[part 8 of 12: package /E40_Platform_System_SystemPackage/Components]
AUTOSAR XML (schema 4-2-1)
package /E40_Platform_System_SystemPackage/Components  (continued)
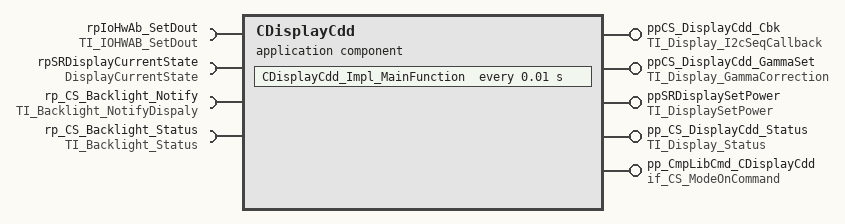
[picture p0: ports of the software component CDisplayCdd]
  application sw component type CDisplayCdd
    5 x provide port:
      ppCS_DisplayCdd_Cbk: server-com-spec{operation=I2cSeqEndCallback, queue-length=1}, provided-interface=TI_Display_I2cSeqCallback
      ppCS_DisplayCdd_GammaSet: provided-com-specs=[{operation=GetGammaCorrectionStatus, queue-length=1}, {operation=SetGammaCorrection, queue-length=1}], provided-interface=TI_Display_GammaCorrection
      ppSRDisplaySetPower: nonqueued-sender-com-spec{data-element=TI_DisplaySetPower/DisplaySetPowerData, init-value=constant-reference=CDisplayCddDisplaySetPowerDataValue0}, provided-interface=TI_DisplaySetPower
      pp_CS_DisplayCdd_Status: provided-com-specs=[{operation=TI_Display_Status/GetStatus, queue-length=1}, {operation=SetState, queue-length=1}], provided-interface=TI_Display_Status
      pp_CmpLibCmd_CDisplayCdd: server-com-spec{operation=Impl_OnCommand, queue-length=1}, provided-interface=if_CS_ModeOnCommand
    4 x require port:
      rpIoHwAb_SetDout: required-interface=TI_IOHWAB_SetDout
      rpSRDisplayCurrentState: nonqueued-receiver-com-spec{data-element=DisplayCurrentStateData, init-value=constant-reference=CDisplayCddDisplayCurrentStateDataValue0}, required-interface=DisplayCurrentState
      rp_CS_Backlight_Notify: required-interface=TI_Backlight_NotifyDispaly
      rp_CS_Backlight_Status: required-interface=TI_Backlight_Status
    behavior IB_CDisplayCdd
      operation invoked event OIE_ppCS_DisplayCdd_GammaSet_CDisplayCdd_GetGammaCorrectionStatusTrigByGetGammaCorrectionStatus: start-on-event=CDisplayCdd_GetGammaCorrectionStatus, operation=ppCS_DisplayCdd_GammaSet.GetGammaCorrectionStatus
      operation invoked event OIE_pp_CS_DisplayCdd_Status_CDisplayCdd_GetStatusTrigByGetStatus: start-on-event=CDisplayCdd_GetStatus, operation=pp_CS_DisplayCdd_Status.GetStatus
      operation invoked event OIE_ppCS_DisplayCdd_Cbk_CDisplayCdd_I2cSeqEndCallbackTrigByI2cSeqEndCallback: start-on-event=CDisplayCdd_I2cSeqEndCallback, operation=ppCS_DisplayCdd_Cbk.I2cSeqEndCallback
      timing event TECDisplayCdd_Impl_MainFunction: start-on-event=CDisplayCdd_Impl_MainFunction, period=0.01
      operation invoked event OIE_pp_CmpLibCmd_CDisplayCdd_CDisplayCdd_Impl_OnCommandTrigByImpl_OnCommand: start-on-event=CDisplayCdd_Impl_OnCommand, operation=pp_CmpLibCmd_CDisplayCdd.Impl_OnCommand
      operation invoked event OIE_ppCS_DisplayCdd_GammaSet_CDisplayCdd_SetGammaCorrectionTrigBySetGammaCorrection: start-on-event=CDisplayCdd_SetGammaCorrection, operation=ppCS_DisplayCdd_GammaSet.SetGammaCorrection
      operation invoked event OIE_pp_CS_DisplayCdd_Status_CDisplayCdd_SetStateTrigBySetState: start-on-event=CDisplayCdd_SetState, operation=pp_CS_DisplayCdd_Status.SetState
      port-api-options:
        enable-take-address=false, indirect-api=false, port=ppCS_DisplayCdd_Cbk
        enable-take-address=false, indirect-api=false, port=ppCS_DisplayCdd_GammaSet
        enable-take-address=false, indirect-api=false, port=ppSRDisplaySetPower
        enable-take-address=false, indirect-api=false, port=pp_CS_DisplayCdd_Status
        enable-take-address=false, indirect-api=false, port=pp_CmpLibCmd_CDisplayCdd
        enable-take-address=false, indirect-api=false, port=rpIoHwAb_SetDout
        enable-take-address=false, indirect-api=false, port=rpSRDisplayCurrentState
        enable-take-address=false, indirect-api=false, port=rp_CS_Backlight_Notify
        enable-take-address=false, indirect-api=false, port=rp_CS_Backlight_Status
      7 x runnable, all with can-be-invoked-concurrently=true:
        CDisplayCdd_GetGammaCorrectionStatus
        CDisplayCdd_GetStatus
          data-receive-point-by-arguments:
            access DRA_rpSRDisplayCurrentState_DisplayCurrentStateData: accessed-variable=rpSRDisplayCurrentState.DisplayCurrentStateData
          data-send-points:
            access DWA_ppSRDisplaySetPower_DisplaySetPowerData: accessed-variable=ppSRDisplaySetPower.DisplaySetPowerData
          4 x sync call, all with timeout=0.0:
            OA_rpIoHwAb_SetDout_SetOutputGroup: operation=rpIoHwAb_SetDout.SetOutputGroup
            OA_rpIoHwAb_SetDout_SetOutputPin: operation=rpIoHwAb_SetDout.SetOutputPin
            OA_rp_CS_Backlight_Notify_NotifyDisplayPowerState: operation=rp_CS_Backlight_Notify.NotifyDisplayPowerState
            OA_rp_CS_Backlight_Status_GetStatus: operation=rp_CS_Backlight_Status.GetStatus
        CDisplayCdd_I2cSeqEndCallback
        CDisplayCdd_Impl_MainFunction
          data-receive-point-by-arguments:
            access DRA_rpSRDisplayCurrentState_DisplayCurrentStateData: accessed-variable=rpSRDisplayCurrentState.DisplayCurrentStateData
          data-send-points:
            access DWA_ppSRDisplaySetPower_DisplaySetPowerData: accessed-variable=ppSRDisplaySetPower.DisplaySetPowerData
          4 x sync call, all with timeout=0.0:
            OA_rpIoHwAb_SetDout_SetOutputGroup: operation=rpIoHwAb_SetDout.SetOutputGroup
            OA_rpIoHwAb_SetDout_SetOutputPin: operation=rpIoHwAb_SetDout.SetOutputPin
            OA_rp_CS_Backlight_Notify_NotifyDisplayPowerState: operation=rp_CS_Backlight_Notify.NotifyDisplayPowerState
            OA_rp_CS_Backlight_Status_GetStatus: operation=rp_CS_Backlight_Status.GetStatus
        CDisplayCdd_Impl_OnCommand
          data-receive-point-by-arguments:
            access DRA_rpSRDisplayCurrentState_DisplayCurrentStateData: accessed-variable=rpSRDisplayCurrentState.DisplayCurrentStateData
          data-send-points:
            access DWA_ppSRDisplaySetPower_DisplaySetPowerData: accessed-variable=ppSRDisplaySetPower.DisplaySetPowerData
          4 x sync call, all with timeout=0.0:
            OA_rpIoHwAb_SetDout_SetOutputGroup: operation=rpIoHwAb_SetDout.SetOutputGroup
            OA_rpIoHwAb_SetDout_SetOutputPin: operation=rpIoHwAb_SetDout.SetOutputPin
            OA_rp_CS_Backlight_Notify_NotifyDisplayPowerState: operation=rp_CS_Backlight_Notify.NotifyDisplayPowerState
            OA_rp_CS_Backlight_Status_GetStatus: operation=rp_CS_Backlight_Status.GetStatus
        CDisplayCdd_SetGammaCorrection
        CDisplayCdd_SetState
          data-receive-point-by-arguments:
            access DRA_rpSRDisplayCurrentState_DisplayCurrentStateData: accessed-variable=rpSRDisplayCurrentState.DisplayCurrentStateData
          data-send-points:
            access DWA_ppSRDisplaySetPower_DisplaySetPowerData: accessed-variable=ppSRDisplaySetPower.DisplaySetPowerData
          4 x sync call, all with timeout=0.0:
            OA_rpIoHwAb_SetDout_SetOutputGroup: operation=rpIoHwAb_SetDout.SetOutputGroup
            OA_rpIoHwAb_SetDout_SetOutputPin: operation=rpIoHwAb_SetDout.SetOutputPin
            OA_rp_CS_Backlight_Notify_NotifyDisplayPowerState: operation=rp_CS_Backlight_Notify.NotifyDisplayPowerState
            OA_rp_CS_Backlight_Status_GetStatus: operation=rp_CS_Backlight_Status.GetStatus
  constant specification CDisplayCddDisplaySetPowerDataValue0: value-spec={short-label=CDisplayCddDisplaySetPowerDataValue0, fields=[CDisplayCddDisplaySetPowerDataValue_0:0, CDisplayCddDisplaySetPowerDataValue_1:0]}
  constant specification CDisplayCddDisplayCurrentStateDataValue0: value-spec={short-label=CDisplayCddDisplayCurrentStateDataValue0, fields=[CDisplayCddDisplayCurrentStateDataValue_0:0, CDisplayCddDisplayCurrentStateDataValue_1:0]}
  swc implementation IMPL_CDisplayCdd: programming-language=C, behavior=IB_CDisplayCdd
    code-descriptors:
      code CodeDescriptor
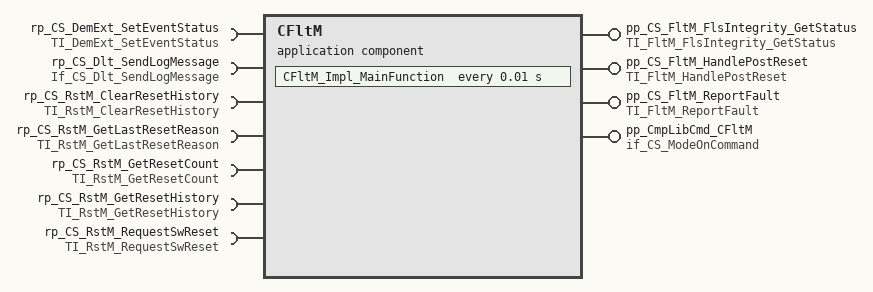
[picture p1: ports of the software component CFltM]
  application sw component type CFltM
    4 x provide port:
      pp_CS_FltM_FlsIntegrity_GetStatus: server-com-spec{operation=FltM_FlsIntegrity_GetStatus, queue-length=1}, provided-interface=TI_FltM_FlsIntegrity_GetStatus
      pp_CS_FltM_HandlePostReset: server-com-spec{operation=FltM_HandlePostReset, queue-length=1}, provided-interface=TI_FltM_HandlePostReset
      pp_CS_FltM_ReportFault: server-com-spec{operation=FltM_ReportFault, queue-length=1}, provided-interface=TI_FltM_ReportFault
      pp_CmpLibCmd_CFltM: server-com-spec{operation=Impl_OnCommand, queue-length=1}, provided-interface=if_CS_ModeOnCommand
    7 x require port:
      rp_CS_DemExt_SetEventStatus: required-interface=TI_DemExt_SetEventStatus
      rp_CS_Dlt_SendLogMessage: required-interface=If_CS_Dlt_SendLogMessage
      rp_CS_RstM_ClearResetHistory: required-interface=TI_RstM_ClearResetHistory
      rp_CS_RstM_GetLastResetReason: required-interface=TI_RstM_GetLastResetReason
      rp_CS_RstM_GetResetCount: required-interface=TI_RstM_GetResetCount
      rp_CS_RstM_GetResetHistory: required-interface=TI_RstM_GetResetHistory
      rp_CS_RstM_RequestSwReset: required-interface=TI_RstM_RequestSwReset
    behavior IB_CFltM
      operation invoked event OIE_pp_CS_FltM_FlsIntegrity_GetStatus_FltM_FlsIntegrity_GetStatusTrigByFltM_FlsIntegrity_GetStatus: start-on-event=FltM_FlsIntegrity_GetStatus, operation=pp_CS_FltM_FlsIntegrity_GetStatus.FltM_FlsIntegrity_GetStatus
      operation invoked event OIE_pp_CS_FltM_HandlePostReset_FltM_HandlePostResetTrigByFltM_HandlePostReset: start-on-event=FltM_HandlePostReset, operation=pp_CS_FltM_HandlePostReset.FltM_HandlePostReset
      operation invoked event OIE_pp_CS_FltM_ReportFault_FltM_ReportFaultTrigByFltM_ReportFault: start-on-event=FltM_ReportFault, operation=pp_CS_FltM_ReportFault.FltM_ReportFault
      timing event TECFltM_Impl_MainFunction: start-on-event=CFltM_Impl_MainFunction, period=0.01
      operation invoked event OIE_pp_CmpLibCmd_CFltM_CFltM_Impl_OnCommandTrigByImpl_OnCommand: start-on-event=CFltM_Impl_OnCommand, operation=pp_CmpLibCmd_CFltM.Impl_OnCommand
      port-api-options:
        enable-take-address=false, indirect-api=false, port=pp_CS_FltM_FlsIntegrity_GetStatus
        enable-take-address=false, indirect-api=false, port=pp_CS_FltM_HandlePostReset
        enable-take-address=false, indirect-api=false, port=pp_CS_FltM_ReportFault
        enable-take-address=false, indirect-api=false, port=pp_CmpLibCmd_CFltM
        enable-take-address=false, indirect-api=false, port=CFltM/rp_CS_DemExt_SetEventStatus
        enable-take-address=false, indirect-api=false, port=CFltM/rp_CS_Dlt_SendLogMessage
        enable-take-address=false, indirect-api=false, port=rp_CS_RstM_ClearResetHistory
        enable-take-address=false, indirect-api=false, port=rp_CS_RstM_GetLastResetReason
        enable-take-address=false, indirect-api=false, port=rp_CS_RstM_GetResetCount
        enable-take-address=false, indirect-api=false, port=rp_CS_RstM_GetResetHistory
        enable-take-address=false, indirect-api=false, port=rp_CS_RstM_RequestSwReset
      5 x runnable, all with can-be-invoked-concurrently=true:
        FltM_FlsIntegrity_GetStatus
          6 x sync call, all with timeout=0.0:
            OA_rp_CS_DemExt_SetEventStatus_DemExt_SetEventStatus: operation=rp_CS_DemExt_SetEventStatus.DemExt_SetEventStatus
            OA_rp_CS_RstM_ClearResetHistory_RstM_ClearResetHistory: operation=rp_CS_RstM_ClearResetHistory.RstM_ClearResetHistory
            OA_rp_CS_RstM_GetLastResetReason_RstM_GetLastResetReason: operation=rp_CS_RstM_GetLastResetReason.RstM_GetLastResetReason
            OA_rp_CS_RstM_GetResetCount_RstM_GetResetCount: operation=rp_CS_RstM_GetResetCount.RstM_GetResetCount
            OA_rp_CS_RstM_GetResetHistory_RstM_GetResetHistory: operation=rp_CS_RstM_GetResetHistory.RstM_GetResetHistory
            OA_rp_CS_RstM_RequestSwReset_RstM_RequestSwReset: operation=rp_CS_RstM_RequestSwReset.RstM_RequestSwReset
        FltM_HandlePostReset
          6 x sync call, all with timeout=0.0:
            OA_rp_CS_DemExt_SetEventStatus_DemExt_SetEventStatus: operation=rp_CS_DemExt_SetEventStatus.DemExt_SetEventStatus
            OA_rp_CS_RstM_ClearResetHistory_RstM_ClearResetHistory: operation=rp_CS_RstM_ClearResetHistory.RstM_ClearResetHistory
            OA_rp_CS_RstM_GetLastResetReason_RstM_GetLastResetReason: operation=rp_CS_RstM_GetLastResetReason.RstM_GetLastResetReason
            OA_rp_CS_RstM_GetResetCount_RstM_GetResetCount: operation=rp_CS_RstM_GetResetCount.RstM_GetResetCount
            OA_rp_CS_RstM_GetResetHistory_RstM_GetResetHistory: operation=rp_CS_RstM_GetResetHistory.RstM_GetResetHistory
            OA_rp_CS_RstM_RequestSwReset_RstM_RequestSwReset: operation=rp_CS_RstM_RequestSwReset.RstM_RequestSwReset
        FltM_ReportFault
          6 x sync call, all with timeout=0.0:
            OA_rp_CS_DemExt_SetEventStatus_DemExt_SetEventStatus: operation=rp_CS_DemExt_SetEventStatus.DemExt_SetEventStatus
            OA_rp_CS_RstM_ClearResetHistory_RstM_ClearResetHistory: operation=rp_CS_RstM_ClearResetHistory.RstM_ClearResetHistory
            OA_rp_CS_RstM_GetLastResetReason_RstM_GetLastResetReason: operation=rp_CS_RstM_GetLastResetReason.RstM_GetLastResetReason
            OA_rp_CS_RstM_GetResetCount_RstM_GetResetCount: operation=rp_CS_RstM_GetResetCount.RstM_GetResetCount
            OA_rp_CS_RstM_GetResetHistory_RstM_GetResetHistory: operation=rp_CS_RstM_GetResetHistory.RstM_GetResetHistory
            OA_rp_CS_RstM_RequestSwReset_RstM_RequestSwReset: operation=rp_CS_RstM_RequestSwReset.RstM_RequestSwReset
        CFltM_Impl_MainFunction
          6 x sync call, all with timeout=0.0:
            OA_rp_CS_DemExt_SetEventStatus_DemExt_SetEventStatus: operation=rp_CS_DemExt_SetEventStatus.DemExt_SetEventStatus
            OA_rp_CS_RstM_ClearResetHistory_RstM_ClearResetHistory: operation=rp_CS_RstM_ClearResetHistory.RstM_ClearResetHistory
            OA_rp_CS_RstM_GetLastResetReason_RstM_GetLastResetReason: operation=rp_CS_RstM_GetLastResetReason.RstM_GetLastResetReason
            OA_rp_CS_RstM_GetResetCount_RstM_GetResetCount: operation=rp_CS_RstM_GetResetCount.RstM_GetResetCount
            OA_rp_CS_RstM_GetResetHistory_RstM_GetResetHistory: operation=rp_CS_RstM_GetResetHistory.RstM_GetResetHistory
            OA_rp_CS_RstM_RequestSwReset_RstM_RequestSwReset: operation=rp_CS_RstM_RequestSwReset.RstM_RequestSwReset
        CFltM_Impl_OnCommand
          6 x sync call, all with timeout=0.0:
            OA_rp_CS_DemExt_SetEventStatus_DemExt_SetEventStatus: operation=rp_CS_DemExt_SetEventStatus.DemExt_SetEventStatus
            OA_rp_CS_RstM_ClearResetHistory_RstM_ClearResetHistory: operation=rp_CS_RstM_ClearResetHistory.RstM_ClearResetHistory
            OA_rp_CS_RstM_GetLastResetReason_RstM_GetLastResetReason: operation=rp_CS_RstM_GetLastResetReason.RstM_GetLastResetReason
            OA_rp_CS_RstM_GetResetCount_RstM_GetResetCount: operation=rp_CS_RstM_GetResetCount.RstM_GetResetCount
            OA_rp_CS_RstM_GetResetHistory_RstM_GetResetHistory: operation=rp_CS_RstM_GetResetHistory.RstM_GetResetHistory
            OA_rp_CS_RstM_RequestSwReset_RstM_RequestSwReset: operation=rp_CS_RstM_RequestSwReset.RstM_RequestSwReset
  swc implementation IMPL_CFltM: programming-language=C, behavior=IB_CFltM
    code-descriptors:
      code CodeDescriptor
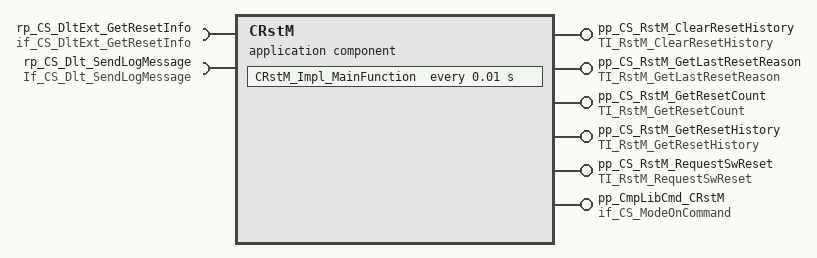
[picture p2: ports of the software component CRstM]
  application sw component type CRstM
    6 x provide port:
      pp_CS_RstM_ClearResetHistory: server-com-spec{operation=RstM_ClearResetHistory, queue-length=1}, provided-interface=TI_RstM_ClearResetHistory
      pp_CS_RstM_GetLastResetReason: server-com-spec{operation=RstM_GetLastResetReason, queue-length=1}, provided-interface=TI_RstM_GetLastResetReason
      pp_CS_RstM_GetResetCount: server-com-spec{operation=RstM_GetResetCount, queue-length=1}, provided-interface=TI_RstM_GetResetCount
      pp_CS_RstM_GetResetHistory: server-com-spec{operation=RstM_GetResetHistory, queue-length=1}, provided-interface=TI_RstM_GetResetHistory
      pp_CS_RstM_RequestSwReset: server-com-spec{operation=RstM_RequestSwReset, queue-length=1}, provided-interface=TI_RstM_RequestSwReset
      pp_CmpLibCmd_CRstM: server-com-spec{operation=Impl_OnCommand, queue-length=1}, provided-interface=if_CS_ModeOnCommand
    require port rp_CS_DltExt_GetResetInfo: required-interface=if_CS_DltExt_GetResetInfo
    require port rp_CS_Dlt_SendLogMessage: required-interface=If_CS_Dlt_SendLogMessage
    behavior IB_CRstM
      timing event TECRstM_Impl_MainFunction: start-on-event=CRstM_Impl_MainFunction, period=0.01
      6 x operation invoked event:
        OIE_pp_CmpLibCmd_CRstM_CRstM_Impl_OnCommandTrigByImpl_OnCommand: start-on-event=CRstM_Impl_OnCommand, operation=pp_CmpLibCmd_CRstM.Impl_OnCommand
        OIE_pp_CS_RstM_ClearResetHistory_RstM_ClearResetHistoryTrigByRstM_ClearResetHistory: start-on-event=RstM_ClearResetHistory, operation=pp_CS_RstM_ClearResetHistory.RstM_ClearResetHistory
        OIE_pp_CS_RstM_GetLastResetReason_RstM_GetLastResetReasonTrigByRstM_GetLastResetReason: start-on-event=RstM_GetLastResetReason, operation=pp_CS_RstM_GetLastResetReason.RstM_GetLastResetReason
        OIE_pp_CS_RstM_GetResetCount_RstM_GetResetCountTrigByRstM_GetResetCount: start-on-event=RstM_GetResetCount, operation=pp_CS_RstM_GetResetCount.RstM_GetResetCount
        OIE_pp_CS_RstM_GetResetHistory_RstM_GetResetHistoryTrigByRstM_GetResetHistory: start-on-event=RstM_GetResetHistory, operation=pp_CS_RstM_GetResetHistory.RstM_GetResetHistory
        OIE_pp_CS_RstM_RequestSwReset_RstM_RequestSwResetTrigByRstM_RequestSwReset: start-on-event=RstM_RequestSwReset, operation=pp_CS_RstM_RequestSwReset.RstM_RequestSwReset
      port-api-options:
        enable-take-address=false, indirect-api=false, port=pp_CS_RstM_ClearResetHistory
        enable-take-address=false, indirect-api=false, port=pp_CS_RstM_GetLastResetReason
        enable-take-address=false, indirect-api=false, port=pp_CS_RstM_GetResetCount
        enable-take-address=false, indirect-api=false, port=pp_CS_RstM_GetResetHistory
        enable-take-address=false, indirect-api=false, port=pp_CS_RstM_RequestSwReset
        enable-take-address=false, indirect-api=false, port=pp_CmpLibCmd_CRstM
        enable-take-address=false, indirect-api=false, port=rp_CS_DltExt_GetResetInfo
        enable-take-address=false, indirect-api=false, port=CRstM/rp_CS_Dlt_SendLogMessage
      7 x runnable, all with can-be-invoked-concurrently=true:
        CRstM_Impl_MainFunction
        CRstM_Impl_OnCommand
        RstM_ClearResetHistory
        RstM_GetLastResetReason
        RstM_GetResetCount
        RstM_GetResetHistory
        RstM_RequestSwReset
  swc implementation IMPL_CRstM: programming-language=C, behavior=IB_CRstM
    code-descriptors:
      code CodeDescriptor
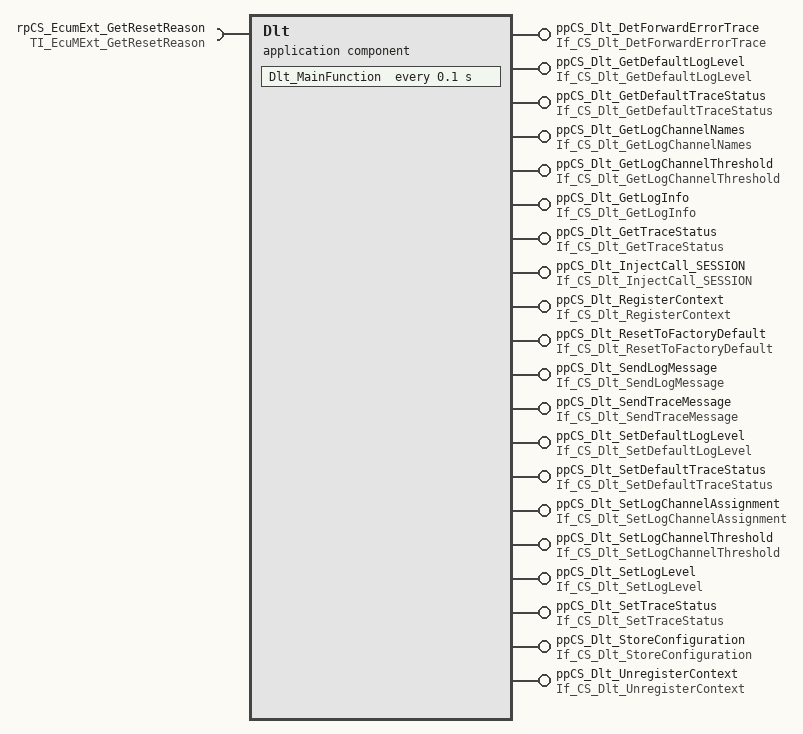
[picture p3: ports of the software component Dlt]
  application sw component type Dlt
    20 x provide port:
      ppCS_Dlt_DetForwardErrorTrace: server-com-spec{operation=DetForwardErrorTrace, queue-length=1}, provided-interface=If_CS_Dlt_DetForwardErrorTrace
      ppCS_Dlt_GetDefaultLogLevel: server-com-spec{operation=GetDefaultLogLevel, queue-length=1}, provided-interface=If_CS_Dlt_GetDefaultLogLevel
      ppCS_Dlt_GetDefaultTraceStatus: server-com-spec{operation=GetDefaultTraceStatus, queue-length=1}, provided-interface=If_CS_Dlt_GetDefaultTraceStatus
      ppCS_Dlt_GetLogChannelNames: server-com-spec{operation=GetLogChannelNames, queue-length=1}, provided-interface=If_CS_Dlt_GetLogChannelNames
      ppCS_Dlt_GetLogChannelThreshold: server-com-spec{operation=GetLogChannelThreshold, queue-length=1}, provided-interface=If_CS_Dlt_GetLogChannelThreshold
      ppCS_Dlt_GetLogInfo: server-com-spec{operation=GetLogInfo, queue-length=1}, provided-interface=If_CS_Dlt_GetLogInfo
      ppCS_Dlt_GetTraceStatus: server-com-spec{operation=GetTraceStatus, queue-length=1}, provided-interface=If_CS_Dlt_GetTraceStatus
      ppCS_Dlt_InjectCall_SESSION: server-com-spec{operation=InjectCall_SESSION, queue-length=1}, provided-interface=If_CS_Dlt_InjectCall_SESSION
      ppCS_Dlt_RegisterContext: server-com-spec{operation=RegisterContext, queue-length=1}, provided-interface=If_CS_Dlt_RegisterContext
      ppCS_Dlt_ResetToFactoryDefault: server-com-spec{operation=ResetToFactoryDefault, queue-length=1}, provided-interface=If_CS_Dlt_ResetToFactoryDefault
      ppCS_Dlt_SendLogMessage: server-com-spec{operation=If_CS_Dlt_SendLogMessage/SendLogMessage, queue-length=1}, provided-interface=If_CS_Dlt_SendLogMessage
      ppCS_Dlt_SendTraceMessage: server-com-spec{operation=SendTraceMessage, queue-length=1}, provided-interface=If_CS_Dlt_SendTraceMessage
      ppCS_Dlt_SetDefaultLogLevel: server-com-spec{operation=SetDefaultLogLevel, queue-length=1}, provided-interface=If_CS_Dlt_SetDefaultLogLevel
      ppCS_Dlt_SetDefaultTraceStatus: server-com-spec{operation=SetDefaultTraceStatus, queue-length=1}, provided-interface=If_CS_Dlt_SetDefaultTraceStatus
      ppCS_Dlt_SetLogChannelAssignment: server-com-spec{operation=SetLogChannelAssignment, queue-length=1}, provided-interface=If_CS_Dlt_SetLogChannelAssignment
      ppCS_Dlt_SetLogChannelThreshold: server-com-spec{operation=SetLogChannelThreshold, queue-length=1}, provided-interface=If_CS_Dlt_SetLogChannelThreshold
      ppCS_Dlt_SetLogLevel: server-com-spec{operation=SetLogLevel, queue-length=1}, provided-interface=If_CS_Dlt_SetLogLevel
      ppCS_Dlt_SetTraceStatus: server-com-spec{operation=SetTraceStatus, queue-length=1}, provided-interface=If_CS_Dlt_SetTraceStatus
      ppCS_Dlt_StoreConfiguration: server-com-spec{operation=StoreConfiguration, queue-length=1}, provided-interface=If_CS_Dlt_StoreConfiguration
      ppCS_Dlt_UnregisterContext: server-com-spec{operation=UnregisterContext, queue-length=1}, provided-interface=If_CS_Dlt_UnregisterContext
    require port rpCS_EcumExt_GetResetReason: required-interface=TI_EcuMExt_GetResetReason
    behavior IB_Dlt
      8 x operation invoked event:
        OIE_ppCS_Dlt_DetForwardErrorTrace_Dlt_DetForwardErrorTraceTrigByDetForwardErrorTrace: start-on-event=Dlt_DetForwardErrorTrace, operation=ppCS_Dlt_DetForwardErrorTrace.DetForwardErrorTrace
        OIE_ppCS_Dlt_GetDefaultLogLevel_Dlt_GetDefaultLogLevelTrigByGetDefaultLogLevel: start-on-event=Dlt_GetDefaultLogLevel, operation=ppCS_Dlt_GetDefaultLogLevel.GetDefaultLogLevel
        OIE_ppCS_Dlt_GetDefaultTraceStatus_Dlt_GetDefaultTraceStatusTrigByGetDefaultTraceStatus: start-on-event=Dlt_GetDefaultTraceStatus, operation=ppCS_Dlt_GetDefaultTraceStatus.GetDefaultTraceStatus
        OIE_ppCS_Dlt_GetLogChannelNames_Dlt_GetLogChannelNamesTrigByGetLogChannelNames: start-on-event=Dlt_GetLogChannelNames, operation=ppCS_Dlt_GetLogChannelNames.GetLogChannelNames
        OIE_ppCS_Dlt_GetLogChannelThreshold_Dlt_GetLogChannelThresholdTrigByGetLogChannelThreshold: start-on-event=Dlt_GetLogChannelThreshold, operation=ppCS_Dlt_GetLogChannelThreshold.GetLogChannelThreshold
        OIE_ppCS_Dlt_GetLogInfo_Dlt_GetLogInfoTrigByGetLogInfo: start-on-event=Dlt_GetLogInfo, operation=ppCS_Dlt_GetLogInfo.GetLogInfo
        OIE_ppCS_Dlt_GetTraceStatus_Dlt_GetTraceStatusTrigByGetTraceStatus: start-on-event=Dlt_GetTraceStatus, operation=ppCS_Dlt_GetTraceStatus.GetTraceStatus
        OIE_ppCS_Dlt_InjectCall_SESSION_Dlt_InjectCall_SESSIONTrigByInjectCall_SESSION: start-on-event=Dlt_InjectCall_SESSION, operation=ppCS_Dlt_InjectCall_SESSION.InjectCall_SESSION
      timing event TEDlt_MainFunction: start-on-event=Dlt_MainFunction, period=0.1
      12 x operation invoked event:
        OIE_ppCS_Dlt_RegisterContext_Dlt_RegisterContextTrigByRegisterContext: start-on-event=Dlt_RegisterContext, operation=ppCS_Dlt_RegisterContext.RegisterContext
        OIE_ppCS_Dlt_ResetToFactoryDefault_Dlt_ResetToFactoryDefaultTrigByResetToFactoryDefault: start-on-event=Dlt_ResetToFactoryDefault, operation=ppCS_Dlt_ResetToFactoryDefault.ResetToFactoryDefault
        OIE_ppCS_Dlt_SendLogMessage_Dlt_SendLogMessageTrigBySendLogMessage: start-on-event=Dlt_SendLogMessage, operation=ppCS_Dlt_SendLogMessage.SendLogMessage
        OIE_ppCS_Dlt_SendTraceMessage_Dlt_SendTraceMessageTrigBySendTraceMessage: start-on-event=Dlt_SendTraceMessage, operation=ppCS_Dlt_SendTraceMessage.SendTraceMessage
        OIE_ppCS_Dlt_SetDefaultLogLevel_Dlt_SetDefaultLogLevelTrigBySetDefaultLogLevel: start-on-event=Dlt_SetDefaultLogLevel, operation=ppCS_Dlt_SetDefaultLogLevel.SetDefaultLogLevel
        OIE_ppCS_Dlt_SetDefaultTraceStatus_Dlt_SetDefaultTraceStatusTrigBySetDefaultTraceStatus: start-on-event=Dlt_SetDefaultTraceStatus, operation=ppCS_Dlt_SetDefaultTraceStatus.SetDefaultTraceStatus
        OIE_ppCS_Dlt_SetLogChannelAssignment_Dlt_SetLogChannelAssignmentTrigBySetLogChannelAssignment: start-on-event=Dlt_SetLogChannelAssignment, operation=ppCS_Dlt_SetLogChannelAssignment.SetLogChannelAssignment
        OIE_ppCS_Dlt_SetLogChannelThreshold_Dlt_SetLogChannelThresholdTrigBySetLogChannelThreshold: start-on-event=Dlt_SetLogChannelThreshold, operation=ppCS_Dlt_SetLogChannelThreshold.SetLogChannelThreshold
        OIE_ppCS_Dlt_SetLogLevel_Dlt_SetLogLevelTrigBySetLogLevel: start-on-event=Dlt_SetLogLevel, operation=ppCS_Dlt_SetLogLevel.SetLogLevel
        OIE_ppCS_Dlt_SetTraceStatus_Dlt_SetTraceStatusTrigBySetTraceStatus: start-on-event=Dlt_SetTraceStatus, operation=ppCS_Dlt_SetTraceStatus.SetTraceStatus
        OIE_ppCS_Dlt_StoreConfiguration_Dlt_StoreConfigurationTrigByStoreConfiguration: start-on-event=Dlt_StoreConfiguration, operation=ppCS_Dlt_StoreConfiguration.StoreConfiguration
        OIE_ppCS_Dlt_UnregisterContext_Dlt_UnregisterContextTrigByUnregisterContext: start-on-event=Dlt_UnregisterContext, operation=ppCS_Dlt_UnregisterContext.UnregisterContext
      port-api-options:
        enable-take-address=false, indirect-api=false, port=ppCS_Dlt_DetForwardErrorTrace
        enable-take-address=false, indirect-api=false, port=ppCS_Dlt_GetDefaultLogLevel
        enable-take-address=false, indirect-api=false, port=ppCS_Dlt_GetDefaultTraceStatus
        enable-take-address=false, indirect-api=false, port=ppCS_Dlt_GetLogChannelNames
        enable-take-address=false, indirect-api=false, port=ppCS_Dlt_GetLogChannelThreshold
        enable-take-address=false, indirect-api=false, port=ppCS_Dlt_GetLogInfo
        enable-take-address=false, indirect-api=false, port=ppCS_Dlt_GetTraceStatus
        enable-take-address=false, indirect-api=false, port=ppCS_Dlt_InjectCall_SESSION
        enable-take-address=false, indirect-api=false, port=ppCS_Dlt_RegisterContext
        enable-take-address=false, indirect-api=false, port=ppCS_Dlt_ResetToFactoryDefault
        enable-take-address=false, indirect-api=false, port=ppCS_Dlt_SendLogMessage
        enable-take-address=false, indirect-api=false, port=ppCS_Dlt_SendTraceMessage
        enable-take-address=false, indirect-api=false, port=ppCS_Dlt_SetDefaultLogLevel
        enable-take-address=false, indirect-api=false, port=ppCS_Dlt_SetDefaultTraceStatus
        enable-take-address=false, indirect-api=false, port=ppCS_Dlt_SetLogChannelAssignment
        enable-take-address=false, indirect-api=false, port=ppCS_Dlt_SetLogChannelThreshold
        enable-take-address=false, indirect-api=false, port=ppCS_Dlt_SetLogLevel
        enable-take-address=false, indirect-api=false, port=ppCS_Dlt_SetTraceStatus
        enable-take-address=false, indirect-api=false, port=ppCS_Dlt_StoreConfiguration
        enable-take-address=false, indirect-api=false, port=ppCS_Dlt_UnregisterContext
        enable-take-address=false, indirect-api=false, port=rpCS_EcumExt_GetResetReason
      21 x runnable, all with can-be-invoked-concurrently=true:
        Dlt_DetForwardErrorTrace
        Dlt_GetDefaultLogLevel
        Dlt_GetDefaultTraceStatus
        Dlt_GetLogChannelNames
        Dlt_GetLogChannelThreshold
        Dlt_GetLogInfo
        Dlt_GetTraceStatus
        Dlt_InjectCall_SESSION
        Dlt_MainFunction
          sync call OA_rpCS_EcumExt_GetResetReason_GetResetReason: operation=rpCS_EcumExt_GetResetReason.GetResetReason, timeout=0.0
        Dlt_RegisterContext
        Dlt_ResetToFactoryDefault
        Dlt_SendLogMessage
        Dlt_SendTraceMessage
        Dlt_SetDefaultLogLevel
        Dlt_SetDefaultTraceStatus
        Dlt_SetLogChannelAssignment
        Dlt_SetLogChannelThreshold
        Dlt_SetLogLevel
        Dlt_SetTraceStatus
        Dlt_StoreConfiguration
        Dlt_UnregisterContext
  swc implementation IMPL_Dlt: programming-language=C, behavior=IB_Dlt
    code-descriptors:
      code CodeDescriptor
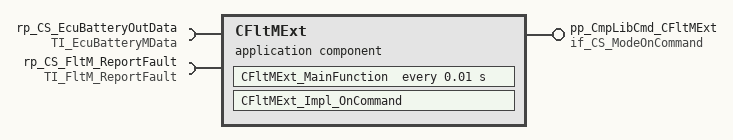
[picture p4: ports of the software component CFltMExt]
  application sw component type CFltMExt
    provide port pp_CmpLibCmd_CFltMExt: server-com-spec{operation=Impl_OnCommand, queue-length=1}, provided-interface=if_CS_ModeOnCommand
    require port rp_CS_EcuBatteryOutData: required-interface=TI_EcuBatteryMData
    require port rp_CS_FltM_ReportFault: required-interface=TI_FltM_ReportFault
    behavior IB_CFltMExt
      operation invoked event OIE_pp_CmpLibCmd_CFltMExt_CFltMExt_Impl_OnCommandTrigByImpl_OnCommand: start-on-event=CFltMExt_Impl_OnCommand, operation=pp_CmpLibCmd_CFltMExt.Impl_OnCommand
      timing event TECFltMExt_MainFunction: start-on-event=CFltMExt_MainFunction, period=0.01
      port-api-options:
        enable-take-address=false, indirect-api=false, port=pp_CmpLibCmd_CFltMExt
        enable-take-address=false, indirect-api=false, port=CFltMExt/rp_CS_EcuBatteryOutData
        enable-take-address=false, indirect-api=false, port=rp_CS_FltM_ReportFault
      runnable CFltMExt_Impl_OnCommand: can-be-invoked-concurrently=true
        sync call OA_rp_CS_EcuBatteryOutData_EcuBatteryM_GetChannelStatus: operation=rp_CS_EcuBatteryOutData.EcuBatteryM_GetChannelStatus, timeout=0.0
        sync call OA_rp_CS_EcuBatteryOutData_EcuBatteryM_GetDIOStatus: operation=rp_CS_EcuBatteryOutData.EcuBatteryM_GetDIOStatus, timeout=0.0
        sync call OA_rp_CS_FltM_ReportFault_FltM_ReportFault: operation=rp_CS_FltM_ReportFault.FltM_ReportFault, timeout=0.0
      runnable CFltMExt_MainFunction: can-be-invoked-concurrently=true
        sync call OA_rp_CS_EcuBatteryOutData_EcuBatteryM_GetChannelStatus: operation=rp_CS_EcuBatteryOutData.EcuBatteryM_GetChannelStatus, timeout=0.0
        sync call OA_rp_CS_EcuBatteryOutData_EcuBatteryM_GetDIOStatus: operation=rp_CS_EcuBatteryOutData.EcuBatteryM_GetDIOStatus, timeout=0.0
        sync call OA_rp_CS_FltM_ReportFault_FltM_ReportFault: operation=rp_CS_FltM_ReportFault.FltM_ReportFault, timeout=0.0
  swc implementation IMPL_CFltMExt: programming-language=C, behavior=IB_CFltMExt
    code-descriptors:
      code CodeDescriptor
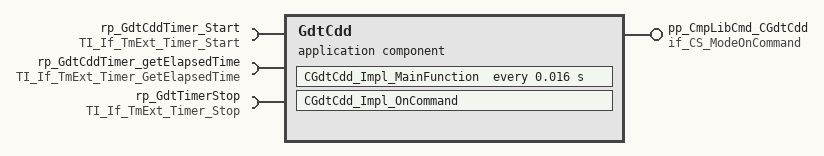
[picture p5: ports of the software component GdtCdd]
  application sw component type GdtCdd
    provide port pp_CmpLibCmd_CGdtCdd: server-com-spec{operation=Impl_OnCommand, queue-length=1}, provided-interface=if_CS_ModeOnCommand
    require port rp_GdtCddTimer_Start: required-interface=TI_If_TmExt_Timer_Start
    require port rp_GdtCddTimer_getElapsedTime: required-interface=TI_If_TmExt_Timer_GetElapsedTime
    require port rp_GdtTimerStop: required-interface=TI_If_TmExt_Timer_Stop
    behavior IB_GdtCdd
      timing event TECGdtCdd_Impl_MainFunction: start-on-event=CGdtCdd_Impl_MainFunction, period=0.016
      operation invoked event OIE_pp_CmpLibCmd_CGdtCdd_CGdtCdd_Impl_OnCommandTrigByImpl_OnCommand: start-on-event=CGdtCdd_Impl_OnCommand, operation=pp_CmpLibCmd_CGdtCdd.Impl_OnCommand
      port-api-options:
        enable-take-address=false, indirect-api=false, port=pp_CmpLibCmd_CGdtCdd
        enable-take-address=false, indirect-api=false, port=rp_GdtCddTimer_Start
        enable-take-address=false, indirect-api=false, port=rp_GdtCddTimer_getElapsedTime
        enable-take-address=false, indirect-api=false, port=rp_GdtTimerStop
      runnable CGdtCdd_Impl_MainFunction: can-be-invoked-concurrently=true
        sync call OA_rp_GdtCddTimer_Start_Timer_Start: operation=rp_GdtCddTimer_Start.Timer_Start, timeout=0.0
        sync call OA_rp_GdtCddTimer_getElapsedTime_Timer_GetElapsedTime: operation=rp_GdtCddTimer_getElapsedTime.Timer_GetElapsedTime, timeout=0.0
        sync call OA_rp_GdtTimerStop_Timer_Stop: operation=rp_GdtTimerStop.Timer_Stop, timeout=0.0
      runnable CGdtCdd_Impl_OnCommand: can-be-invoked-concurrently=true
  swc implementation IMPL_GdtCdd: programming-language=C, behavior=IB_GdtCdd
    code-descriptors:
      code CodeDescriptor
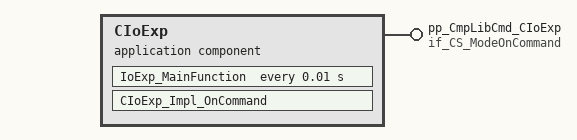
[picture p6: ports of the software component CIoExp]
  application sw component type CIoExp
    provide port pp_CmpLibCmd_CIoExp: server-com-spec{operation=Impl_OnCommand, queue-length=1}, provided-interface=if_CS_ModeOnCommand
    behavior IB_CIoExp: port-api-option{enable-take-address=false, indirect-api=false, port=pp_CmpLibCmd_CIoExp}
      operation invoked event OIE_pp_CmpLibCmd_CIoExp_CIoExp_Impl_OnCommandTrigByImpl_OnCommand: start-on-event=CIoExp_Impl_OnCommand, operation=pp_CmpLibCmd_CIoExp.Impl_OnCommand
      timing event TEIoExp_MainFunction: start-on-event=IoExp_MainFunction, period=0.01
      runnable CIoExp_Impl_OnCommand: can-be-invoked-concurrently=true
      runnable IoExp_MainFunction: can-be-invoked-concurrently=true
  swc implementation IMPL_CIoExp: programming-language=C, behavior=IB_CIoExp
    code-descriptors:
      code CodeDescriptor
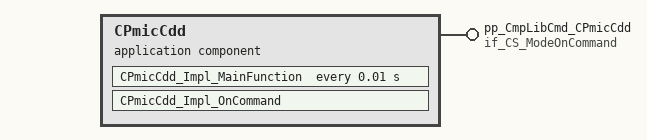
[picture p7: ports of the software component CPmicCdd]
  application sw component type CPmicCdd
    provide port pp_CmpLibCmd_CPmicCdd: server-com-spec{operation=Impl_OnCommand, queue-length=1}, provided-interface=if_CS_ModeOnCommand
    behavior IB_CPmicCdd: port-api-option{enable-take-address=false, indirect-api=false, port=pp_CmpLibCmd_CPmicCdd}
      timing event TECPmicCdd_Impl_MainFunction: start-on-event=CPmicCdd_Impl_MainFunction, period=0.01
      operation invoked event OIE_pp_CmpLibCmd_CPmicCdd_CPmicCdd_Impl_OnCommandTrigByImpl_OnCommand: start-on-event=CPmicCdd_Impl_OnCommand, operation=pp_CmpLibCmd_CPmicCdd.Impl_OnCommand
      runnable CPmicCdd_Impl_MainFunction: can-be-invoked-concurrently=true
      runnable CPmicCdd_Impl_OnCommand: can-be-invoked-concurrently=true
  swc implementation IMPL_CPmicCdd: programming-language=C, behavior=IB_CPmicCdd
    code-descriptors:
      code CodeDescriptor
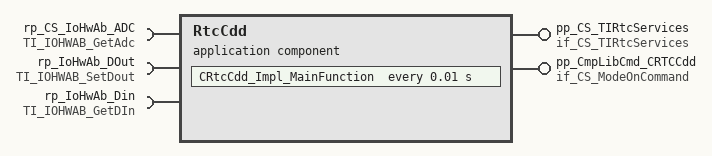
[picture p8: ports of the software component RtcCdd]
  application sw component type RtcCdd
    provide port pp_CS_TIRtcServices: provided-interface=if_CS_TIRtcServices
      provided-com-specs:
        operation=RtcCdd_ClearAlarm, queue-length=1
        operation=RtcCdd_GetTime, queue-length=1
        operation=RtcCdd_SetAlarm, queue-length=1
        operation=RtcCdd_SetTime, queue-length=1
    provide port pp_CmpLibCmd_CRTCCdd: server-com-spec{operation=Impl_OnCommand, queue-length=1}, provided-interface=if_CS_ModeOnCommand
    require port rp_CS_IoHwAb_ADC: required-interface=TI_IOHWAB_GetAdc
    require port rp_IoHwAb_DOut: required-interface=TI_IOHWAB_SetDout
    require port rp_IoHwAb_Din: required-interface=TI_IOHWAB_GetDIn
    behavior IB_RtcCdd
      timing event TECRtcCdd_Impl_MainFunction: start-on-event=CRtcCdd_Impl_MainFunction, period=0.01
      5 x operation invoked event:
        OIE_pp_CmpLibCmd_CRTCCdd_CRtcCdd_Impl_OnCommandTrigByImpl_OnCommand: start-on-event=CRtcCdd_Impl_OnCommand, operation=pp_CmpLibCmd_CRTCCdd.Impl_OnCommand
        OIE_pp_CS_TIRtcServices_RtcCdd_ClearAlarmTrigByRtcCdd_ClearAlarm: start-on-event=RtcCdd_ClearAlarm, operation=pp_CS_TIRtcServices.RtcCdd_ClearAlarm
        OIE_pp_CS_TIRtcServices_RtcCdd_GetTimeTrigByRtcCdd_GetTime: start-on-event=RtcCdd_GetTime, operation=pp_CS_TIRtcServices.RtcCdd_GetTime
        OIE_pp_CS_TIRtcServices_RtcCdd_SetAlarmTrigByRtcCdd_SetAlarm: start-on-event=RtcCdd_SetAlarm, operation=pp_CS_TIRtcServices.RtcCdd_SetAlarm
        OIE_pp_CS_TIRtcServices_RtcCdd_SetTimeTrigByRtcCdd_SetTime: start-on-event=RtcCdd_SetTime, operation=pp_CS_TIRtcServices.RtcCdd_SetTime
      port-api-options:
        enable-take-address=false, indirect-api=false, port=pp_CS_TIRtcServices
        enable-take-address=false, indirect-api=false, port=pp_CmpLibCmd_CRTCCdd
        enable-take-address=false, indirect-api=false, port=rp_CS_IoHwAb_ADC
        enable-take-address=false, indirect-api=false, port=rp_IoHwAb_DOut
        enable-take-address=false, indirect-api=false, port=rp_IoHwAb_Din
      6 x runnable, all with can-be-invoked-concurrently=true:
        CRtcCdd_Impl_MainFunction
          9 x sync call, all with timeout=0.0:
            OA_rp_CS_IoHwAb_ADC_GetAsyncRawAdc: operation=rp_CS_IoHwAb_ADC.GetAsyncRawAdc
            OA_rp_CS_IoHwAb_ADC_GetSyncRawAdc: operation=rp_CS_IoHwAb_ADC.GetSyncRawAdc
            OA_rp_CS_IoHwAb_ADC_GetProcessedAdc: operation=rp_CS_IoHwAb_ADC.GetProcessedAdc
            OA_rp_IoHwAb_DOut_SetOutputGroup: operation=rp_IoHwAb_DOut.SetOutputGroup
            OA_rp_IoHwAb_DOut_SetOutputPin: operation=rp_IoHwAb_DOut.SetOutputPin
            OA_rp_IoHwAb_Din_GetAsyncRawInput: operation=rp_IoHwAb_Din.GetAsyncRawInput
            OA_rp_IoHwAb_Din_GetProcessedInput: operation=rp_IoHwAb_Din.GetProcessedInput
            OA_rp_IoHwAb_Din_GetSyncRawInput: operation=rp_IoHwAb_Din.GetSyncRawInput
            OA_rp_IoHwAb_Din_GetInputGroup: operation=rp_IoHwAb_Din.GetInputGroup
        CRtcCdd_Impl_OnCommand
        RtcCdd_ClearAlarm
        RtcCdd_GetTime
        RtcCdd_SetAlarm
        RtcCdd_SetTime
  swc implementation IMPL_RtcCdd: programming-language=C, behavior=IB_RtcCdd
    code-descriptors:
      code CodeDescriptor
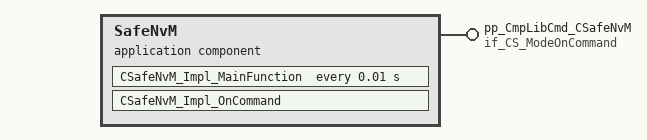
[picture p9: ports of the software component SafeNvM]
  application sw component type SafeNvM
    provide port pp_CmpLibCmd_CSafeNvM: server-com-spec{operation=Impl_OnCommand, queue-length=1}, provided-interface=if_CS_ModeOnCommand
    behavior IB_SafeNvM: port-api-option{enable-take-address=false, indirect-api=false, port=pp_CmpLibCmd_CSafeNvM}
      timing event TECSafeNvM_Impl_MainFunction: start-on-event=CSafeNvM_Impl_MainFunction, period=0.01
      operation invoked event OIE_pp_CmpLibCmd_CSafeNvM_CSafeNvM_Impl_OnCommandTrigByImpl_OnCommand: start-on-event=CSafeNvM_Impl_OnCommand, operation=pp_CmpLibCmd_CSafeNvM.Impl_OnCommand
      runnable CSafeNvM_Impl_MainFunction: can-be-invoked-concurrently=true
      runnable CSafeNvM_Impl_OnCommand: can-be-invoked-concurrently=true
  swc implementation IMPL_SafeNvM: programming-language=C, behavior=IB_SafeNvM
    code-descriptors:
      code CodeDescriptor
  application sw component type CSigCdd
    provide port pp_CmpLibCmd_CSigCdd: server-com-spec{operation=Impl_OnCommand, queue-length=1}, provided-interface=if_CS_ModeOnCommand
    provide port pp_SigCddCrc: server-com-spec{operation=Impl_sig_get_win_crc_data, queue-length=1}, provided-interface=TI_SigCddCrc
    provide port pp_SigCddSts: nonqueued-sender-com-spec{data-element=win_violation_output, init-value=constant-reference=CSigCddwin_violation_outputValue0}, provided-interface=TI_SigCddSts
    require port rp_SigData: nonqueued-receiver-com-spec{data-element=sig0_port, init-value=constant-reference=CSigCddsig0_portValue0}, required-interface=TI_SigData
    behavior IB_CSigCdd
      timing event TECSigCdd_Impl_MainFunction: start-on-event=CSigCdd_Impl_MainFunction, period=0.016
      operation invoked event OIE_pp_CmpLibCmd_CSigCdd_CSigCdd_Impl_OnCommandTrigByImpl_OnCommand: start-on-event=CSigCdd_Impl_OnCommand, operation=pp_CmpLibCmd_CSigCdd.Impl_OnCommand
      operation invoked event OIE_pp_SigCddCrc_CSigCdd_Impl_sig_get_win_crc_dataTrigByImpl_sig_get_win_crc_data: start-on-event=CSigCdd_Impl_sig_get_win_crc_data, operation=pp_SigCddCrc.Impl_sig_get_win_crc_data
      port-api-options:
        enable-take-address=false, indirect-api=false, port=pp_CmpLibCmd_CSigCdd
        enable-take-address=false, indirect-api=false, port=pp_SigCddCrc
        enable-take-address=false, indirect-api=false, port=pp_SigCddSts
        enable-take-address=false, indirect-api=false, port=rp_SigData
      runnable CSigCdd_Impl_MainFunction: can-be-invoked-concurrently=true
        data-receive-point-by-arguments:
          access DRA_rp_SigData_sig0_port: accessed-variable=rp_SigData.sig0_port
        data-send-points:
          access DWA_pp_SigCddSts_win_violation_output: accessed-variable=pp_SigCddSts.win_violation_output
      runnable CSigCdd_Impl_OnCommand: can-be-invoked-concurrently=true
      runnable CSigCdd_Impl_sig_get_win_crc_data: can-be-invoked-concurrently=true
  constant specification CSigCddwin_violation_outputValue0: value-spec=CSigCddwin_violation_outputValue0:0
  constant specification CSigCddsig0_portValue0: value-spec={short-label=CSigCddsig0_portValue0, fields=[CSigCddsig0_portValue_0:0, CSigCddsig0_portValue_1:0, CSigCddsig0_portValue_2:0, CSigCddsig0_portValue_3:0, CSigCddsig0_portValue_4:0, CSigCddsig0_portValue_5:0]}
  swc implementation IMPL_CSigCdd: programming-language=C, behavior=IB_CSigCdd
    code-descriptors:
      code CodeDescriptor
  application sw component type CSwcDispMonSf
    provide port pp_CmpLibCmd_CSwcDispMonSf: server-com-spec{operation=Impl_OnCommand, queue-length=1}, provided-interface=if_CS_ModeOnCommand
    provide port pp_SigData: nonqueued-sender-com-spec{data-element=sig0_port, init-value=constant-reference=CSwcDispMonSfsig0_portValue0}, provided-interface=TI_SigData
    require port rp_SigCddCrc: required-interface=TI_SigCddCrc
    require port rp_SigCddSts: nonqueued-receiver-com-spec{data-element=win_violation_output, init-value=constant-reference=CSwcDispMonSfwin_violation_outputValue0}, required-interface=TI_SigCddSts
    behavior IB_CSwcDispMonSf
      timing event TECSwcDispMonSf_Impl_MainFunction: start-on-event=CSwcDispMonSf_Impl_MainFunction, period=0.01
      operation invoked event OIE_pp_CmpLibCmd_CSwcDispMonSf_CSwcDispMonSf_Impl_OnCommandTrigByImpl_OnCommand: start-on-event=CSwcDispMonSf_Impl_OnCommand, operation=pp_CmpLibCmd_CSwcDispMonSf.Impl_OnCommand
      port-api-options:
        enable-take-address=false, indirect-api=false, port=pp_CmpLibCmd_CSwcDispMonSf
        enable-take-address=false, indirect-api=false, port=pp_SigData
        enable-take-address=false, indirect-api=false, port=rp_SigCddCrc
        enable-take-address=false, indirect-api=false, port=rp_SigCddSts
      runnable CSwcDispMonSf_Impl_MainFunction: can-be-invoked-concurrently=true
        data-receive-point-by-arguments:
          access DRA_rp_SigCddSts_win_violation_output: accessed-variable=rp_SigCddSts.win_violation_output
        data-send-points:
          access DWA_pp_SigData_sig0_port: accessed-variable=pp_SigData.sig0_port
        sync call OA_rp_SigCddCrc_Impl_sig_get_win_crc_data: operation=rp_SigCddCrc.Impl_sig_get_win_crc_data, timeout=0.0
      runnable CSwcDispMonSf_Impl_OnCommand: can-be-invoked-concurrently=true
  constant specification CSwcDispMonSfsig0_portValue0: value-spec={short-label=CSwcDispMonSfsig0_portValue0, fields=[CSwcDispMonSfsig0_portValue_0:0, CSwcDispMonSfsig0_portValue_1:0, CSwcDispMonSfsig0_portValue_2:0, CSwcDispMonSfsig0_portValue_3:0, CSwcDispMonSfsig0_portValue_4:0, CSwcDispMonSfsig0_portValue_5:0]}
  constant specification CSwcDispMonSfwin_violation_outputValue0: value-spec=CSwcDispMonSfwin_violation_outputValue0:0
  swc implementation IMPL_CSwcDispMonSf: programming-language=C, behavior=IB_CSwcDispMonSf
    code-descriptors:
      code CodeDescriptor
  application sw component type CSndCdd
    provide port pp_CS_SndCdd_AmpDiag: provided-com-specs=[{operation=GetSpeaker_status, queue-length=1}, {operation=SpkrAmp_Recovery, queue-length=1}], provided-interface=if_CS_SndCdd_AmpDiag
    provide port pp_CS_SndCdd_Services: provided-interface=if_CS_Sndcdd_Services
      provided-com-specs:
        operation=CheckChimeStatus, queue-length=1
        operation=CheckLastToneStatus, queue-length=1
        operation=ClearChimeResumeInfoBuffer, queue-length=1
        operation=GetChimeResumeInfoBuffer, queue-length=1
        operation=RequestCustomChime, queue-length=1
        operation=RequestToClear_SafetyChimeErrorStatus, queue-length=1
        operation=RequestToStart, queue-length=1
        operation=RequestToStop, queue-length=1
        operation=SetChimeResumeInfoBuffer, queue-length=1
        operation=SetDynamicDeadTime, queue-length=1
        operation=SetUserPersonalizationVolume, queue-length=1
        operation=StopCustomChime, queue-length=1
        operation=UpdateChannelVolume, queue-length=1
        operation=UpdateChimeInfoBuffer, queue-length=1
        operation=UpdateChimeVolume, queue-length=1
        operation=ischannelavailable, queue-length=1
    provide port pp_CmpLibCmd_CSndCdd: server-com-spec{operation=Impl_OnCommand, queue-length=1}, provided-interface=if_CS_ModeOnCommand
    behavior IB_CSndCdd
      5 x operation invoked event:
        OIE_pp_CS_SndCdd_Services_CSndCdd_CheckChimeStatusTrigByCheckChimeStatus: start-on-event=CSndCdd_CheckChimeStatus, operation=pp_CS_SndCdd_Services.CheckChimeStatus
        OIE_pp_CS_SndCdd_Services_CSndCdd_CheckLastToneStatusTrigByCheckLastToneStatus: start-on-event=CSndCdd_CheckLastToneStatus, operation=pp_CS_SndCdd_Services.CheckLastToneStatus
        OIE_pp_CS_SndCdd_Services_CSndCdd_ClearChimeResumeInfoBufferTrigByClearChimeResumeInfoBuffer: start-on-event=CSndCdd_ClearChimeResumeInfoBuffer, operation=pp_CS_SndCdd_Services.ClearChimeResumeInfoBuffer
        OIE_pp_CS_SndCdd_Services_CSndCdd_GetChimeResumeInfoBufferTrigByGetChimeResumeInfoBuffer: start-on-event=CSndCdd_GetChimeResumeInfoBuffer, operation=pp_CS_SndCdd_Services.GetChimeResumeInfoBuffer
        OIE_pp_CS_SndCdd_AmpDiag_CSndCdd_GetSpeaker_statusTrigByGetSpeaker_status: start-on-event=CSndCdd_GetSpeaker_status, operation=pp_CS_SndCdd_AmpDiag.GetSpeaker_status
      timing event TECSndCdd_Impl_MainFunction: start-on-event=CSndCdd_Impl_MainFunction, period=0.02
      9 x operation invoked event:
        OIE_pp_CmpLibCmd_CSndCdd_CSndCdd_Impl_OnCommandTrigByImpl_OnCommand: start-on-event=CSndCdd_Impl_OnCommand, operation=pp_CmpLibCmd_CSndCdd.Impl_OnCommand
        OIE_pp_CS_SndCdd_Services_CSndCdd_RequestCustomChimeTrigByRequestCustomChime: start-on-event=CSndCdd_RequestCustomChime, operation=pp_CS_SndCdd_Services.RequestCustomChime
        OIE_pp_CS_SndCdd_Services_CSndCdd_RequestToClear_SafetyChimeErrorStatusTrigByRequestToClear_SafetyChimeErrorStatus: start-on-event=CSndCdd_RequestToClear_SafetyChimeErrorStatus, operation=pp_CS_SndCdd_Services.RequestToClear_SafetyChimeErrorStatus
        OIE_pp_CS_SndCdd_Services_CSndCdd_RequestToStartTrigByRequestToStart: start-on-event=CSndCdd_RequestToStart, operation=pp_CS_SndCdd_Services.RequestToStart
        OIE_pp_CS_SndCdd_Services_CSndCdd_RequestToStopTrigByRequestToStop: start-on-event=CSndCdd_RequestToStop, operation=pp_CS_SndCdd_Services.RequestToStop
        OIE_pp_CS_SndCdd_Services_CSndCdd_SetChimeResumeInfoBufferTrigBySetChimeResumeInfoBuffer: start-on-event=CSndCdd_SetChimeResumeInfoBuffer, operation=pp_CS_SndCdd_Services.SetChimeResumeInfoBuffer
        OIE_pp_CS_SndCdd_Services_CSndCdd_SetDynamicDeadTimeTrigBySetDynamicDeadTime: start-on-event=CSndCdd_SetDynamicDeadTime, operation=pp_CS_SndCdd_Services.SetDynamicDeadTime
        OIE_pp_CS_SndCdd_Services_CSndCdd_SetUserPersonalizationVolumeTrigBySetUserPersonalizationVolume: start-on-event=CSndCdd_SetUserPersonalizationVolume, operation=pp_CS_SndCdd_Services.SetUserPersonalizationVolume
        OIE_pp_CS_SndCdd_AmpDiag_CSndCdd_SpkrAmp_RecoveryTrigBySpkrAmp_Recovery: start-on-event=CSndCdd_SpkrAmp_Recovery, operation=pp_CS_SndCdd_AmpDiag.SpkrAmp_Recovery
      timing event TECSndCdd_SpkrDiag_MainFunction: start-on-event=CSndCdd_SpkrDiag_MainFunction, period=0.1
      operation invoked event OIE_pp_CS_SndCdd_Services_CSndCdd_StopCustomChimeTrigByStopCustomChime: start-on-event=CSndCdd_StopCustomChime, operation=pp_CS_SndCdd_Services.StopCustomChime
      timing event TECSndCdd_ToneProcess: start-on-event=CSndCdd_ToneProcess, period=0.002
      4 x operation invoked event:
        OIE_pp_CS_SndCdd_Services_CSndCdd_UpdateChannelVolumeTrigByUpdateChannelVolume: start-on-event=CSndCdd_UpdateChannelVolume, operation=pp_CS_SndCdd_Services.UpdateChannelVolume
        OIE_pp_CS_SndCdd_Services_CSndCdd_UpdateChimeInfoBufferTrigByUpdateChimeInfoBuffer: start-on-event=CSndCdd_UpdateChimeInfoBuffer, operation=pp_CS_SndCdd_Services.UpdateChimeInfoBuffer
        OIE_pp_CS_SndCdd_Services_CSndCdd_UpdateChimeVolumeTrigByUpdateChimeVolume: start-on-event=CSndCdd_UpdateChimeVolume, operation=pp_CS_SndCdd_Services.UpdateChimeVolume
        OIE_pp_CS_SndCdd_Services_CSndCdd_ischannelavailableTrigByischannelavailable: start-on-event=CSndCdd_ischannelavailable, operation=pp_CS_SndCdd_Services.ischannelavailable
      port-api-options:
        enable-take-address=false, indirect-api=false, port=pp_CS_SndCdd_AmpDiag
        enable-take-address=false, indirect-api=false, port=pp_CS_SndCdd_Services
        enable-take-address=false, indirect-api=false, port=pp_CmpLibCmd_CSndCdd
      22 x runnable, all with can-be-invoked-concurrently=true:
        CSndCdd_CheckChimeStatus
        CSndCdd_CheckLastToneStatus
        CSndCdd_ClearChimeResumeInfoBuffer
        CSndCdd_GetChimeResumeInfoBuffer
        CSndCdd_GetSpeaker_status
        CSndCdd_Impl_MainFunction
        CSndCdd_Impl_OnCommand
        CSndCdd_RequestCustomChime
        CSndCdd_RequestToClear_SafetyChimeErrorStatus
        CSndCdd_RequestToStart
        CSndCdd_RequestToStop
        CSndCdd_SetChimeResumeInfoBuffer
        CSndCdd_SetDynamicDeadTime
        CSndCdd_SetUserPersonalizationVolume
        CSndCdd_SpkrAmp_Recovery
        CSndCdd_SpkrDiag_MainFunction
        CSndCdd_StopCustomChime
        CSndCdd_ToneProcess
        CSndCdd_UpdateChannelVolume
        CSndCdd_UpdateChimeInfoBuffer
        CSndCdd_UpdateChimeVolume
        CSndCdd_ischannelavailable
  swc implementation IMPL_CSndCdd: programming-language=C, behavior=IB_CSndCdd
    code-descriptors:
      code CodeDescriptor
  application sw component type CorTst
    provide port pp_CmpLibCmd_CorTst: server-com-spec{operation=Impl_OnCommand, queue-length=1}, provided-interface=if_CS_ModeOnCommand
    behavior IB_CorTst: port-api-option{enable-take-address=false, indirect-api=false, port=pp_CmpLibCmd_CorTst}
      operation invoked event OIE_pp_CmpLibCmd_CorTst_CorTst_Impl_OnCommandTrigByImpl_OnCommand: start-on-event=CorTst_Impl_OnCommand, operation=pp_CmpLibCmd_CorTst.Impl_OnCommand
      timing event TECorTst_MainFunction: start-on-event=CorTst_MainFunction, period=0.01
      runnable CorTst_Impl_OnCommand: can-be-invoked-concurrently=true
      runnable CorTst_MainFunction: can-be-invoked-concurrently=true
  swc implementation IMPL_CorTst: programming-language=C, behavior=IB_CorTst
    code-descriptors:
      code CodeDescriptor
  application sw component type FlsTst
    provide port pp_CmpLibCmd_FlsTst: server-com-spec{operation=Impl_OnCommand, queue-length=1}, provided-interface=if_CS_ModeOnCommand
    behavior IB_FlsTst: port-api-option{enable-take-address=false, indirect-api=false, port=pp_CmpLibCmd_FlsTst}
      operation invoked event OIE_pp_CmpLibCmd_FlsTst_FlsTst_Impl_OnCommandTrigByImpl_OnCommand: start-on-event=FlsTst_Impl_OnCommand, operation=pp_CmpLibCmd_FlsTst.Impl_OnCommand
      timing event TEFlsTst_MainFunction: start-on-event=FlsTst_MainFunction, period=0.01
      runnable FlsTst_Impl_OnCommand: can-be-invoked-concurrently=true
      runnable FlsTst_MainFunction: can-be-invoked-concurrently=true
  swc implementation IMPL_FlsTst: programming-language=C, behavior=IB_FlsTst
    code-descriptors:
      code CodeDescriptor
  application sw component type RamTst
    provide port pp_CmpLibCmd_RamTst: server-com-spec{operation=Impl_OnCommand, queue-length=1}, provided-interface=if_CS_ModeOnCommand
    behavior IB_RamTst: port-api-option{enable-take-address=false, indirect-api=false, port=pp_CmpLibCmd_RamTst}
      operation invoked event OIE_pp_CmpLibCmd_RamTst_RamTst_Impl_OnCommandTrigByImpl_OnCommand: start-on-event=RamTst_Impl_OnCommand, operation=pp_CmpLibCmd_RamTst.Impl_OnCommand
      timing event TERamTst_MainFunction: start-on-event=RamTst_MainFunction, period=0.01
      runnable RamTst_Impl_OnCommand: can-be-invoked-concurrently=true
      runnable RamTst_MainFunction: can-be-invoked-concurrently=true
  swc implementation IMPL_RamTst: programming-language=C, behavior=IB_RamTst
    code-descriptors:
      code CodeDescriptor
  application sw component type SysTst
    provide port pp_CmpLibCmd_SysTst: server-com-spec{operation=Impl_OnCommand, queue-length=1}, provided-interface=if_CS_ModeOnCommand
    behavior IB_SysTst: port-api-option{enable-take-address=false, indirect-api=false, port=pp_CmpLibCmd_SysTst}
      operation invoked event OIE_pp_CmpLibCmd_SysTst_SysTst_Impl_OnCommandTrigByImpl_OnCommand: start-on-event=SysTst_Impl_OnCommand, operation=pp_CmpLibCmd_SysTst.Impl_OnCommand
      timing event TESysTst_MainFunction: start-on-event=SysTst_MainFunction, period=0.01
      runnable SysTst_Impl_OnCommand: can-be-invoked-concurrently=true
      runnable SysTst_MainFunction: can-be-invoked-concurrently=true
  swc implementation IMPL_SysTst: programming-language=C, behavior=IB_SysTst
    code-descriptors:
      code CodeDescriptor
  application sw component type CCDD_FitManager
    provide port ppCS_FitDidInfo: server-com-spec{operation=CDD_FitManager_RouteFITDID, queue-length=1}, provided-interface=TI_FITDID
    require port rpCS_FitHandler_rpCS_FitHandler_CCDD_BswFit: required-interface=TI_FaultInjectionHandler
    require port rpCS_FitHandler_rpCS_FitHandler_CCDD_McuFit: required-interface=TI_FaultInjectionHandler
    behavior IB_CCDD_FitManager
      operation invoked event OIE_ppCS_FitDidInfo_CDD_FitManager_RouteFITDIDTrigByCDD_FitManager_RouteFITDID: start-on-event=CDD_FitManager_RouteFITDID, operation=ppCS_FitDidInfo.CDD_FitManager_RouteFITDID
      timing event TECCDD_FitManager_Impl_MainFunction: start-on-event=CCDD_FitManager_Impl_MainFunction, period=0.02
      port-api-options:
        enable-take-address=false, indirect-api=false, port=ppCS_FitDidInfo
        enable-take-address=false, indirect-api=false, port=rpCS_FitHandler_rpCS_FitHandler_CCDD_BswFit
        enable-take-address=false, indirect-api=false, port=rpCS_FitHandler_rpCS_FitHandler_CCDD_McuFit
      runnable CDD_FitManager_RouteFITDID: can-be-invoked-concurrently=true
      runnable CCDD_FitManager_Impl_MainFunction: can-be-invoked-concurrently=true
        sync call OA_rpCS_FitHandler_rpCS_FitHandler_CCDD_BswFit_FaultInjectionHandler: operation=rpCS_FitHandler_rpCS_FitHandler_CCDD_BswFit.FaultInjectionHandler, timeout=0.0
        sync call OA_rpCS_FitHandler_rpCS_FitHandler_CCDD_McuFit_FaultInjectionHandler: operation=rpCS_FitHandler_rpCS_FitHandler_CCDD_McuFit.FaultInjectionHandler, timeout=0.0
  swc implementation IMPL_CCDD_FitManager: programming-language=C, behavior=IB_CCDD_FitManager
    code-descriptors:
      code CodeDescriptor
  application sw component type CCDD_McuFit
    provide port ppCS_FitHandler: server-com-spec{operation=FaultInjectionHandler, queue-length=1}, provided-interface=TI_FaultInjectionHandler
    require port rpCS_EcumExt_RequestRUN: required-interface=TI_EcuMExt_RequestRUN
    behavior IB_CCDD_McuFit
      operation invoked event OIE_ppCS_FitHandler_CDD_McuFit_FaultInjectionHandlerTrigByFaultInjectionHandler: start-on-event=CDD_McuFit_FaultInjectionHandler, operation=ppCS_FitHandler.FaultInjectionHandler
      timing event TECCDD_McuFit_Impl_MainFunction: start-on-event=CCDD_McuFit_Impl_MainFunction, period=0.02
      port-api-options:
        enable-take-address=false, indirect-api=false, port=CCDD_McuFit/ppCS_FitHandler
        enable-take-address=false, indirect-api=false, port=CCDD_McuFit/rpCS_EcumExt_RequestRUN
      runnable CDD_McuFit_FaultInjectionHandler: can-be-invoked-concurrently=true
      runnable CCDD_McuFit_Impl_MainFunction: can-be-invoked-concurrently=true
        sync call OA_rpCS_EcumExt_RequestRUN_RequestRUN: operation=rpCS_EcumExt_RequestRUN.RequestRUN, timeout=0.0
  swc implementation IMPL_CCDD_McuFit: programming-language=C, behavior=IB_CCDD_McuFit
    code-descriptors:
      code CodeDescriptor
  application sw component type ComCallout
    provide port ppSR_E2EStatus: nonqueued-sender-com-spec{data-element=ABS0x102_Status, uses-end-to-end-protection=0, init-value=constant-reference=ComCalloutABS0x102_StatusValue0}, provided-interface=TI_ppSR_ComCallout
    behavior IB_ComCallout: port-api-option{enable-take-address=false, indirect-api=false, port=ppSR_E2EStatus}
      timing event TEComCallout_Impl_MainFunction: start-on-event=ComCallout_Impl_MainFunction, period=0.01
      runnable ComCallout_Impl_MainFunction: can-be-invoked-concurrently=true
        data-send-points:
          access DWA_ppSR_E2EStatus_ABS0x102_Status: accessed-variable=ppSR_E2EStatus.ABS0x102_Status
  constant specification ComCalloutABS0x102_StatusValue0: value-spec=ComCalloutABS0x102_StatusValue0:false
  swc implementation IMPL_ComCallout: programming-language=C, behavior=IB_ComCallout
    code-descriptors:
      code CodeDescriptor
  application sw component type DcmExt
    9 x provide port:
      pp_CS_DcmExt_Confirmation: server-com-spec{operation=DcmExt_Confirmation, queue-length=1}, provided-interface=TI_DcmExt_Confirmation
      pp_CS_DcmExt_Service_Iocontrol: server-com-spec{operation=DcmExt_Service_Iocontrol, queue-length=1}, provided-interface=TI_DcmExt_Service_Iocontrol
      pp_CS_DcmExt_Services_CndChk: server-com-spec{operation=DcmExt_Services_CndChk, queue-length=1}, provided-interface=TI_DcmExt_Services_CndChk
      pp_CS_DcmExt_Services_DataRead: server-com-spec{operation=DcmExt_Services_DataRead, queue-length=1}, provided-interface=TI_DcmExt_Services_DataRead
      pp_CS_DcmExt_Services_DataWrite: server-com-spec{operation=DcmExt_Services_DataWrite, queue-length=1}, provided-interface=TI_DcmExt_Services_DataWrite
      pp_CS_DcmExt_Services_LenChk: server-com-spec{operation=DcmExt_Services_LenChk, queue-length=1}, provided-interface=TI_DcmExt_Services_LenChk
      pp_CS_DcmExt_Services_RoutineResults: server-com-spec{operation=DcmExt_Services_RoutineResults, queue-length=1}, provided-interface=TI_DcmExt_Services_RoutineResults
      pp_CS_DcmExt_Services_RoutineStart: server-com-spec{operation=DcmExt_Services_RoutineStart, queue-length=1}, provided-interface=TI_DcmExt_Services_RoutineStart
      pp_CS_DcmExt_Services_RoutineStop: server-com-spec{operation=DcmExt_Services_RoutineStop, queue-length=1}, provided-interface=TI_DcmExt_Services_RoutineStop
    14 x require port:
      rp_CS_DID_App_DiagAction: required-interface=TI_DID_App_Diag_Action
      rp_CS_DID_DiagAction: required-interface=TI_DID_DiagAction
      rp_CS_DiagEntryStatus: required-interface=TI_DiagEntrySts
      rp_CS_MemAbsGet: required-interface=if_CS_MemAbsGet
      rp_CS_MemAbsSet: required-interface=if_CS_MemAbsSet
      rp_CS_RID_App_DiagAction: required-interface=TI_RID_App_Diag_Action
      rp_CS_RID_DiagAction: required-interface=TI_RID_DiagAction
      rp_CS_UpdateCdd_DID_DiagAction: required-interface=TI_UpdateCdd_GenericDIDRequestHandler
      rp_CS_UpdateCdd_RID_DiagAction: required-interface=TI_UpdateCdd_GenericRIDRequestHandler
      rp_CS_UpdateCdd_Service_0x10_Handler: required-interface=TI_UpdateCdd_GenericProgSessionRequest
      rp_CS_UpdateCdd_Service_0x34_Handler: required-interface=TI_UpdateCdd_GenericRequestDownloadHandler
      rp_CS_UpdateCdd_Service_0x36_Handler: required-interface=TI_UpdateCdd_GenericTransferDataHandler
      rp_CS_UpdateCdd_Service_0x37_Handler: required-interface=TI_UpdateCdd_GenericTransferExitHandler
      rp_SR_JobStatus: required-interface=if_SR_JobStatus
        required-com-specs:
          data-element=JobStatus_BsConst_Audio_Element, init-value=constant-reference=DcmExtJobStatus_BsConst_Audio_ElementValue0
          data-element=JobStatus_BsConst_BsConst_Illumination_ReservedByte, init-value=constant-reference=DcmExtJobStatus_BsConst_BsConst_Illumination_ReservedByteValue0
          data-element=JobStatus_BsConst_BsConst_Illumination_ReservedByte_SafeCopy1, init-value=constant-reference=DcmExtJobStatus_BsConst_BsConst_Illumination_ReservedByte_SafeCopy1Value0
          data-element=JobStatus_BsConst_BsConst_Illumination_ReservedByte_SafeCopy2, init-value=constant-reference=DcmExtJobStatus_BsConst_BsConst_Illumination_ReservedByte_SafeCopy2Value0
          data-element=JobStatus_BsConst_Communication_Element, init-value=constant-reference=DcmExtJobStatus_BsConst_Communication_ElementValue0
          data-element=JobStatus_BsConst_Compensation_Line_Shift_b, init-value=constant-reference=DcmExtJobStatus_BsConst_Compensation_Line_Shift_bValue0
          data-element=JobStatus_BsConst_Compensation_Line_Shift_b_SafeCopy1, init-value=constant-reference=DcmExtJobStatus_BsConst_Compensation_Line_Shift_b_SafeCopy1Value0
          data-element=JobStatus_BsConst_Compensation_Line_Shift_b_SafeCopy2, init-value=constant-reference=DcmExtJobStatus_BsConst_Compensation_Line_Shift_b_SafeCopy2Value0
          data-element=JobStatus_BsConst_Compensation_Line_Slope_m, init-value=constant-reference=DcmExtJobStatus_BsConst_Compensation_Line_Slope_mValue0
          data-element=JobStatus_BsConst_Compensation_Line_Slope_m_SafeCopy1, init-value=constant-reference=DcmExtJobStatus_BsConst_Compensation_Line_Slope_m_SafeCopy1Value0
          data-element=JobStatus_BsConst_Compensation_Line_Slope_m_SafeCopy2, init-value=constant-reference=DcmExtJobStatus_BsConst_Compensation_Line_Slope_m_SafeCopy2Value0
          data-element=JobStatus_BsConst_Derating_Backlight_Disable, init-value=constant-reference=DcmExtJobStatus_BsConst_Derating_Backlight_DisableValue0
          data-element=JobStatus_BsConst_Derating_Backlight_Disable_SafeCopy1, init-value=constant-reference=DcmExtJobStatus_BsConst_Derating_Backlight_Disable_SafeCopy1Value0
          data-element=JobStatus_BsConst_Derating_Backlight_Disable_SafeCopy2, init-value=constant-reference=DcmExtJobStatus_BsConst_Derating_Backlight_Disable_SafeCopy2Value0
          data-element=JobStatus_BsConst_Display_Illum_Max_Level, init-value=constant-reference=DcmExtJobStatus_BsConst_Display_Illum_Max_LevelValue0
          data-element=JobStatus_BsConst_Display_Illum_Max_Level_SafeCopy1, init-value=constant-reference=DcmExtJobStatus_BsConst_Display_Illum_Max_Level_SafeCopy1Value0
          data-element=JobStatus_BsConst_Display_Illum_Max_Level_SafeCopy2, init-value=constant-reference=DcmExtJobStatus_BsConst_Display_Illum_Max_Level_SafeCopy2Value0
          data-element=JobStatus_BsConst_EngOffTimer_Element, init-value=constant-reference=DcmExtJobStatus_BsConst_EngOffTimer_ElementValue0
          data-element=JobStatus_BsConst_FuelGauge_Element, init-value=constant-reference=DcmExtJobStatus_BsConst_FuelGauge_ElementValue0
          data-element=JobStatus_BsConst_Lookup_Curve_HotSpot_Coef_X, init-value=constant-reference=DcmExtJobStatus_BsConst_Lookup_Curve_HotSpot_Coef_XValue0
          data-element=JobStatus_BsConst_Lookup_Curve_HotSpot_Coef_X_SafeCopy1, init-value=constant-reference=DcmExtJobStatus_BsConst_Lookup_Curve_HotSpot_Coef_X_SafeCopy1Value0
          data-element=JobStatus_BsConst_Lookup_Curve_HotSpot_Coef_X_SafeCopy2, init-value=constant-reference=DcmExtJobStatus_BsConst_Lookup_Curve_HotSpot_Coef_X_SafeCopy2Value0
          data-element=JobStatus_BsConst_Lookup_Curve_HotSpot_Coef_Y, init-value=constant-reference=DcmExtJobStatus_BsConst_Lookup_Curve_HotSpot_Coef_YValue0
          data-element=JobStatus_BsConst_Lookup_Curve_HotSpot_Coef_Y_SafeCopy1, init-value=constant-reference=DcmExtJobStatus_BsConst_Lookup_Curve_HotSpot_Coef_Y_SafeCopy1Value0
          data-element=JobStatus_BsConst_Lookup_Curve_HotSpot_Coef_Y_SafeCopy2, init-value=constant-reference=DcmExtJobStatus_BsConst_Lookup_Curve_HotSpot_Coef_Y_SafeCopy2Value0
          data-element=JobStatus_BsConst_OilGauge_Element, init-value=constant-reference=DcmExtJobStatus_BsConst_OilGauge_ElementValue0
          data-element=JobStatus_BsConst_PCB_Temperature_Sensor_Conv, init-value=constant-reference=DcmExtJobStatus_BsConst_PCB_Temperature_Sensor_ConvValue0
          data-element=JobStatus_BsConst_PCB_Temperature_Sensor_Conv_SafeCopy1, init-value=constant-reference=DcmExtJobStatus_BsConst_PCB_Temperature_Sensor_Conv_SafeCopy1Value0
          data-element=JobStatus_BsConst_PCB_Temperature_Sensor_Conv_SafeCopy2, init-value=constant-reference=DcmExtJobStatus_BsConst_PCB_Temperature_Sensor_Conv_SafeCopy2Value0
          data-element=JobStatus_BsConst_PWM_boost_bypass_duty, init-value=constant-reference=DcmExtJobStatus_BsConst_PWM_boost_bypass_dutyValue0
          data-element=JobStatus_BsConst_PWM_boost_bypass_duty_SafeCopy1, init-value=constant-reference=DcmExtJobStatus_BsConst_PWM_boost_bypass_duty_SafeCopy1Value0
          data-element=JobStatus_BsConst_PWM_boost_bypass_duty_SafeCopy2, init-value=constant-reference=DcmExtJobStatus_BsConst_PWM_boost_bypass_duty_SafeCopy2Value0
          data-element=JobStatus_BsConst_PowerGauge_Element, init-value=constant-reference=DcmExtJobStatus_BsConst_PowerGauge_ElementValue0
          data-element=JobStatus_BsConst_Power_Element, init-value=constant-reference=DcmExtJobStatus_BsConst_Power_ElementValue0
          data-element=JobStatus_BsConst_RealTimeClock_Element, init-value=constant-reference=DcmExtJobStatus_BsConst_RealTimeClock_ElementValue0
          data-element=JobStatus_BsConst_ServiceReminder_Element, init-value=constant-reference=DcmExtJobStatus_BsConst_ServiceReminder_ElementValue0
          data-element=JobStatus_BsConst_SpeedoGauge_Element, init-value=constant-reference=DcmExtJobStatus_BsConst_SpeedoGauge_ElementValue0
          data-element=JobStatus_BsConst_TachoGauge_Element, init-value=constant-reference=DcmExtJobStatus_BsConst_TachoGauge_ElementValue0
          data-element=JobStatus_BsConst_TempGauge_Element, init-value=constant-reference=DcmExtJobStatus_BsConst_TempGauge_ElementValue0
          data-element=JobStatus_BsConst_Temp_Threshold_Hysteresis_Derating, init-value=constant-reference=DcmExtJobStatus_BsConst_Temp_Threshold_Hysteresis_DeratingValue0
          data-element=JobStatus_BsConst_Temp_Threshold_Hysteresis_Derating_SafeCopy1, init-value=constant-reference=DcmExtJobStatus_BsConst_Temp_Threshold_Hysteresis_Derating_SafeCopy1Value0
          data-element=JobStatus_BsConst_Temp_Threshold_Hysteresis_Derating_SafeCopy2, init-value=constant-reference=DcmExtJobStatus_BsConst_Temp_Threshold_Hysteresis_Derating_SafeCopy2Value0
          data-element=JobStatus_BsConst_Temperature_Sensor_Conv, init-value=constant-reference=DcmExtJobStatus_BsConst_Temperature_Sensor_ConvValue0
          data-element=JobStatus_BsConst_Temperature_Sensor_Conv_SafeCopy1, init-value=constant-reference=DcmExtJobStatus_BsConst_Temperature_Sensor_Conv_SafeCopy1Value0
          data-element=JobStatus_BsConst_Temperature_Sensor_Conv_SafeCopy2, init-value=constant-reference=DcmExtJobStatus_BsConst_Temperature_Sensor_Conv_SafeCopy2Value0
          data-element=JobStatus_BsConst_TripComputer_Element, init-value=constant-reference=DcmExtJobStatus_BsConst_TripComputer_ElementValue0
          data-element=JobStatus_BsConst_Warning_Element, init-value=constant-reference=DcmExtJobStatus_BsConst_Warning_ElementValue0
          data-element=JobStatus_BsCys_Certicificate_Element, init-value=constant-reference=DcmExtJobStatus_BsCys_Certicificate_ElementValue0
          data-element=JobStatus_BsDiag_Dtc_Element, init-value=constant-reference=DcmExtJobStatus_BsDiag_Dtc_ElementValue0
          data-element=JobStatus_BsDiag_ErrorRecord_Element, init-value=constant-reference=DcmExtJobStatus_BsDiag_ErrorRecord_ElementValue0
          data-element=JobStatus_BsReten_Audio_Element, init-value=constant-reference=DcmExtJobStatus_BsReten_Audio_ElementValue0
          data-element=JobStatus_BsReten_Communication_Element, init-value=constant-reference=DcmExtJobStatus_BsReten_Communication_ElementValue0
          data-element=JobStatus_BsReten_Display_Element, init-value=constant-reference=DcmExtJobStatus_BsReten_Display_ElementValue0
          data-element=JobStatus_BsReten_Gauges_Element, init-value=constant-reference=DcmExtJobStatus_BsReten_Gauges_ElementValue0
          data-element=JobStatus_BsReten_Illumination_Element, init-value=constant-reference=DcmExtJobStatus_BsReten_Illumination_ElementValue0
          data-element=JobStatus_BsReten_Odometer_Element, init-value=constant-reference=DcmExtJobStatus_BsReten_Odometer_ElementValue0
          data-element=JobStatus_BsReten_Personalization_Element, init-value=constant-reference=DcmExtJobStatus_BsReten_Personalization_ElementValue0
          data-element=JobStatus_BsReten_Power_Element, init-value=constant-reference=DcmExtJobStatus_BsReten_Power_ElementValue0
          data-element=JobStatus_BsReten_RealTimeClock_Element, init-value=constant-reference=DcmExtJobStatus_BsReten_RealTimeClock_ElementValue0
          data-element=JobStatus_BsReten_Tripcomputer_Element, init-value=constant-reference=DcmExtJobStatus_BsReten_Tripcomputer_ElementValue0
          data-element=JobStatus_BsReten_Warning_Element, init-value=constant-reference=DcmExtJobStatus_BsReten_Warning_ElementValue0
          data-element=JobStatus_BsRt_CusDlt_Element, init-value=constant-reference=DcmExtJobStatus_BsRt_CusDlt_ElementValue0
          data-element=JobStatus_BsRt_FuelGauge_Element, init-value=constant-reference=DcmExtJobStatus_BsRt_FuelGauge_ElementValue0
          data-element=JobStatus_BsRt_Illumination_Element, init-value=constant-reference=DcmExtJobStatus_BsRt_Illumination_ElementValue0
          data-element=JobStatus_BsRt_Odometer_Element, init-value=constant-reference=DcmExtJobStatus_BsRt_Odometer_ElementValue0
          data-element=JobStatus_BsRt_OilGauge_Element, init-value=constant-reference=DcmExtJobStatus_BsRt_OilGauge_ElementValue0
          data-element=JobStatus_BsRt_Personalization_Element, init-value=constant-reference=DcmExtJobStatus_BsRt_Personalization_ElementValue0
          data-element=JobStatus_BsRt_PowerGauge_Element, init-value=constant-reference=DcmExtJobStatus_BsRt_PowerGauge_ElementValue0
          data-element=JobStatus_BsRt_RealTimeClock_Element, init-value=constant-reference=DcmExtJobStatus_BsRt_RealTimeClock_ElementValue0
          data-element=JobStatus_BsRt_SpeedoGauge_Element, init-value=constant-reference=DcmExtJobStatus_BsRt_SpeedoGauge_ElementValue0
          data-element=JobStatus_BsRt_TachoGauge_Element, init-value=constant-reference=DcmExtJobStatus_BsRt_TachoGauge_ElementValue0
          data-element=JobStatus_BsRt_TempGauge_Element, init-value=constant-reference=DcmExtJobStatus_BsRt_TempGauge_ElementValue0
          data-element=JobStatus_BsRt_TripComputer_Element, init-value=constant-reference=DcmExtJobStatus_BsRt_TripComputer_ElementValue0
          data-element=JobStatus_BsRt_Warning_Element, init-value=constant-reference=DcmExtJobStatus_BsRt_Warning_ElementValue0
          data-element=JobStatus_BsShare_AssemblyManufacturingDate, init-value=constant-reference=DcmExtJobStatus_BsShare_AssemblyManufacturingDateValue0
          data-element=JobStatus_BsShare_AssemblyPlantNumber, init-value=constant-reference=DcmExtJobStatus_BsShare_AssemblyPlantNumberValue0
          data-element=JobStatus_BsShare_EcuPartNumber_Element, init-value=constant-reference=DcmExtJobStatus_BsShare_EcuPartNumber_ElementValue0
          data-element=JobStatus_BsShare_HWModification, init-value=constant-reference=DcmExtJobStatus_BsShare_HWModificationValue0
          data-element=JobStatus_BsShare_PCBSerialNumber, init-value=constant-reference=DcmExtJobStatus_BsShare_PCBSerialNumberValue0
          data-element=JobStatus_BsShare_ProductSerialNumber, init-value=constant-reference=DcmExtJobStatus_BsShare_ProductSerialNumberValue0
          data-element=JobStatus_BsShare_SMTManufacturingDate, init-value=constant-reference=DcmExtJobStatus_BsShare_SMTManufacturingDateValue0
          data-element=JobStatus_BsShare_SMTPlantNumber, init-value=constant-reference=DcmExtJobStatus_BsShare_SMTPlantNumberValue0
          data-element=JobStatus_BsShare_SwUpdFotaFinPrint_Element, init-value=constant-reference=DcmExtJobStatus_BsShare_SwUpdFotaFinPrint_ElementValue0
          data-element=JobStatus_BsShare_SwUpdFotaMode_Element, init-value=constant-reference=DcmExtJobStatus_BsShare_SwUpdFotaMode_ElementValue0
          data-element=JobStatus_BsShare_SwUpdFotaStatus_Element, init-value=constant-reference=DcmExtJobStatus_BsShare_SwUpdFotaStatus_ElementValue0
          data-element=JobStatus_BsShare_SwUpdFotadecrypt_Element, init-value=constant-reference=DcmExtJobStatus_BsShare_SwUpdFotadecrypt_ElementValue0
          data-element=JobStatus_BsShare_SwUpdReflash_Element, init-value=constant-reference=DcmExtJobStatus_BsShare_SwUpdReflash_ElementValue0
          data-element=JobStatus_BsShare_VehicleConfig_Element, init-value=constant-reference=DcmExtJobStatus_BsShare_VehicleConfig_ElementValue0
          data-element=JobStatus_BsShare_VisMeet_EOLEntry_Element, init-value=constant-reference=DcmExtJobStatus_BsShare_VisMeet_EOLEntry_ElementValue0
          data-element=JobStatus_BsShare_VisMeet_Element, init-value=constant-reference=DcmExtJobStatus_BsShare_VisMeet_ElementValue0
          data-element=JobStatus_BsShare_VisteonPCBPartNumber, init-value=constant-reference=DcmExtJobStatus_BsShare_VisteonPCBPartNumberValue0
          data-element=JobStatus_BsShare_VisteonPartNumber, init-value=constant-reference=DcmExtJobStatus_BsShare_VisteonPartNumberValue0
          data-element=JobStatus_RefCys_Certicificate1_Element, init-value=constant-reference=DcmExtJobStatus_RefCys_Certicificate1_ElementValue0
          data-element=JobStatus_RefCys_Certicificate_Element, init-value=constant-reference=DcmExtJobStatus_RefCys_Certicificate_ElementValue0
    behavior IB_DcmExt
      9 x operation invoked event:
        OIE_pp_CS_DcmExt_Confirmation_DcmExt_ConfirmationTrigByDcmExt_Confirmation: start-on-event=DcmExt_Confirmation, operation=pp_CS_DcmExt_Confirmation.DcmExt_Confirmation
        OIE_pp_CS_DcmExt_Service_Iocontrol_DcmExt_Service_IocontrolTrigByDcmExt_Service_Iocontrol: start-on-event=DcmExt_Service_Iocontrol, operation=pp_CS_DcmExt_Service_Iocontrol.DcmExt_Service_Iocontrol
        OIE_pp_CS_DcmExt_Services_CndChk_DcmExt_Services_CndChkTrigByDcmExt_Services_CndChk: start-on-event=DcmExt_Services_CndChk, operation=pp_CS_DcmExt_Services_CndChk.DcmExt_Services_CndChk
        OIE_pp_CS_DcmExt_Services_DataRead_DcmExt_Services_DataReadTrigByDcmExt_Services_DataRead: start-on-event=DcmExt_Services_DataRead, operation=pp_CS_DcmExt_Services_DataRead.DcmExt_Services_DataRead
        OIE_pp_CS_DcmExt_Services_DataWrite_DcmExt_Services_DataWriteTrigByDcmExt_Services_DataWrite: start-on-event=DcmExt_Services_DataWrite, operation=pp_CS_DcmExt_Services_DataWrite.DcmExt_Services_DataWrite
        OIE_pp_CS_DcmExt_Services_LenChk_DcmExt_Services_LenChkTrigByDcmExt_Services_LenChk: start-on-event=DcmExt_Services_LenChk, operation=pp_CS_DcmExt_Services_LenChk.DcmExt_Services_LenChk
        OIE_pp_CS_DcmExt_Services_RoutineResults_DcmExt_Services_RoutineResultsTrigByDcmExt_Services_RoutineResults: start-on-event=DcmExt_Services_RoutineResults, operation=pp_CS_DcmExt_Services_RoutineResults.DcmExt_Services_RoutineResults
        OIE_pp_CS_DcmExt_Services_RoutineStart_DcmExt_Services_RoutineStartTrigByDcmExt_Services_RoutineStart: start-on-event=DcmExt_Services_RoutineStart, operation=pp_CS_DcmExt_Services_RoutineStart.DcmExt_Services_RoutineStart
        OIE_pp_CS_DcmExt_Services_RoutineStop_DcmExt_Services_RoutineStopTrigByDcmExt_Services_RoutineStop: start-on-event=DcmExt_Services_RoutineStop, operation=pp_CS_DcmExt_Services_RoutineStop.DcmExt_Services_RoutineStop
      timing event TEDcmExt_MainFunction: start-on-event=DcmExt_MainFunction, period=0.01
      port-api-options:
        enable-take-address=false, indirect-api=false, port=pp_CS_DcmExt_Confirmation
        enable-take-address=false, indirect-api=false, port=pp_CS_DcmExt_Service_Iocontrol
        enable-take-address=false, indirect-api=false, port=pp_CS_DcmExt_Services_CndChk
        enable-take-address=false, indirect-api=false, port=pp_CS_DcmExt_Services_DataRead
        enable-take-address=false, indirect-api=false, port=pp_CS_DcmExt_Services_DataWrite
        enable-take-address=false, indirect-api=false, port=pp_CS_DcmExt_Services_LenChk
        enable-take-address=false, indirect-api=false, port=pp_CS_DcmExt_Services_RoutineResults
        enable-take-address=false, indirect-api=false, port=pp_CS_DcmExt_Services_RoutineStart
        enable-take-address=false, indirect-api=false, port=pp_CS_DcmExt_Services_RoutineStop
        enable-take-address=false, indirect-api=false, port=rp_CS_DID_App_DiagAction
        enable-take-address=false, indirect-api=false, port=rp_CS_DID_DiagAction
        enable-take-address=false, indirect-api=false, port=rp_CS_DiagEntryStatus
        enable-take-address=false, indirect-api=false, port=DcmExt/rp_CS_MemAbsGet
        enable-take-address=false, indirect-api=false, port=DcmExt/rp_CS_MemAbsSet
        enable-take-address=false, indirect-api=false, port=rp_CS_RID_App_DiagAction
        enable-take-address=false, indirect-api=false, port=rp_CS_RID_DiagAction
        enable-take-address=false, indirect-api=false, port=rp_CS_UpdateCdd_DID_DiagAction
        enable-take-address=false, indirect-api=false, port=rp_CS_UpdateCdd_RID_DiagAction
        enable-take-address=false, indirect-api=false, port=rp_CS_UpdateCdd_Service_0x10_Handler
        enable-take-address=false, indirect-api=false, port=rp_CS_UpdateCdd_Service_0x34_Handler
        enable-take-address=false, indirect-api=false, port=rp_CS_UpdateCdd_Service_0x36_Handler
        enable-take-address=false, indirect-api=false, port=rp_CS_UpdateCdd_Service_0x37_Handler
        enable-take-address=false, indirect-api=false, port=DcmExt/rp_SR_JobStatus
      10 x runnable, all with can-be-invoked-concurrently=true:
        DcmExt_Confirmation
          data-receive-point-by-arguments:
            94 x access:
              DRA_rp_SR_JobStatus_JobStatus_BsConst_Audio_Element: accessed-variable=rp_SR_JobStatus.JobStatus_BsConst_Audio_Element
              DRA_rp_SR_JobStatus_JobStatus_BsConst_BsConst_Illumination_ReservedByte: accessed-variable=rp_SR_JobStatus.JobStatus_BsConst_BsConst_Illumination_ReservedByte
              DRA_rp_SR_JobStatus_JobStatus_BsConst_BsConst_Illumination_ReservedByte_SafeCopy1: accessed-variable=rp_SR_JobStatus.JobStatus_BsConst_BsConst_Illumination_ReservedByte_SafeCopy1
              DRA_rp_SR_JobStatus_JobStatus_BsConst_BsConst_Illumination_ReservedByte_SafeCopy2: accessed-variable=rp_SR_JobStatus.JobStatus_BsConst_BsConst_Illumination_ReservedByte_SafeCopy2
              DRA_rp_SR_JobStatus_JobStatus_BsConst_Communication_Element: accessed-variable=rp_SR_JobStatus.JobStatus_BsConst_Communication_Element
              DRA_rp_SR_JobStatus_JobStatus_BsConst_Compensation_Line_Shift_b: accessed-variable=rp_SR_JobStatus.JobStatus_BsConst_Compensation_Line_Shift_b
              DRA_rp_SR_JobStatus_JobStatus_BsConst_Compensation_Line_Shift_b_SafeCopy1: accessed-variable=rp_SR_JobStatus.JobStatus_BsConst_Compensation_Line_Shift_b_SafeCopy1
              DRA_rp_SR_JobStatus_JobStatus_BsConst_Compensation_Line_Shift_b_SafeCopy2: accessed-variable=rp_SR_JobStatus.JobStatus_BsConst_Compensation_Line_Shift_b_SafeCopy2
              DRA_rp_SR_JobStatus_JobStatus_BsConst_Compensation_Line_Slope_m: accessed-variable=rp_SR_JobStatus.JobStatus_BsConst_Compensation_Line_Slope_m
              DRA_rp_SR_JobStatus_JobStatus_BsConst_Compensation_Line_Slope_m_SafeCopy1: accessed-variable=rp_SR_JobStatus.JobStatus_BsConst_Compensation_Line_Slope_m_SafeCopy1
              DRA_rp_SR_JobStatus_JobStatus_BsConst_Compensation_Line_Slope_m_SafeCopy2: accessed-variable=rp_SR_JobStatus.JobStatus_BsConst_Compensation_Line_Slope_m_SafeCopy2
              DRA_rp_SR_JobStatus_JobStatus_BsConst_Derating_Backlight_Disable: accessed-variable=rp_SR_JobStatus.JobStatus_BsConst_Derating_Backlight_Disable
              DRA_rp_SR_JobStatus_JobStatus_BsConst_Derating_Backlight_Disable_SafeCopy1: accessed-variable=rp_SR_JobStatus.JobStatus_BsConst_Derating_Backlight_Disable_SafeCopy1
              DRA_rp_SR_JobStatus_JobStatus_BsConst_Derating_Backlight_Disable_SafeCopy2: accessed-variable=rp_SR_JobStatus.JobStatus_BsConst_Derating_Backlight_Disable_SafeCopy2
              DRA_rp_SR_JobStatus_JobStatus_BsConst_Display_Illum_Max_Level: accessed-variable=rp_SR_JobStatus.JobStatus_BsConst_Display_Illum_Max_Level
              DRA_rp_SR_JobStatus_JobStatus_BsConst_Display_Illum_Max_Level_SafeCopy1: accessed-variable=rp_SR_JobStatus.JobStatus_BsConst_Display_Illum_Max_Level_SafeCopy1
              DRA_rp_SR_JobStatus_JobStatus_BsConst_Display_Illum_Max_Level_SafeCopy2: accessed-variable=rp_SR_JobStatus.JobStatus_BsConst_Display_Illum_Max_Level_SafeCopy2
              DRA_rp_SR_JobStatus_JobStatus_BsConst_EngOffTimer_Element: accessed-variable=rp_SR_JobStatus.JobStatus_BsConst_EngOffTimer_Element
              DRA_rp_SR_JobStatus_JobStatus_BsConst_FuelGauge_Element: accessed-variable=rp_SR_JobStatus.JobStatus_BsConst_FuelGauge_Element
              DRA_rp_SR_JobStatus_JobStatus_BsConst_Lookup_Curve_HotSpot_Coef_X: accessed-variable=rp_SR_JobStatus.JobStatus_BsConst_Lookup_Curve_HotSpot_Coef_X
              DRA_rp_SR_JobStatus_JobStatus_BsConst_Lookup_Curve_HotSpot_Coef_X_SafeCopy1: accessed-variable=rp_SR_JobStatus.JobStatus_BsConst_Lookup_Curve_HotSpot_Coef_X_SafeCopy1
              DRA_rp_SR_JobStatus_JobStatus_BsConst_Lookup_Curve_HotSpot_Coef_X_SafeCopy2: accessed-variable=rp_SR_JobStatus.JobStatus_BsConst_Lookup_Curve_HotSpot_Coef_X_SafeCopy2
              DRA_rp_SR_JobStatus_JobStatus_BsConst_Lookup_Curve_HotSpot_Coef_Y: accessed-variable=rp_SR_JobStatus.JobStatus_BsConst_Lookup_Curve_HotSpot_Coef_Y
              DRA_rp_SR_JobStatus_JobStatus_BsConst_Lookup_Curve_HotSpot_Coef_Y_SafeCopy1: accessed-variable=rp_SR_JobStatus.JobStatus_BsConst_Lookup_Curve_HotSpot_Coef_Y_SafeCopy1
              DRA_rp_SR_JobStatus_JobStatus_BsConst_Lookup_Curve_HotSpot_Coef_Y_SafeCopy2: accessed-variable=rp_SR_JobStatus.JobStatus_BsConst_Lookup_Curve_HotSpot_Coef_Y_SafeCopy2
              DRA_rp_SR_JobStatus_JobStatus_BsConst_OilGauge_Element: accessed-variable=rp_SR_JobStatus.JobStatus_BsConst_OilGauge_Element
              DRA_rp_SR_JobStatus_JobStatus_BsConst_PCB_Temperature_Sensor_Conv: accessed-variable=rp_SR_JobStatus.JobStatus_BsConst_PCB_Temperature_Sensor_Conv
              DRA_rp_SR_JobStatus_JobStatus_BsConst_PCB_Temperature_Sensor_Conv_SafeCopy1: accessed-variable=rp_SR_JobStatus.JobStatus_BsConst_PCB_Temperature_Sensor_Conv_SafeCopy1
              DRA_rp_SR_JobStatus_JobStatus_BsConst_PCB_Temperature_Sensor_Conv_SafeCopy2: accessed-variable=rp_SR_JobStatus.JobStatus_BsConst_PCB_Temperature_Sensor_Conv_SafeCopy2
              DRA_rp_SR_JobStatus_JobStatus_BsConst_PWM_boost_bypass_duty: accessed-variable=rp_SR_JobStatus.JobStatus_BsConst_PWM_boost_bypass_duty
              DRA_rp_SR_JobStatus_JobStatus_BsConst_PWM_boost_bypass_duty_SafeCopy1: accessed-variable=rp_SR_JobStatus.JobStatus_BsConst_PWM_boost_bypass_duty_SafeCopy1
              DRA_rp_SR_JobStatus_JobStatus_BsConst_PWM_boost_bypass_duty_SafeCopy2: accessed-variable=rp_SR_JobStatus.JobStatus_BsConst_PWM_boost_bypass_duty_SafeCopy2
              DRA_rp_SR_JobStatus_JobStatus_BsConst_PowerGauge_Element: accessed-variable=rp_SR_JobStatus.JobStatus_BsConst_PowerGauge_Element
              DRA_rp_SR_JobStatus_JobStatus_BsConst_Power_Element: accessed-variable=rp_SR_JobStatus.JobStatus_BsConst_Power_Element
              DRA_rp_SR_JobStatus_JobStatus_BsConst_RealTimeClock_Element: accessed-variable=rp_SR_JobStatus.JobStatus_BsConst_RealTimeClock_Element
              DRA_rp_SR_JobStatus_JobStatus_BsConst_ServiceReminder_Element: accessed-variable=rp_SR_JobStatus.JobStatus_BsConst_ServiceReminder_Element
              DRA_rp_SR_JobStatus_JobStatus_BsConst_SpeedoGauge_Element: accessed-variable=rp_SR_JobStatus.JobStatus_BsConst_SpeedoGauge_Element
              DRA_rp_SR_JobStatus_JobStatus_BsConst_TachoGauge_Element: accessed-variable=rp_SR_JobStatus.JobStatus_BsConst_TachoGauge_Element
              DRA_rp_SR_JobStatus_JobStatus_BsConst_TempGauge_Element: accessed-variable=rp_SR_JobStatus.JobStatus_BsConst_TempGauge_Element
              DRA_rp_SR_JobStatus_JobStatus_BsConst_Temp_Threshold_Hysteresis_Derating: accessed-variable=rp_SR_JobStatus.JobStatus_BsConst_Temp_Threshold_Hysteresis_Derating
              DRA_rp_SR_JobStatus_JobStatus_BsConst_Temp_Threshold_Hysteresis_Derating_SafeCopy1: accessed-variable=rp_SR_JobStatus.JobStatus_BsConst_Temp_Threshold_Hysteresis_Derating_SafeCopy1
              DRA_rp_SR_JobStatus_JobStatus_BsConst_Temp_Threshold_Hysteresis_Derating_SafeCopy2: accessed-variable=rp_SR_JobStatus.JobStatus_BsConst_Temp_Threshold_Hysteresis_Derating_SafeCopy2
              DRA_rp_SR_JobStatus_JobStatus_BsConst_Temperature_Sensor_Conv: accessed-variable=rp_SR_JobStatus.JobStatus_BsConst_Temperature_Sensor_Conv
              DRA_rp_SR_JobStatus_JobStatus_BsConst_Temperature_Sensor_Conv_SafeCopy1: accessed-variable=rp_SR_JobStatus.JobStatus_BsConst_Temperature_Sensor_Conv_SafeCopy1
              DRA_rp_SR_JobStatus_JobStatus_BsConst_Temperature_Sensor_Conv_SafeCopy2: accessed-variable=rp_SR_JobStatus.JobStatus_BsConst_Temperature_Sensor_Conv_SafeCopy2
              DRA_rp_SR_JobStatus_JobStatus_BsConst_TripComputer_Element: accessed-variable=rp_SR_JobStatus.JobStatus_BsConst_TripComputer_Element
              DRA_rp_SR_JobStatus_JobStatus_BsConst_Warning_Element: accessed-variable=rp_SR_JobStatus.JobStatus_BsConst_Warning_Element
              DRA_rp_SR_JobStatus_JobStatus_BsCys_Certicificate_Element: accessed-variable=rp_SR_JobStatus.JobStatus_BsCys_Certicificate_Element
              DRA_rp_SR_JobStatus_JobStatus_BsDiag_Dtc_Element: accessed-variable=rp_SR_JobStatus.JobStatus_BsDiag_Dtc_Element
              DRA_rp_SR_JobStatus_JobStatus_BsDiag_ErrorRecord_Element: accessed-variable=rp_SR_JobStatus.JobStatus_BsDiag_ErrorRecord_Element
              DRA_rp_SR_JobStatus_JobStatus_BsReten_Audio_Element: accessed-variable=rp_SR_JobStatus.JobStatus_BsReten_Audio_Element
              DRA_rp_SR_JobStatus_JobStatus_BsReten_Communication_Element: accessed-variable=rp_SR_JobStatus.JobStatus_BsReten_Communication_Element
              DRA_rp_SR_JobStatus_JobStatus_BsReten_Display_Element: accessed-variable=rp_SR_JobStatus.JobStatus_BsReten_Display_Element
              DRA_rp_SR_JobStatus_JobStatus_BsReten_Gauges_Element: accessed-variable=rp_SR_JobStatus.JobStatus_BsReten_Gauges_Element
              DRA_rp_SR_JobStatus_JobStatus_BsReten_Illumination_Element: accessed-variable=rp_SR_JobStatus.JobStatus_BsReten_Illumination_Element
              DRA_rp_SR_JobStatus_JobStatus_BsReten_Odometer_Element: accessed-variable=rp_SR_JobStatus.JobStatus_BsReten_Odometer_Element
              DRA_rp_SR_JobStatus_JobStatus_BsReten_Personalization_Element: accessed-variable=rp_SR_JobStatus.JobStatus_BsReten_Personalization_Element
              DRA_rp_SR_JobStatus_JobStatus_BsReten_Power_Element: accessed-variable=rp_SR_JobStatus.JobStatus_BsReten_Power_Element
              DRA_rp_SR_JobStatus_JobStatus_BsReten_RealTimeClock_Element: accessed-variable=rp_SR_JobStatus.JobStatus_BsReten_RealTimeClock_Element
              DRA_rp_SR_JobStatus_JobStatus_BsReten_Tripcomputer_Element: accessed-variable=rp_SR_JobStatus.JobStatus_BsReten_Tripcomputer_Element
              DRA_rp_SR_JobStatus_JobStatus_BsReten_Warning_Element: accessed-variable=rp_SR_JobStatus.JobStatus_BsReten_Warning_Element
              DRA_rp_SR_JobStatus_JobStatus_BsRt_CusDlt_Element: accessed-variable=rp_SR_JobStatus.JobStatus_BsRt_CusDlt_Element
              DRA_rp_SR_JobStatus_JobStatus_BsRt_FuelGauge_Element: accessed-variable=rp_SR_JobStatus.JobStatus_BsRt_FuelGauge_Element
              DRA_rp_SR_JobStatus_JobStatus_BsRt_Illumination_Element: accessed-variable=rp_SR_JobStatus.JobStatus_BsRt_Illumination_Element
              DRA_rp_SR_JobStatus_JobStatus_BsRt_Odometer_Element: accessed-variable=rp_SR_JobStatus.JobStatus_BsRt_Odometer_Element
              DRA_rp_SR_JobStatus_JobStatus_BsRt_OilGauge_Element: accessed-variable=rp_SR_JobStatus.JobStatus_BsRt_OilGauge_Element
              DRA_rp_SR_JobStatus_JobStatus_BsRt_Personalization_Element: accessed-variable=rp_SR_JobStatus.JobStatus_BsRt_Personalization_Element
              DRA_rp_SR_JobStatus_JobStatus_BsRt_PowerGauge_Element: accessed-variable=rp_SR_JobStatus.JobStatus_BsRt_PowerGauge_Element
              DRA_rp_SR_JobStatus_JobStatus_BsRt_RealTimeClock_Element: accessed-variable=rp_SR_JobStatus.JobStatus_BsRt_RealTimeClock_Element
              DRA_rp_SR_JobStatus_JobStatus_BsRt_SpeedoGauge_Element: accessed-variable=rp_SR_JobStatus.JobStatus_BsRt_SpeedoGauge_Element
              DRA_rp_SR_JobStatus_JobStatus_BsRt_TachoGauge_Element: accessed-variable=rp_SR_JobStatus.JobStatus_BsRt_TachoGauge_Element
              DRA_rp_SR_JobStatus_JobStatus_BsRt_TempGauge_Element: accessed-variable=rp_SR_JobStatus.JobStatus_BsRt_TempGauge_Element
              DRA_rp_SR_JobStatus_JobStatus_BsRt_TripComputer_Element: accessed-variable=rp_SR_JobStatus.JobStatus_BsRt_TripComputer_Element
              DRA_rp_SR_JobStatus_JobStatus_BsRt_Warning_Element: accessed-variable=rp_SR_JobStatus.JobStatus_BsRt_Warning_Element
              DRA_rp_SR_JobStatus_JobStatus_BsShare_AssemblyManufacturingDate: accessed-variable=rp_SR_JobStatus.JobStatus_BsShare_AssemblyManufacturingDate
              DRA_rp_SR_JobStatus_JobStatus_BsShare_AssemblyPlantNumber: accessed-variable=rp_SR_JobStatus.JobStatus_BsShare_AssemblyPlantNumber
              DRA_rp_SR_JobStatus_JobStatus_BsShare_EcuPartNumber_Element: accessed-variable=rp_SR_JobStatus.JobStatus_BsShare_EcuPartNumber_Element
              DRA_rp_SR_JobStatus_JobStatus_BsShare_HWModification: accessed-variable=rp_SR_JobStatus.JobStatus_BsShare_HWModification
              DRA_rp_SR_JobStatus_JobStatus_BsShare_PCBSerialNumber: accessed-variable=rp_SR_JobStatus.JobStatus_BsShare_PCBSerialNumber
              DRA_rp_SR_JobStatus_JobStatus_BsShare_ProductSerialNumber: accessed-variable=rp_SR_JobStatus.JobStatus_BsShare_ProductSerialNumber
              DRA_rp_SR_JobStatus_JobStatus_BsShare_SMTManufacturingDate: accessed-variable=rp_SR_JobStatus.JobStatus_BsShare_SMTManufacturingDate
              DRA_rp_SR_JobStatus_JobStatus_BsShare_SMTPlantNumber: accessed-variable=rp_SR_JobStatus.JobStatus_BsShare_SMTPlantNumber
              DRA_rp_SR_JobStatus_JobStatus_BsShare_SwUpdFotaFinPrint_Element: accessed-variable=rp_SR_JobStatus.JobStatus_BsShare_SwUpdFotaFinPrint_Element
              DRA_rp_SR_JobStatus_JobStatus_BsShare_SwUpdFotaMode_Element: accessed-variable=rp_SR_JobStatus.JobStatus_BsShare_SwUpdFotaMode_Element
              DRA_rp_SR_JobStatus_JobStatus_BsShare_SwUpdFotaStatus_Element: accessed-variable=rp_SR_JobStatus.JobStatus_BsShare_SwUpdFotaStatus_Element
              DRA_rp_SR_JobStatus_JobStatus_BsShare_SwUpdFotadecrypt_Element: accessed-variable=rp_SR_JobStatus.JobStatus_BsShare_SwUpdFotadecrypt_Element
              DRA_rp_SR_JobStatus_JobStatus_BsShare_SwUpdReflash_Element: accessed-variable=rp_SR_JobStatus.JobStatus_BsShare_SwUpdReflash_Element
              DRA_rp_SR_JobStatus_JobStatus_BsShare_VehicleConfig_Element: accessed-variable=rp_SR_JobStatus.JobStatus_BsShare_VehicleConfig_Element
              DRA_rp_SR_JobStatus_JobStatus_BsShare_VisMeet_EOLEntry_Element: accessed-variable=rp_SR_JobStatus.JobStatus_BsShare_VisMeet_EOLEntry_Element
              DRA_rp_SR_JobStatus_JobStatus_BsShare_VisMeet_Element: accessed-variable=rp_SR_JobStatus.JobStatus_BsShare_VisMeet_Element
              DRA_rp_SR_JobStatus_JobStatus_BsShare_VisteonPCBPartNumber: accessed-variable=rp_SR_JobStatus.JobStatus_BsShare_VisteonPCBPartNumber
              DRA_rp_SR_JobStatus_JobStatus_BsShare_VisteonPartNumber: accessed-variable=rp_SR_JobStatus.JobStatus_BsShare_VisteonPartNumber
              DRA_rp_SR_JobStatus_JobStatus_RefCys_Certicificate1_Element: accessed-variable=rp_SR_JobStatus.JobStatus_RefCys_Certicificate1_Element
              DRA_rp_SR_JobStatus_JobStatus_RefCys_Certicificate_Element: accessed-variable=rp_SR_JobStatus.JobStatus_RefCys_Certicificate_Element
          199 x sync call, all with timeout=0.0:
            OA_rp_CS_DID_App_DiagAction_DID_DiagAction: operation=rp_CS_DID_App_DiagAction.DID_DiagAction
            OA_rp_CS_DID_DiagAction_DID_DiagAction: operation=rp_CS_DID_DiagAction.DID_DiagAction
            OA_rp_CS_DiagEntryStatus_Diag_Entry_Status: operation=rp_CS_DiagEntryStatus.Diag_Entry_Status
            OA_rp_CS_MemAbsGet_Get_BsShare_SwUpdReflash_Element: operation=rp_CS_MemAbsGet.Get_BsShare_SwUpdReflash_Element
            OA_rp_CS_MemAbsGet_Get_BsShare_SwUpdFotaMode_Element: operation=rp_CS_MemAbsGet.Get_BsShare_SwUpdFotaMode_Element
            OA_rp_CS_MemAbsGet_Get_BsShare_SwUpdFotaFinPrint_Element: operation=rp_CS_MemAbsGet.Get_BsShare_SwUpdFotaFinPrint_Element
            OA_rp_CS_MemAbsGet_Get_BsShare_SwUpdFotaStatus_Element: operation=rp_CS_MemAbsGet.Get_BsShare_SwUpdFotaStatus_Element
            OA_rp_CS_MemAbsGet_Get_BsShare_SwUpdFotadecrypt_Element: operation=rp_CS_MemAbsGet.Get_BsShare_SwUpdFotadecrypt_Element
            OA_rp_CS_MemAbsGet_Get_BsShare_EcuPartNumber_Element: operation=rp_CS_MemAbsGet.Get_BsShare_EcuPartNumber_Element
            OA_rp_CS_MemAbsGet_Get_BsShare_VisteonPartNumber: operation=rp_CS_MemAbsGet.Get_BsShare_VisteonPartNumber
            OA_rp_CS_MemAbsGet_Get_BsShare_VisteonPCBPartNumber: operation=rp_CS_MemAbsGet.Get_BsShare_VisteonPCBPartNumber
            OA_rp_CS_MemAbsGet_Get_BsShare_ProductSerialNumber: operation=rp_CS_MemAbsGet.Get_BsShare_ProductSerialNumber
            OA_rp_CS_MemAbsGet_Get_BsShare_PCBSerialNumber: operation=rp_CS_MemAbsGet.Get_BsShare_PCBSerialNumber
            OA_rp_CS_MemAbsGet_Get_BsShare_SMTManufacturingDate: operation=rp_CS_MemAbsGet.Get_BsShare_SMTManufacturingDate
            OA_rp_CS_MemAbsGet_Get_BsShare_AssemblyManufacturingDate: operation=rp_CS_MemAbsGet.Get_BsShare_AssemblyManufacturingDate
            OA_rp_CS_MemAbsGet_Get_BsShare_SMTPlantNumber: operation=rp_CS_MemAbsGet.Get_BsShare_SMTPlantNumber
            OA_rp_CS_MemAbsGet_Get_BsShare_AssemblyPlantNumber: operation=rp_CS_MemAbsGet.Get_BsShare_AssemblyPlantNumber
            OA_rp_CS_MemAbsGet_Get_BsShare_HWModification: operation=rp_CS_MemAbsGet.Get_BsShare_HWModification
            OA_rp_CS_MemAbsGet_Get_BsShare_VisMeet_Element: operation=rp_CS_MemAbsGet.Get_BsShare_VisMeet_Element
            OA_rp_CS_MemAbsGet_Get_BsShare_VisMeet_EOLEntry_Element: operation=rp_CS_MemAbsGet.Get_BsShare_VisMeet_EOLEntry_Element
            OA_rp_CS_MemAbsGet_Get_BsShare_VehicleConfig_Element: operation=rp_CS_MemAbsGet.Get_BsShare_VehicleConfig_Element
            OA_rp_CS_MemAbsGet_Get_BsConst_SpeedoGauge_Element: operation=rp_CS_MemAbsGet.Get_BsConst_SpeedoGauge_Element
            OA_rp_CS_MemAbsGet_Get_BsConst_TachoGauge_Element: operation=rp_CS_MemAbsGet.Get_BsConst_TachoGauge_Element
            OA_rp_CS_MemAbsGet_Get_BsConst_FuelGauge_Element: operation=rp_CS_MemAbsGet.Get_BsConst_FuelGauge_Element
            OA_rp_CS_MemAbsGet_Get_BsConst_TempGauge_Element: operation=rp_CS_MemAbsGet.Get_BsConst_TempGauge_Element
            OA_rp_CS_MemAbsGet_Get_BsConst_PowerGauge_Element: operation=rp_CS_MemAbsGet.Get_BsConst_PowerGauge_Element
            OA_rp_CS_MemAbsGet_Get_BsConst_OilGauge_Element: operation=rp_CS_MemAbsGet.Get_BsConst_OilGauge_Element
            OA_rp_CS_MemAbsGet_Get_BsConst_TripComputer_Element: operation=rp_CS_MemAbsGet.Get_BsConst_TripComputer_Element
            OA_rp_CS_MemAbsGet_Get_BsConst_Compensation_Line_Slope_m: operation=rp_CS_MemAbsGet.Get_BsConst_Compensation_Line_Slope_m
            OA_rp_CS_MemAbsGet_Get_BsConst_Compensation_Line_Shift_b: operation=rp_CS_MemAbsGet.Get_BsConst_Compensation_Line_Shift_b
            OA_rp_CS_MemAbsGet_Get_BsConst_Lookup_Curve_HotSpot_Coef_X: operation=rp_CS_MemAbsGet.Get_BsConst_Lookup_Curve_HotSpot_Coef_X
            OA_rp_CS_MemAbsGet_Get_BsConst_Lookup_Curve_HotSpot_Coef_Y: operation=rp_CS_MemAbsGet.Get_BsConst_Lookup_Curve_HotSpot_Coef_Y
            OA_rp_CS_MemAbsGet_Get_BsConst_Temp_Threshold_Hysteresis_Derating: operation=rp_CS_MemAbsGet.Get_BsConst_Temp_Threshold_Hysteresis_Derating
            OA_rp_CS_MemAbsGet_Get_BsConst_Derating_Backlight_Disable: operation=rp_CS_MemAbsGet.Get_BsConst_Derating_Backlight_Disable
            OA_rp_CS_MemAbsGet_Get_BsConst_Temperature_Sensor_Conv: operation=rp_CS_MemAbsGet.Get_BsConst_Temperature_Sensor_Conv
            OA_rp_CS_MemAbsGet_Get_BsConst_PCB_Temperature_Sensor_Conv: operation=rp_CS_MemAbsGet.Get_BsConst_PCB_Temperature_Sensor_Conv
            OA_rp_CS_MemAbsGet_Get_BsConst_Display_Illum_Max_Level: operation=rp_CS_MemAbsGet.Get_BsConst_Display_Illum_Max_Level
            OA_rp_CS_MemAbsGet_Get_BsConst_PWM_boost_bypass_duty: operation=rp_CS_MemAbsGet.Get_BsConst_PWM_boost_bypass_duty
            OA_rp_CS_MemAbsGet_Get_BsConst_BsConst_Illumination_ReservedByte: operation=rp_CS_MemAbsGet.Get_BsConst_BsConst_Illumination_ReservedByte
            OA_rp_CS_MemAbsGet_Get_BsConst_Compensation_Line_Slope_m_SafeCopy1: operation=rp_CS_MemAbsGet.Get_BsConst_Compensation_Line_Slope_m_SafeCopy1
            OA_rp_CS_MemAbsGet_Get_BsConst_Compensation_Line_Shift_b_SafeCopy1: operation=rp_CS_MemAbsGet.Get_BsConst_Compensation_Line_Shift_b_SafeCopy1
            OA_rp_CS_MemAbsGet_Get_BsConst_Lookup_Curve_HotSpot_Coef_X_SafeCopy1: operation=rp_CS_MemAbsGet.Get_BsConst_Lookup_Curve_HotSpot_Coef_X_SafeCopy1
            OA_rp_CS_MemAbsGet_Get_BsConst_Lookup_Curve_HotSpot_Coef_Y_SafeCopy1: operation=rp_CS_MemAbsGet.Get_BsConst_Lookup_Curve_HotSpot_Coef_Y_SafeCopy1
            OA_rp_CS_MemAbsGet_Get_BsConst_Temp_Threshold_Hysteresis_Derating_SafeCopy1: operation=rp_CS_MemAbsGet.Get_BsConst_Temp_Threshold_Hysteresis_Derating_SafeCopy1
            OA_rp_CS_MemAbsGet_Get_BsConst_Derating_Backlight_Disable_SafeCopy1: operation=rp_CS_MemAbsGet.Get_BsConst_Derating_Backlight_Disable_SafeCopy1
            OA_rp_CS_MemAbsGet_Get_BsConst_Temperature_Sensor_Conv_SafeCopy1: operation=rp_CS_MemAbsGet.Get_BsConst_Temperature_Sensor_Conv_SafeCopy1
            OA_rp_CS_MemAbsGet_Get_BsConst_PCB_Temperature_Sensor_Conv_SafeCopy1: operation=rp_CS_MemAbsGet.Get_BsConst_PCB_Temperature_Sensor_Conv_SafeCopy1
            OA_rp_CS_MemAbsGet_Get_BsConst_Display_Illum_Max_Level_SafeCopy1: operation=rp_CS_MemAbsGet.Get_BsConst_Display_Illum_Max_Level_SafeCopy1
            OA_rp_CS_MemAbsGet_Get_BsConst_PWM_boost_bypass_duty_SafeCopy1: operation=rp_CS_MemAbsGet.Get_BsConst_PWM_boost_bypass_duty_SafeCopy1
            OA_rp_CS_MemAbsGet_Get_BsConst_BsConst_Illumination_ReservedByte_SafeCopy1: operation=rp_CS_MemAbsGet.Get_BsConst_BsConst_Illumination_ReservedByte_SafeCopy1
            OA_rp_CS_MemAbsGet_Get_BsConst_Compensation_Line_Slope_m_SafeCopy2: operation=rp_CS_MemAbsGet.Get_BsConst_Compensation_Line_Slope_m_SafeCopy2
            OA_rp_CS_MemAbsGet_Get_BsConst_Compensation_Line_Shift_b_SafeCopy2: operation=rp_CS_MemAbsGet.Get_BsConst_Compensation_Line_Shift_b_SafeCopy2
            OA_rp_CS_MemAbsGet_Get_BsConst_Lookup_Curve_HotSpot_Coef_X_SafeCopy2: operation=rp_CS_MemAbsGet.Get_BsConst_Lookup_Curve_HotSpot_Coef_X_SafeCopy2
            OA_rp_CS_MemAbsGet_Get_BsConst_Lookup_Curve_HotSpot_Coef_Y_SafeCopy2: operation=rp_CS_MemAbsGet.Get_BsConst_Lookup_Curve_HotSpot_Coef_Y_SafeCopy2
            OA_rp_CS_MemAbsGet_Get_BsConst_Temp_Threshold_Hysteresis_Derating_SafeCopy2: operation=rp_CS_MemAbsGet.Get_BsConst_Temp_Threshold_Hysteresis_Derating_SafeCopy2
            OA_rp_CS_MemAbsGet_Get_BsConst_Derating_Backlight_Disable_SafeCopy2: operation=rp_CS_MemAbsGet.Get_BsConst_Derating_Backlight_Disable_SafeCopy2
            OA_rp_CS_MemAbsGet_Get_BsConst_Temperature_Sensor_Conv_SafeCopy2: operation=rp_CS_MemAbsGet.Get_BsConst_Temperature_Sensor_Conv_SafeCopy2
            OA_rp_CS_MemAbsGet_Get_BsConst_PCB_Temperature_Sensor_Conv_SafeCopy2: operation=rp_CS_MemAbsGet.Get_BsConst_PCB_Temperature_Sensor_Conv_SafeCopy2
            OA_rp_CS_MemAbsGet_Get_BsConst_Display_Illum_Max_Level_SafeCopy2: operation=rp_CS_MemAbsGet.Get_BsConst_Display_Illum_Max_Level_SafeCopy2
            OA_rp_CS_MemAbsGet_Get_BsConst_PWM_boost_bypass_duty_SafeCopy2: operation=rp_CS_MemAbsGet.Get_BsConst_PWM_boost_bypass_duty_SafeCopy2
            OA_rp_CS_MemAbsGet_Get_BsConst_BsConst_Illumination_ReservedByte_SafeCopy2: operation=rp_CS_MemAbsGet.Get_BsConst_BsConst_Illumination_ReservedByte_SafeCopy2
            OA_rp_CS_MemAbsGet_Get_BsConst_Audio_Element: operation=rp_CS_MemAbsGet.Get_BsConst_Audio_Element
            OA_rp_CS_MemAbsGet_Get_BsConst_Warning_Element: operation=rp_CS_MemAbsGet.Get_BsConst_Warning_Element
            OA_rp_CS_MemAbsGet_Get_BsConst_RealTimeClock_Element: operation=rp_CS_MemAbsGet.Get_BsConst_RealTimeClock_Element
            OA_rp_CS_MemAbsGet_Get_BsConst_Communication_Element: operation=rp_CS_MemAbsGet.Get_BsConst_Communication_Element
            OA_rp_CS_MemAbsGet_Get_BsConst_Power_Element: operation=rp_CS_MemAbsGet.Get_BsConst_Power_Element
            OA_rp_CS_MemAbsGet_Get_BsConst_ServiceReminder_Element: operation=rp_CS_MemAbsGet.Get_BsConst_ServiceReminder_Element
            OA_rp_CS_MemAbsGet_Get_BsConst_EngOffTimer_Element: operation=rp_CS_MemAbsGet.Get_BsConst_EngOffTimer_Element
            OA_rp_CS_MemAbsGet_Get_BsCys_Certicificate_Element: operation=rp_CS_MemAbsGet.Get_BsCys_Certicificate_Element
            OA_rp_CS_MemAbsGet_Get_RefCys_Certicificate_Element: operation=rp_CS_MemAbsGet.Get_RefCys_Certicificate_Element
            OA_rp_CS_MemAbsGet_Get_RefCys_Certicificate1_Element: operation=rp_CS_MemAbsGet.Get_RefCys_Certicificate1_Element
            OA_rp_CS_MemAbsGet_Get_BsRt_Odometer_Element: operation=rp_CS_MemAbsGet.Get_BsRt_Odometer_Element
            OA_rp_CS_MemAbsGet_Get_BsRt_SpeedoGauge_Element: operation=rp_CS_MemAbsGet.Get_BsRt_SpeedoGauge_Element
            OA_rp_CS_MemAbsGet_Get_BsRt_TachoGauge_Element: operation=rp_CS_MemAbsGet.Get_BsRt_TachoGauge_Element
            OA_rp_CS_MemAbsGet_Get_BsRt_FuelGauge_Element: operation=rp_CS_MemAbsGet.Get_BsRt_FuelGauge_Element
            OA_rp_CS_MemAbsGet_Get_BsRt_TempGauge_Element: operation=rp_CS_MemAbsGet.Get_BsRt_TempGauge_Element
            OA_rp_CS_MemAbsGet_Get_BsRt_PowerGauge_Element: operation=rp_CS_MemAbsGet.Get_BsRt_PowerGauge_Element
            OA_rp_CS_MemAbsGet_Get_BsRt_OilGauge_Element: operation=rp_CS_MemAbsGet.Get_BsRt_OilGauge_Element
            OA_rp_CS_MemAbsGet_Get_BsRt_TripComputer_Element: operation=rp_CS_MemAbsGet.Get_BsRt_TripComputer_Element
            OA_rp_CS_MemAbsGet_Get_BsRt_Warning_Element: operation=rp_CS_MemAbsGet.Get_BsRt_Warning_Element
            OA_rp_CS_MemAbsGet_Get_BsRt_RealTimeClock_Element: operation=rp_CS_MemAbsGet.Get_BsRt_RealTimeClock_Element
            OA_rp_CS_MemAbsGet_Get_BsRt_Personalization_Element: operation=rp_CS_MemAbsGet.Get_BsRt_Personalization_Element
            OA_rp_CS_MemAbsGet_Get_BsRt_Illumination_Element: operation=rp_CS_MemAbsGet.Get_BsRt_Illumination_Element
            OA_rp_CS_MemAbsGet_Get_BsRt_CusDlt_Element: operation=rp_CS_MemAbsGet.Get_BsRt_CusDlt_Element
            OA_rp_CS_MemAbsGet_Get_BsReten_Odometer_Element: operation=rp_CS_MemAbsGet.Get_BsReten_Odometer_Element
            OA_rp_CS_MemAbsGet_Get_BsReten_Gauges_Element: operation=rp_CS_MemAbsGet.Get_BsReten_Gauges_Element
            OA_rp_CS_MemAbsGet_Get_BsReten_Tripcomputer_Element: operation=rp_CS_MemAbsGet.Get_BsReten_Tripcomputer_Element
            OA_rp_CS_MemAbsGet_Get_BsReten_Illumination_Element: operation=rp_CS_MemAbsGet.Get_BsReten_Illumination_Element
            OA_rp_CS_MemAbsGet_Get_BsReten_Audio_Element: operation=rp_CS_MemAbsGet.Get_BsReten_Audio_Element
            OA_rp_CS_MemAbsGet_Get_BsReten_Warning_Element: operation=rp_CS_MemAbsGet.Get_BsReten_Warning_Element
            OA_rp_CS_MemAbsGet_Get_BsReten_RealTimeClock_Element: operation=rp_CS_MemAbsGet.Get_BsReten_RealTimeClock_Element
            OA_rp_CS_MemAbsGet_Get_BsReten_Communication_Element: operation=rp_CS_MemAbsGet.Get_BsReten_Communication_Element
            OA_rp_CS_MemAbsGet_Get_BsReten_Personalization_Element: operation=rp_CS_MemAbsGet.Get_BsReten_Personalization_Element
            OA_rp_CS_MemAbsGet_Get_BsReten_Power_Element: operation=rp_CS_MemAbsGet.Get_BsReten_Power_Element
            OA_rp_CS_MemAbsGet_Get_BsReten_Display_Element: operation=rp_CS_MemAbsGet.Get_BsReten_Display_Element
            OA_rp_CS_MemAbsGet_Get_BsDiag_ErrorRecord_Element: operation=rp_CS_MemAbsGet.Get_BsDiag_ErrorRecord_Element
            OA_rp_CS_MemAbsGet_Get_BsDiag_Dtc_Element: operation=rp_CS_MemAbsGet.Get_BsDiag_Dtc_Element
            OA_rp_CS_MemAbsSet_Set_BsShare_SwUpdReflash_Element: operation=rp_CS_MemAbsSet.Set_BsShare_SwUpdReflash_Element
            OA_rp_CS_MemAbsSet_Set_BsShare_SwUpdFotaMode_Element: operation=rp_CS_MemAbsSet.Set_BsShare_SwUpdFotaMode_Element
            OA_rp_CS_MemAbsSet_Set_BsShare_SwUpdFotaFinPrint_Element: operation=rp_CS_MemAbsSet.Set_BsShare_SwUpdFotaFinPrint_Element
            OA_rp_CS_MemAbsSet_Set_BsShare_SwUpdFotaStatus_Element: operation=rp_CS_MemAbsSet.Set_BsShare_SwUpdFotaStatus_Element
            OA_rp_CS_MemAbsSet_Set_BsShare_SwUpdFotadecrypt_Element: operation=rp_CS_MemAbsSet.Set_BsShare_SwUpdFotadecrypt_Element
            OA_rp_CS_MemAbsSet_Set_BsShare_EcuPartNumber_Element: operation=rp_CS_MemAbsSet.Set_BsShare_EcuPartNumber_Element
            OA_rp_CS_MemAbsSet_Set_BsShare_VisteonPartNumber: operation=rp_CS_MemAbsSet.Set_BsShare_VisteonPartNumber
            OA_rp_CS_MemAbsSet_Set_BsShare_VisteonPCBPartNumber: operation=rp_CS_MemAbsSet.Set_BsShare_VisteonPCBPartNumber
            OA_rp_CS_MemAbsSet_Set_BsShare_ProductSerialNumber: operation=rp_CS_MemAbsSet.Set_BsShare_ProductSerialNumber
            OA_rp_CS_MemAbsSet_Set_BsShare_PCBSerialNumber: operation=rp_CS_MemAbsSet.Set_BsShare_PCBSerialNumber
            OA_rp_CS_MemAbsSet_Set_BsShare_SMTManufacturingDate: operation=rp_CS_MemAbsSet.Set_BsShare_SMTManufacturingDate
            OA_rp_CS_MemAbsSet_Set_BsShare_AssemblyManufacturingDate: operation=rp_CS_MemAbsSet.Set_BsShare_AssemblyManufacturingDate
            OA_rp_CS_MemAbsSet_Set_BsShare_SMTPlantNumber: operation=rp_CS_MemAbsSet.Set_BsShare_SMTPlantNumber
            OA_rp_CS_MemAbsSet_Set_BsShare_AssemblyPlantNumber: operation=rp_CS_MemAbsSet.Set_BsShare_AssemblyPlantNumber
            OA_rp_CS_MemAbsSet_Set_BsShare_HWModification: operation=rp_CS_MemAbsSet.Set_BsShare_HWModification
            OA_rp_CS_MemAbsSet_Set_BsShare_VisMeet_Element: operation=rp_CS_MemAbsSet.Set_BsShare_VisMeet_Element
            OA_rp_CS_MemAbsSet_Set_BsShare_VisMeet_EOLEntry_Element: operation=rp_CS_MemAbsSet.Set_BsShare_VisMeet_EOLEntry_Element
            OA_rp_CS_MemAbsSet_Set_BsShare_VehicleConfig_Element: operation=rp_CS_MemAbsSet.Set_BsShare_VehicleConfig_Element
            OA_rp_CS_MemAbsSet_Set_BsConst_SpeedoGauge_Element: operation=rp_CS_MemAbsSet.Set_BsConst_SpeedoGauge_Element
            OA_rp_CS_MemAbsSet_Set_BsConst_TachoGauge_Element: operation=rp_CS_MemAbsSet.Set_BsConst_TachoGauge_Element
            OA_rp_CS_MemAbsSet_Set_BsConst_FuelGauge_Element: operation=rp_CS_MemAbsSet.Set_BsConst_FuelGauge_Element
            OA_rp_CS_MemAbsSet_Set_BsConst_TempGauge_Element: operation=rp_CS_MemAbsSet.Set_BsConst_TempGauge_Element
            OA_rp_CS_MemAbsSet_Set_BsConst_PowerGauge_Element: operation=rp_CS_MemAbsSet.Set_BsConst_PowerGauge_Element
            OA_rp_CS_MemAbsSet_Set_BsConst_OilGauge_Element: operation=rp_CS_MemAbsSet.Set_BsConst_OilGauge_Element
            OA_rp_CS_MemAbsSet_Set_BsConst_TripComputer_Element: operation=rp_CS_MemAbsSet.Set_BsConst_TripComputer_Element
            OA_rp_CS_MemAbsSet_Set_BsConst_Compensation_Line_Slope_m: operation=rp_CS_MemAbsSet.Set_BsConst_Compensation_Line_Slope_m
            OA_rp_CS_MemAbsSet_Set_BsConst_Compensation_Line_Shift_b: operation=rp_CS_MemAbsSet.Set_BsConst_Compensation_Line_Shift_b
            OA_rp_CS_MemAbsSet_Set_BsConst_Lookup_Curve_HotSpot_Coef_X: operation=rp_CS_MemAbsSet.Set_BsConst_Lookup_Curve_HotSpot_Coef_X
            OA_rp_CS_MemAbsSet_Set_BsConst_Lookup_Curve_HotSpot_Coef_Y: operation=rp_CS_MemAbsSet.Set_BsConst_Lookup_Curve_HotSpot_Coef_Y
            OA_rp_CS_MemAbsSet_Set_BsConst_Temp_Threshold_Hysteresis_Derating: operation=rp_CS_MemAbsSet.Set_BsConst_Temp_Threshold_Hysteresis_Derating
            OA_rp_CS_MemAbsSet_Set_BsConst_Derating_Backlight_Disable: operation=rp_CS_MemAbsSet.Set_BsConst_Derating_Backlight_Disable
            OA_rp_CS_MemAbsSet_Set_BsConst_Temperature_Sensor_Conv: operation=rp_CS_MemAbsSet.Set_BsConst_Temperature_Sensor_Conv
            OA_rp_CS_MemAbsSet_Set_BsConst_PCB_Temperature_Sensor_Conv: operation=rp_CS_MemAbsSet.Set_BsConst_PCB_Temperature_Sensor_Conv
            OA_rp_CS_MemAbsSet_Set_BsConst_Display_Illum_Max_Level: operation=rp_CS_MemAbsSet.Set_BsConst_Display_Illum_Max_Level
            OA_rp_CS_MemAbsSet_Set_BsConst_PWM_boost_bypass_duty: operation=rp_CS_MemAbsSet.Set_BsConst_PWM_boost_bypass_duty
            OA_rp_CS_MemAbsSet_Set_BsConst_BsConst_Illumination_ReservedByte: operation=rp_CS_MemAbsSet.Set_BsConst_BsConst_Illumination_ReservedByte
            OA_rp_CS_MemAbsSet_Set_BsConst_Compensation_Line_Slope_m_SafeCopy1: operation=rp_CS_MemAbsSet.Set_BsConst_Compensation_Line_Slope_m_SafeCopy1
            OA_rp_CS_MemAbsSet_Set_BsConst_Compensation_Line_Shift_b_SafeCopy1: operation=rp_CS_MemAbsSet.Set_BsConst_Compensation_Line_Shift_b_SafeCopy1
            OA_rp_CS_MemAbsSet_Set_BsConst_Lookup_Curve_HotSpot_Coef_X_SafeCopy1: operation=rp_CS_MemAbsSet.Set_BsConst_Lookup_Curve_HotSpot_Coef_X_SafeCopy1
            OA_rp_CS_MemAbsSet_Set_BsConst_Lookup_Curve_HotSpot_Coef_Y_SafeCopy1: operation=rp_CS_MemAbsSet.Set_BsConst_Lookup_Curve_HotSpot_Coef_Y_SafeCopy1
            OA_rp_CS_MemAbsSet_Set_BsConst_Temp_Threshold_Hysteresis_Derating_SafeCopy1: operation=rp_CS_MemAbsSet.Set_BsConst_Temp_Threshold_Hysteresis_Derating_SafeCopy1
            OA_rp_CS_MemAbsSet_Set_BsConst_Derating_Backlight_Disable_SafeCopy1: operation=rp_CS_MemAbsSet.Set_BsConst_Derating_Backlight_Disable_SafeCopy1
            OA_rp_CS_MemAbsSet_Set_BsConst_Temperature_Sensor_Conv_SafeCopy1: operation=rp_CS_MemAbsSet.Set_BsConst_Temperature_Sensor_Conv_SafeCopy1
            OA_rp_CS_MemAbsSet_Set_BsConst_PCB_Temperature_Sensor_Conv_SafeCopy1: operation=rp_CS_MemAbsSet.Set_BsConst_PCB_Temperature_Sensor_Conv_SafeCopy1
            OA_rp_CS_MemAbsSet_Set_BsConst_Display_Illum_Max_Level_SafeCopy1: operation=rp_CS_MemAbsSet.Set_BsConst_Display_Illum_Max_Level_SafeCopy1
            OA_rp_CS_MemAbsSet_Set_BsConst_PWM_boost_bypass_duty_SafeCopy1: operation=rp_CS_MemAbsSet.Set_BsConst_PWM_boost_bypass_duty_SafeCopy1
            OA_rp_CS_MemAbsSet_Set_BsConst_BsConst_Illumination_ReservedByte_SafeCopy1: operation=rp_CS_MemAbsSet.Set_BsConst_BsConst_Illumination_ReservedByte_SafeCopy1
            OA_rp_CS_MemAbsSet_Set_BsConst_Compensation_Line_Slope_m_SafeCopy2: operation=rp_CS_MemAbsSet.Set_BsConst_Compensation_Line_Slope_m_SafeCopy2
            OA_rp_CS_MemAbsSet_Set_BsConst_Compensation_Line_Shift_b_SafeCopy2: operation=rp_CS_MemAbsSet.Set_BsConst_Compensation_Line_Shift_b_SafeCopy2
            OA_rp_CS_MemAbsSet_Set_BsConst_Lookup_Curve_HotSpot_Coef_X_SafeCopy2: operation=rp_CS_MemAbsSet.Set_BsConst_Lookup_Curve_HotSpot_Coef_X_SafeCopy2
            OA_rp_CS_MemAbsSet_Set_BsConst_Lookup_Curve_HotSpot_Coef_Y_SafeCopy2: operation=rp_CS_MemAbsSet.Set_BsConst_Lookup_Curve_HotSpot_Coef_Y_SafeCopy2
            OA_rp_CS_MemAbsSet_Set_BsConst_Temp_Threshold_Hysteresis_Derating_SafeCopy2: operation=rp_CS_MemAbsSet.Set_BsConst_Temp_Threshold_Hysteresis_Derating_SafeCopy2
            OA_rp_CS_MemAbsSet_Set_BsConst_Derating_Backlight_Disable_SafeCopy2: operation=rp_CS_MemAbsSet.Set_BsConst_Derating_Backlight_Disable_SafeCopy2
            OA_rp_CS_MemAbsSet_Set_BsConst_Temperature_Sensor_Conv_SafeCopy2: operation=rp_CS_MemAbsSet.Set_BsConst_Temperature_Sensor_Conv_SafeCopy2
            OA_rp_CS_MemAbsSet_Set_BsConst_PCB_Temperature_Sensor_Conv_SafeCopy2: operation=rp_CS_MemAbsSet.Set_BsConst_PCB_Temperature_Sensor_Conv_SafeCopy2
            OA_rp_CS_MemAbsSet_Set_BsConst_Display_Illum_Max_Level_SafeCopy2: operation=rp_CS_MemAbsSet.Set_BsConst_Display_Illum_Max_Level_SafeCopy2
            OA_rp_CS_MemAbsSet_Set_BsConst_PWM_boost_bypass_duty_SafeCopy2: operation=rp_CS_MemAbsSet.Set_BsConst_PWM_boost_bypass_duty_SafeCopy2
            OA_rp_CS_MemAbsSet_Set_BsConst_BsConst_Illumination_ReservedByte_SafeCopy2: operation=rp_CS_MemAbsSet.Set_BsConst_BsConst_Illumination_ReservedByte_SafeCopy2
            OA_rp_CS_MemAbsSet_Set_BsConst_Audio_Element: operation=rp_CS_MemAbsSet.Set_BsConst_Audio_Element
            OA_rp_CS_MemAbsSet_Set_BsConst_Warning_Element: operation=rp_CS_MemAbsSet.Set_BsConst_Warning_Element
            OA_rp_CS_MemAbsSet_Set_BsConst_RealTimeClock_Element: operation=rp_CS_MemAbsSet.Set_BsConst_RealTimeClock_Element
            OA_rp_CS_MemAbsSet_Set_BsConst_Communication_Element: operation=rp_CS_MemAbsSet.Set_BsConst_Communication_Element
            OA_rp_CS_MemAbsSet_Set_BsConst_Power_Element: operation=rp_CS_MemAbsSet.Set_BsConst_Power_Element
            OA_rp_CS_MemAbsSet_Set_BsConst_ServiceReminder_Element: operation=rp_CS_MemAbsSet.Set_BsConst_ServiceReminder_Element
            OA_rp_CS_MemAbsSet_Set_BsConst_EngOffTimer_Element: operation=rp_CS_MemAbsSet.Set_BsConst_EngOffTimer_Element
            OA_rp_CS_MemAbsSet_Set_BsCys_Certicificate_Element: operation=rp_CS_MemAbsSet.Set_BsCys_Certicificate_Element
            OA_rp_CS_MemAbsSet_Set_RefCys_Certicificate_Element: operation=rp_CS_MemAbsSet.Set_RefCys_Certicificate_Element
            OA_rp_CS_MemAbsSet_Set_RefCys_Certicificate1_Element: operation=rp_CS_MemAbsSet.Set_RefCys_Certicificate1_Element
            OA_rp_CS_MemAbsSet_Set_BsRt_Odometer_Element: operation=rp_CS_MemAbsSet.Set_BsRt_Odometer_Element
            OA_rp_CS_MemAbsSet_Set_BsRt_SpeedoGauge_Element: operation=rp_CS_MemAbsSet.Set_BsRt_SpeedoGauge_Element
            OA_rp_CS_MemAbsSet_Set_BsRt_TachoGauge_Element: operation=rp_CS_MemAbsSet.Set_BsRt_TachoGauge_Element
            OA_rp_CS_MemAbsSet_Set_BsRt_FuelGauge_Element: operation=rp_CS_MemAbsSet.Set_BsRt_FuelGauge_Element
            OA_rp_CS_MemAbsSet_Set_BsRt_TempGauge_Element: operation=rp_CS_MemAbsSet.Set_BsRt_TempGauge_Element
            OA_rp_CS_MemAbsSet_Set_BsRt_PowerGauge_Element: operation=rp_CS_MemAbsSet.Set_BsRt_PowerGauge_Element
            OA_rp_CS_MemAbsSet_Set_BsRt_OilGauge_Element: operation=rp_CS_MemAbsSet.Set_BsRt_OilGauge_Element
            OA_rp_CS_MemAbsSet_Set_BsRt_TripComputer_Element: operation=rp_CS_MemAbsSet.Set_BsRt_TripComputer_Element
            OA_rp_CS_MemAbsSet_Set_BsRt_Warning_Element: operation=rp_CS_MemAbsSet.Set_BsRt_Warning_Element
            OA_rp_CS_MemAbsSet_Set_BsRt_RealTimeClock_Element: operation=rp_CS_MemAbsSet.Set_BsRt_RealTimeClock_Element
            OA_rp_CS_MemAbsSet_Set_BsRt_Personalization_Element: operation=rp_CS_MemAbsSet.Set_BsRt_Personalization_Element
            OA_rp_CS_MemAbsSet_Set_BsRt_Illumination_Element: operation=rp_CS_MemAbsSet.Set_BsRt_Illumination_Element
            OA_rp_CS_MemAbsSet_Set_BsRt_CusDlt_Element: operation=rp_CS_MemAbsSet.Set_BsRt_CusDlt_Element
            OA_rp_CS_MemAbsSet_Set_BsReten_Odometer_Element: operation=rp_CS_MemAbsSet.Set_BsReten_Odometer_Element
            OA_rp_CS_MemAbsSet_Set_BsReten_Gauges_Element: operation=rp_CS_MemAbsSet.Set_BsReten_Gauges_Element
            OA_rp_CS_MemAbsSet_Set_BsReten_Tripcomputer_Element: operation=rp_CS_MemAbsSet.Set_BsReten_Tripcomputer_Element
            OA_rp_CS_MemAbsSet_Set_BsReten_Illumination_Element: operation=rp_CS_MemAbsSet.Set_BsReten_Illumination_Element
            OA_rp_CS_MemAbsSet_Set_BsReten_Audio_Element: operation=rp_CS_MemAbsSet.Set_BsReten_Audio_Element
            OA_rp_CS_MemAbsSet_Set_BsReten_Warning_Element: operation=rp_CS_MemAbsSet.Set_BsReten_Warning_Element
            OA_rp_CS_MemAbsSet_Set_BsReten_RealTimeClock_Element: operation=rp_CS_MemAbsSet.Set_BsReten_RealTimeClock_Element
            OA_rp_CS_MemAbsSet_Set_BsReten_Communication_Element: operation=rp_CS_MemAbsSet.Set_BsReten_Communication_Element
            OA_rp_CS_MemAbsSet_Set_BsReten_Personalization_Element: operation=rp_CS_MemAbsSet.Set_BsReten_Personalization_Element
            OA_rp_CS_MemAbsSet_Set_BsReten_Power_Element: operation=rp_CS_MemAbsSet.Set_BsReten_Power_Element
            OA_rp_CS_MemAbsSet_Set_BsReten_Display_Element: operation=rp_CS_MemAbsSet.Set_BsReten_Display_Element
            OA_rp_CS_MemAbsSet_Set_BsDiag_ErrorRecord_Element: operation=rp_CS_MemAbsSet.Set_BsDiag_ErrorRecord_Element
            OA_rp_CS_MemAbsSet_Set_BsDiag_Dtc_Element: operation=rp_CS_MemAbsSet.Set_BsDiag_Dtc_Element
            OA_rp_CS_RID_App_DiagAction_RID_DiagAction: operation=rp_CS_RID_App_DiagAction.RID_DiagAction
            OA_rp_CS_RID_DiagAction_RID_DiagAction: operation=rp_CS_RID_DiagAction.RID_DiagAction
            OA_rp_CS_UpdateCdd_DID_DiagAction_UpdateCdd_GenericDIDRequestHandler: operation=rp_CS_UpdateCdd_DID_DiagAction.UpdateCdd_GenericDIDRequestHandler
            OA_rp_CS_UpdateCdd_RID_DiagAction_UpdateCdd_GenericRIDRequestHandler: operation=rp_CS_UpdateCdd_RID_DiagAction.UpdateCdd_GenericRIDRequestHandler
            OA_rp_CS_UpdateCdd_Service_0x10_Handler_UpdateCdd_GenericProgSessionRequest: operation=rp_CS_UpdateCdd_Service_0x10_Handler.UpdateCdd_GenericProgSessionRequest
            OA_rp_CS_UpdateCdd_Service_0x34_Handler_UpdateCdd_GenericRequestDownloadHandler: operation=rp_CS_UpdateCdd_Service_0x34_Handler.UpdateCdd_GenericRequestDownloadHandler
            OA_rp_CS_UpdateCdd_Service_0x36_Handler_UpdateCdd_GenericTransferDataHandler: operation=rp_CS_UpdateCdd_Service_0x36_Handler.UpdateCdd_GenericTransferDataHandler
            OA_rp_CS_UpdateCdd_Service_0x37_Handler_UpdateCdd_GenericTransferExitHandler: operation=rp_CS_UpdateCdd_Service_0x37_Handler.UpdateCdd_GenericTransferExitHandler
        DcmExt_Service_Iocontrol
          data-receive-point-by-arguments:
            94 x access:
              DRA_rp_SR_JobStatus_JobStatus_BsConst_Audio_Element: accessed-variable=rp_SR_JobStatus.JobStatus_BsConst_Audio_Element
              DRA_rp_SR_JobStatus_JobStatus_BsConst_BsConst_Illumination_ReservedByte: accessed-variable=rp_SR_JobStatus.JobStatus_BsConst_BsConst_Illumination_ReservedByte
              DRA_rp_SR_JobStatus_JobStatus_BsConst_BsConst_Illumination_ReservedByte_SafeCopy1: accessed-variable=rp_SR_JobStatus.JobStatus_BsConst_BsConst_Illumination_ReservedByte_SafeCopy1
              DRA_rp_SR_JobStatus_JobStatus_BsConst_BsConst_Illumination_ReservedByte_SafeCopy2: accessed-variable=rp_SR_JobStatus.JobStatus_BsConst_BsConst_Illumination_ReservedByte_SafeCopy2
              DRA_rp_SR_JobStatus_JobStatus_BsConst_Communication_Element: accessed-variable=rp_SR_JobStatus.JobStatus_BsConst_Communication_Element
              DRA_rp_SR_JobStatus_JobStatus_BsConst_Compensation_Line_Shift_b: accessed-variable=rp_SR_JobStatus.JobStatus_BsConst_Compensation_Line_Shift_b
              DRA_rp_SR_JobStatus_JobStatus_BsConst_Compensation_Line_Shift_b_SafeCopy1: accessed-variable=rp_SR_JobStatus.JobStatus_BsConst_Compensation_Line_Shift_b_SafeCopy1
              DRA_rp_SR_JobStatus_JobStatus_BsConst_Compensation_Line_Shift_b_SafeCopy2: accessed-variable=rp_SR_JobStatus.JobStatus_BsConst_Compensation_Line_Shift_b_SafeCopy2
              DRA_rp_SR_JobStatus_JobStatus_BsConst_Compensation_Line_Slope_m: accessed-variable=rp_SR_JobStatus.JobStatus_BsConst_Compensation_Line_Slope_m
              DRA_rp_SR_JobStatus_JobStatus_BsConst_Compensation_Line_Slope_m_SafeCopy1: accessed-variable=rp_SR_JobStatus.JobStatus_BsConst_Compensation_Line_Slope_m_SafeCopy1
              DRA_rp_SR_JobStatus_JobStatus_BsConst_Compensation_Line_Slope_m_SafeCopy2: accessed-variable=rp_SR_JobStatus.JobStatus_BsConst_Compensation_Line_Slope_m_SafeCopy2
              DRA_rp_SR_JobStatus_JobStatus_BsConst_Derating_Backlight_Disable: accessed-variable=rp_SR_JobStatus.JobStatus_BsConst_Derating_Backlight_Disable
              DRA_rp_SR_JobStatus_JobStatus_BsConst_Derating_Backlight_Disable_SafeCopy1: accessed-variable=rp_SR_JobStatus.JobStatus_BsConst_Derating_Backlight_Disable_SafeCopy1
              DRA_rp_SR_JobStatus_JobStatus_BsConst_Derating_Backlight_Disable_SafeCopy2: accessed-variable=rp_SR_JobStatus.JobStatus_BsConst_Derating_Backlight_Disable_SafeCopy2
              DRA_rp_SR_JobStatus_JobStatus_BsConst_Display_Illum_Max_Level: accessed-variable=rp_SR_JobStatus.JobStatus_BsConst_Display_Illum_Max_Level
              DRA_rp_SR_JobStatus_JobStatus_BsConst_Display_Illum_Max_Level_SafeCopy1: accessed-variable=rp_SR_JobStatus.JobStatus_BsConst_Display_Illum_Max_Level_SafeCopy1
              DRA_rp_SR_JobStatus_JobStatus_BsConst_Display_Illum_Max_Level_SafeCopy2: accessed-variable=rp_SR_JobStatus.JobStatus_BsConst_Display_Illum_Max_Level_SafeCopy2
              DRA_rp_SR_JobStatus_JobStatus_BsConst_EngOffTimer_Element: accessed-variable=rp_SR_JobStatus.JobStatus_BsConst_EngOffTimer_Element
              DRA_rp_SR_JobStatus_JobStatus_BsConst_FuelGauge_Element: accessed-variable=rp_SR_JobStatus.JobStatus_BsConst_FuelGauge_Element
              DRA_rp_SR_JobStatus_JobStatus_BsConst_Lookup_Curve_HotSpot_Coef_X: accessed-variable=rp_SR_JobStatus.JobStatus_BsConst_Lookup_Curve_HotSpot_Coef_X
              DRA_rp_SR_JobStatus_JobStatus_BsConst_Lookup_Curve_HotSpot_Coef_X_SafeCopy1: accessed-variable=rp_SR_JobStatus.JobStatus_BsConst_Lookup_Curve_HotSpot_Coef_X_SafeCopy1
              DRA_rp_SR_JobStatus_JobStatus_BsConst_Lookup_Curve_HotSpot_Coef_X_SafeCopy2: accessed-variable=rp_SR_JobStatus.JobStatus_BsConst_Lookup_Curve_HotSpot_Coef_X_SafeCopy2
              DRA_rp_SR_JobStatus_JobStatus_BsConst_Lookup_Curve_HotSpot_Coef_Y: accessed-variable=rp_SR_JobStatus.JobStatus_BsConst_Lookup_Curve_HotSpot_Coef_Y
              DRA_rp_SR_JobStatus_JobStatus_BsConst_Lookup_Curve_HotSpot_Coef_Y_SafeCopy1: accessed-variable=rp_SR_JobStatus.JobStatus_BsConst_Lookup_Curve_HotSpot_Coef_Y_SafeCopy1
              DRA_rp_SR_JobStatus_JobStatus_BsConst_Lookup_Curve_HotSpot_Coef_Y_SafeCopy2: accessed-variable=rp_SR_JobStatus.JobStatus_BsConst_Lookup_Curve_HotSpot_Coef_Y_SafeCopy2
              DRA_rp_SR_JobStatus_JobStatus_BsConst_OilGauge_Element: accessed-variable=rp_SR_JobStatus.JobStatus_BsConst_OilGauge_Element
              DRA_rp_SR_JobStatus_JobStatus_BsConst_PCB_Temperature_Sensor_Conv: accessed-variable=rp_SR_JobStatus.JobStatus_BsConst_PCB_Temperature_Sensor_Conv
              DRA_rp_SR_JobStatus_JobStatus_BsConst_PCB_Temperature_Sensor_Conv_SafeCopy1: accessed-variable=rp_SR_JobStatus.JobStatus_BsConst_PCB_Temperature_Sensor_Conv_SafeCopy1
              DRA_rp_SR_JobStatus_JobStatus_BsConst_PCB_Temperature_Sensor_Conv_SafeCopy2: accessed-variable=rp_SR_JobStatus.JobStatus_BsConst_PCB_Temperature_Sensor_Conv_SafeCopy2
              DRA_rp_SR_JobStatus_JobStatus_BsConst_PWM_boost_bypass_duty: accessed-variable=rp_SR_JobStatus.JobStatus_BsConst_PWM_boost_bypass_duty
              DRA_rp_SR_JobStatus_JobStatus_BsConst_PWM_boost_bypass_duty_SafeCopy1: accessed-variable=rp_SR_JobStatus.JobStatus_BsConst_PWM_boost_bypass_duty_SafeCopy1
              DRA_rp_SR_JobStatus_JobStatus_BsConst_PWM_boost_bypass_duty_SafeCopy2: accessed-variable=rp_SR_JobStatus.JobStatus_BsConst_PWM_boost_bypass_duty_SafeCopy2
              DRA_rp_SR_JobStatus_JobStatus_BsConst_PowerGauge_Element: accessed-variable=rp_SR_JobStatus.JobStatus_BsConst_PowerGauge_Element
              DRA_rp_SR_JobStatus_JobStatus_BsConst_Power_Element: accessed-variable=rp_SR_JobStatus.JobStatus_BsConst_Power_Element
              DRA_rp_SR_JobStatus_JobStatus_BsConst_RealTimeClock_Element: accessed-variable=rp_SR_JobStatus.JobStatus_BsConst_RealTimeClock_Element
              DRA_rp_SR_JobStatus_JobStatus_BsConst_ServiceReminder_Element: accessed-variable=rp_SR_JobStatus.JobStatus_BsConst_ServiceReminder_Element
              DRA_rp_SR_JobStatus_JobStatus_BsConst_SpeedoGauge_Element: accessed-variable=rp_SR_JobStatus.JobStatus_BsConst_SpeedoGauge_Element
              DRA_rp_SR_JobStatus_JobStatus_BsConst_TachoGauge_Element: accessed-variable=rp_SR_JobStatus.JobStatus_BsConst_TachoGauge_Element
              DRA_rp_SR_JobStatus_JobStatus_BsConst_TempGauge_Element: accessed-variable=rp_SR_JobStatus.JobStatus_BsConst_TempGauge_Element
              DRA_rp_SR_JobStatus_JobStatus_BsConst_Temp_Threshold_Hysteresis_Derating: accessed-variable=rp_SR_JobStatus.JobStatus_BsConst_Temp_Threshold_Hysteresis_Derating
              DRA_rp_SR_JobStatus_JobStatus_BsConst_Temp_Threshold_Hysteresis_Derating_SafeCopy1: accessed-variable=rp_SR_JobStatus.JobStatus_BsConst_Temp_Threshold_Hysteresis_Derating_SafeCopy1
              DRA_rp_SR_JobStatus_JobStatus_BsConst_Temp_Threshold_Hysteresis_Derating_SafeCopy2: accessed-variable=rp_SR_JobStatus.JobStatus_BsConst_Temp_Threshold_Hysteresis_Derating_SafeCopy2
              DRA_rp_SR_JobStatus_JobStatus_BsConst_Temperature_Sensor_Conv: accessed-variable=rp_SR_JobStatus.JobStatus_BsConst_Temperature_Sensor_Conv
              DRA_rp_SR_JobStatus_JobStatus_BsConst_Temperature_Sensor_Conv_SafeCopy1: accessed-variable=rp_SR_JobStatus.JobStatus_BsConst_Temperature_Sensor_Conv_SafeCopy1
              DRA_rp_SR_JobStatus_JobStatus_BsConst_Temperature_Sensor_Conv_SafeCopy2: accessed-variable=rp_SR_JobStatus.JobStatus_BsConst_Temperature_Sensor_Conv_SafeCopy2
              DRA_rp_SR_JobStatus_JobStatus_BsConst_TripComputer_Element: accessed-variable=rp_SR_JobStatus.JobStatus_BsConst_TripComputer_Element
              DRA_rp_SR_JobStatus_JobStatus_BsConst_Warning_Element: accessed-variable=rp_SR_JobStatus.JobStatus_BsConst_Warning_Element
              DRA_rp_SR_JobStatus_JobStatus_BsCys_Certicificate_Element: accessed-variable=rp_SR_JobStatus.JobStatus_BsCys_Certicificate_Element
              DRA_rp_SR_JobStatus_JobStatus_BsDiag_Dtc_Element: accessed-variable=rp_SR_JobStatus.JobStatus_BsDiag_Dtc_Element
              DRA_rp_SR_JobStatus_JobStatus_BsDiag_ErrorRecord_Element: accessed-variable=rp_SR_JobStatus.JobStatus_BsDiag_ErrorRecord_Element
              DRA_rp_SR_JobStatus_JobStatus_BsReten_Audio_Element: accessed-variable=rp_SR_JobStatus.JobStatus_BsReten_Audio_Element
              DRA_rp_SR_JobStatus_JobStatus_BsReten_Communication_Element: accessed-variable=rp_SR_JobStatus.JobStatus_BsReten_Communication_Element
              DRA_rp_SR_JobStatus_JobStatus_BsReten_Display_Element: accessed-variable=rp_SR_JobStatus.JobStatus_BsReten_Display_Element
              DRA_rp_SR_JobStatus_JobStatus_BsReten_Gauges_Element: accessed-variable=rp_SR_JobStatus.JobStatus_BsReten_Gauges_Element
              DRA_rp_SR_JobStatus_JobStatus_BsReten_Illumination_Element: accessed-variable=rp_SR_JobStatus.JobStatus_BsReten_Illumination_Element
              DRA_rp_SR_JobStatus_JobStatus_BsReten_Odometer_Element: accessed-variable=rp_SR_JobStatus.JobStatus_BsReten_Odometer_Element
              DRA_rp_SR_JobStatus_JobStatus_BsReten_Personalization_Element: accessed-variable=rp_SR_JobStatus.JobStatus_BsReten_Personalization_Element
              DRA_rp_SR_JobStatus_JobStatus_BsReten_Power_Element: accessed-variable=rp_SR_JobStatus.JobStatus_BsReten_Power_Element
              DRA_rp_SR_JobStatus_JobStatus_BsReten_RealTimeClock_Element: accessed-variable=rp_SR_JobStatus.JobStatus_BsReten_RealTimeClock_Element
              DRA_rp_SR_JobStatus_JobStatus_BsReten_Tripcomputer_Element: accessed-variable=rp_SR_JobStatus.JobStatus_BsReten_Tripcomputer_Element
              DRA_rp_SR_JobStatus_JobStatus_BsReten_Warning_Element: accessed-variable=rp_SR_JobStatus.JobStatus_BsReten_Warning_Element
              DRA_rp_SR_JobStatus_JobStatus_BsRt_CusDlt_Element: accessed-variable=rp_SR_JobStatus.JobStatus_BsRt_CusDlt_Element
              DRA_rp_SR_JobStatus_JobStatus_BsRt_FuelGauge_Element: accessed-variable=rp_SR_JobStatus.JobStatus_BsRt_FuelGauge_Element
              DRA_rp_SR_JobStatus_JobStatus_BsRt_Illumination_Element: accessed-variable=rp_SR_JobStatus.JobStatus_BsRt_Illumination_Element
              DRA_rp_SR_JobStatus_JobStatus_BsRt_Odometer_Element: accessed-variable=rp_SR_JobStatus.JobStatus_BsRt_Odometer_Element
              DRA_rp_SR_JobStatus_JobStatus_BsRt_OilGauge_Element: accessed-variable=rp_SR_JobStatus.JobStatus_BsRt_OilGauge_Element
              DRA_rp_SR_JobStatus_JobStatus_BsRt_Personalization_Element: accessed-variable=rp_SR_JobStatus.JobStatus_BsRt_Personalization_Element
              DRA_rp_SR_JobStatus_JobStatus_BsRt_PowerGauge_Element: accessed-variable=rp_SR_JobStatus.JobStatus_BsRt_PowerGauge_Element
              DRA_rp_SR_JobStatus_JobStatus_BsRt_RealTimeClock_Element: accessed-variable=rp_SR_JobStatus.JobStatus_BsRt_RealTimeClock_Element
              DRA_rp_SR_JobStatus_JobStatus_BsRt_SpeedoGauge_Element: accessed-variable=rp_SR_JobStatus.JobStatus_BsRt_SpeedoGauge_Element
              DRA_rp_SR_JobStatus_JobStatus_BsRt_TachoGauge_Element: accessed-variable=rp_SR_JobStatus.JobStatus_BsRt_TachoGauge_Element
              DRA_rp_SR_JobStatus_JobStatus_BsRt_TempGauge_Element: accessed-variable=rp_SR_JobStatus.JobStatus_BsRt_TempGauge_Element
              DRA_rp_SR_JobStatus_JobStatus_BsRt_TripComputer_Element: accessed-variable=rp_SR_JobStatus.JobStatus_BsRt_TripComputer_Element
              DRA_rp_SR_JobStatus_JobStatus_BsRt_Warning_Element: accessed-variable=rp_SR_JobStatus.JobStatus_BsRt_Warning_Element
              DRA_rp_SR_JobStatus_JobStatus_BsShare_AssemblyManufacturingDate: accessed-variable=rp_SR_JobStatus.JobStatus_BsShare_AssemblyManufacturingDate
              DRA_rp_SR_JobStatus_JobStatus_BsShare_AssemblyPlantNumber: accessed-variable=rp_SR_JobStatus.JobStatus_BsShare_AssemblyPlantNumber
              DRA_rp_SR_JobStatus_JobStatus_BsShare_EcuPartNumber_Element: accessed-variable=rp_SR_JobStatus.JobStatus_BsShare_EcuPartNumber_Element
              DRA_rp_SR_JobStatus_JobStatus_BsShare_HWModification: accessed-variable=rp_SR_JobStatus.JobStatus_BsShare_HWModification
              DRA_rp_SR_JobStatus_JobStatus_BsShare_PCBSerialNumber: accessed-variable=rp_SR_JobStatus.JobStatus_BsShare_PCBSerialNumber
              DRA_rp_SR_JobStatus_JobStatus_BsShare_ProductSerialNumber: accessed-variable=rp_SR_JobStatus.JobStatus_BsShare_ProductSerialNumber
              DRA_rp_SR_JobStatus_JobStatus_BsShare_SMTManufacturingDate: accessed-variable=rp_SR_JobStatus.JobStatus_BsShare_SMTManufacturingDate
              DRA_rp_SR_JobStatus_JobStatus_BsShare_SMTPlantNumber: accessed-variable=rp_SR_JobStatus.JobStatus_BsShare_SMTPlantNumber
              DRA_rp_SR_JobStatus_JobStatus_BsShare_SwUpdFotaFinPrint_Element: accessed-variable=rp_SR_JobStatus.JobStatus_BsShare_SwUpdFotaFinPrint_Element
              DRA_rp_SR_JobStatus_JobStatus_BsShare_SwUpdFotaMode_Element: accessed-variable=rp_SR_JobStatus.JobStatus_BsShare_SwUpdFotaMode_Element
              DRA_rp_SR_JobStatus_JobStatus_BsShare_SwUpdFotaStatus_Element: accessed-variable=rp_SR_JobStatus.JobStatus_BsShare_SwUpdFotaStatus_Element
              DRA_rp_SR_JobStatus_JobStatus_BsShare_SwUpdFotadecrypt_Element: accessed-variable=rp_SR_JobStatus.JobStatus_BsShare_SwUpdFotadecrypt_Element
              DRA_rp_SR_JobStatus_JobStatus_BsShare_SwUpdReflash_Element: accessed-variable=rp_SR_JobStatus.JobStatus_BsShare_SwUpdReflash_Element
              DRA_rp_SR_JobStatus_JobStatus_BsShare_VehicleConfig_Element: accessed-variable=rp_SR_JobStatus.JobStatus_BsShare_VehicleConfig_Element
              DRA_rp_SR_JobStatus_JobStatus_BsShare_VisMeet_EOLEntry_Element: accessed-variable=rp_SR_JobStatus.JobStatus_BsShare_VisMeet_EOLEntry_Element
              DRA_rp_SR_JobStatus_JobStatus_BsShare_VisMeet_Element: accessed-variable=rp_SR_JobStatus.JobStatus_BsShare_VisMeet_Element
              DRA_rp_SR_JobStatus_JobStatus_BsShare_VisteonPCBPartNumber: accessed-variable=rp_SR_JobStatus.JobStatus_BsShare_VisteonPCBPartNumber
              DRA_rp_SR_JobStatus_JobStatus_BsShare_VisteonPartNumber: accessed-variable=rp_SR_JobStatus.JobStatus_BsShare_VisteonPartNumber
              DRA_rp_SR_JobStatus_JobStatus_RefCys_Certicificate1_Element: accessed-variable=rp_SR_JobStatus.JobStatus_RefCys_Certicificate1_Element
              DRA_rp_SR_JobStatus_JobStatus_RefCys_Certicificate_Element: accessed-variable=rp_SR_JobStatus.JobStatus_RefCys_Certicificate_Element
          199 x sync call, all with timeout=0.0:
            OA_rp_CS_DID_App_DiagAction_DID_DiagAction: operation=rp_CS_DID_App_DiagAction.DID_DiagAction
            OA_rp_CS_DID_DiagAction_DID_DiagAction: operation=rp_CS_DID_DiagAction.DID_DiagAction
            OA_rp_CS_DiagEntryStatus_Diag_Entry_Status: operation=rp_CS_DiagEntryStatus.Diag_Entry_Status
            OA_rp_CS_MemAbsGet_Get_BsShare_SwUpdReflash_Element: operation=rp_CS_MemAbsGet.Get_BsShare_SwUpdReflash_Element
            OA_rp_CS_MemAbsGet_Get_BsShare_SwUpdFotaMode_Element: operation=rp_CS_MemAbsGet.Get_BsShare_SwUpdFotaMode_Element
            OA_rp_CS_MemAbsGet_Get_BsShare_SwUpdFotaFinPrint_Element: operation=rp_CS_MemAbsGet.Get_BsShare_SwUpdFotaFinPrint_Element
            OA_rp_CS_MemAbsGet_Get_BsShare_SwUpdFotaStatus_Element: operation=rp_CS_MemAbsGet.Get_BsShare_SwUpdFotaStatus_Element
            OA_rp_CS_MemAbsGet_Get_BsShare_SwUpdFotadecrypt_Element: operation=rp_CS_MemAbsGet.Get_BsShare_SwUpdFotadecrypt_Element
            OA_rp_CS_MemAbsGet_Get_BsShare_EcuPartNumber_Element: operation=rp_CS_MemAbsGet.Get_BsShare_EcuPartNumber_Element
            OA_rp_CS_MemAbsGet_Get_BsShare_VisteonPartNumber: operation=rp_CS_MemAbsGet.Get_BsShare_VisteonPartNumber
            OA_rp_CS_MemAbsGet_Get_BsShare_VisteonPCBPartNumber: operation=rp_CS_MemAbsGet.Get_BsShare_VisteonPCBPartNumber
            OA_rp_CS_MemAbsGet_Get_BsShare_ProductSerialNumber: operation=rp_CS_MemAbsGet.Get_BsShare_ProductSerialNumber
            OA_rp_CS_MemAbsGet_Get_BsShare_PCBSerialNumber: operation=rp_CS_MemAbsGet.Get_BsShare_PCBSerialNumber
            OA_rp_CS_MemAbsGet_Get_BsShare_SMTManufacturingDate: operation=rp_CS_MemAbsGet.Get_BsShare_SMTManufacturingDate
            OA_rp_CS_MemAbsGet_Get_BsShare_AssemblyManufacturingDate: operation=rp_CS_MemAbsGet.Get_BsShare_AssemblyManufacturingDate
            OA_rp_CS_MemAbsGet_Get_BsShare_SMTPlantNumber: operation=rp_CS_MemAbsGet.Get_BsShare_SMTPlantNumber
            OA_rp_CS_MemAbsGet_Get_BsShare_AssemblyPlantNumber: operation=rp_CS_MemAbsGet.Get_BsShare_AssemblyPlantNumber
            OA_rp_CS_MemAbsGet_Get_BsShare_HWModification: operation=rp_CS_MemAbsGet.Get_BsShare_HWModification
            OA_rp_CS_MemAbsGet_Get_BsShare_VisMeet_Element: operation=rp_CS_MemAbsGet.Get_BsShare_VisMeet_Element
            OA_rp_CS_MemAbsGet_Get_BsShare_VisMeet_EOLEntry_Element: operation=rp_CS_MemAbsGet.Get_BsShare_VisMeet_EOLEntry_Element
            OA_rp_CS_MemAbsGet_Get_BsShare_VehicleConfig_Element: operation=rp_CS_MemAbsGet.Get_BsShare_VehicleConfig_Element
            OA_rp_CS_MemAbsGet_Get_BsConst_SpeedoGauge_Element: operation=rp_CS_MemAbsGet.Get_BsConst_SpeedoGauge_Element
            OA_rp_CS_MemAbsGet_Get_BsConst_TachoGauge_Element: operation=rp_CS_MemAbsGet.Get_BsConst_TachoGauge_Element
            OA_rp_CS_MemAbsGet_Get_BsConst_FuelGauge_Element: operation=rp_CS_MemAbsGet.Get_BsConst_FuelGauge_Element
            OA_rp_CS_MemAbsGet_Get_BsConst_TempGauge_Element: operation=rp_CS_MemAbsGet.Get_BsConst_TempGauge_Element
            OA_rp_CS_MemAbsGet_Get_BsConst_PowerGauge_Element: operation=rp_CS_MemAbsGet.Get_BsConst_PowerGauge_Element
            OA_rp_CS_MemAbsGet_Get_BsConst_OilGauge_Element: operation=rp_CS_MemAbsGet.Get_BsConst_OilGauge_Element
            OA_rp_CS_MemAbsGet_Get_BsConst_TripComputer_Element: operation=rp_CS_MemAbsGet.Get_BsConst_TripComputer_Element
            OA_rp_CS_MemAbsGet_Get_BsConst_Compensation_Line_Slope_m: operation=rp_CS_MemAbsGet.Get_BsConst_Compensation_Line_Slope_m
            OA_rp_CS_MemAbsGet_Get_BsConst_Compensation_Line_Shift_b: operation=rp_CS_MemAbsGet.Get_BsConst_Compensation_Line_Shift_b
            OA_rp_CS_MemAbsGet_Get_BsConst_Lookup_Curve_HotSpot_Coef_X: operation=rp_CS_MemAbsGet.Get_BsConst_Lookup_Curve_HotSpot_Coef_X
            OA_rp_CS_MemAbsGet_Get_BsConst_Lookup_Curve_HotSpot_Coef_Y: operation=rp_CS_MemAbsGet.Get_BsConst_Lookup_Curve_HotSpot_Coef_Y
            OA_rp_CS_MemAbsGet_Get_BsConst_Temp_Threshold_Hysteresis_Derating: operation=rp_CS_MemAbsGet.Get_BsConst_Temp_Threshold_Hysteresis_Derating
            OA_rp_CS_MemAbsGet_Get_BsConst_Derating_Backlight_Disable: operation=rp_CS_MemAbsGet.Get_BsConst_Derating_Backlight_Disable
            OA_rp_CS_MemAbsGet_Get_BsConst_Temperature_Sensor_Conv: operation=rp_CS_MemAbsGet.Get_BsConst_Temperature_Sensor_Conv
            OA_rp_CS_MemAbsGet_Get_BsConst_PCB_Temperature_Sensor_Conv: operation=rp_CS_MemAbsGet.Get_BsConst_PCB_Temperature_Sensor_Conv
            OA_rp_CS_MemAbsGet_Get_BsConst_Display_Illum_Max_Level: operation=rp_CS_MemAbsGet.Get_BsConst_Display_Illum_Max_Level
            OA_rp_CS_MemAbsGet_Get_BsConst_PWM_boost_bypass_duty: operation=rp_CS_MemAbsGet.Get_BsConst_PWM_boost_bypass_duty
            OA_rp_CS_MemAbsGet_Get_BsConst_BsConst_Illumination_ReservedByte: operation=rp_CS_MemAbsGet.Get_BsConst_BsConst_Illumination_ReservedByte
            OA_rp_CS_MemAbsGet_Get_BsConst_Compensation_Line_Slope_m_SafeCopy1: operation=rp_CS_MemAbsGet.Get_BsConst_Compensation_Line_Slope_m_SafeCopy1
            OA_rp_CS_MemAbsGet_Get_BsConst_Compensation_Line_Shift_b_SafeCopy1: operation=rp_CS_MemAbsGet.Get_BsConst_Compensation_Line_Shift_b_SafeCopy1
            OA_rp_CS_MemAbsGet_Get_BsConst_Lookup_Curve_HotSpot_Coef_X_SafeCopy1: operation=rp_CS_MemAbsGet.Get_BsConst_Lookup_Curve_HotSpot_Coef_X_SafeCopy1
            OA_rp_CS_MemAbsGet_Get_BsConst_Lookup_Curve_HotSpot_Coef_Y_SafeCopy1: operation=rp_CS_MemAbsGet.Get_BsConst_Lookup_Curve_HotSpot_Coef_Y_SafeCopy1
            OA_rp_CS_MemAbsGet_Get_BsConst_Temp_Threshold_Hysteresis_Derating_SafeCopy1: operation=rp_CS_MemAbsGet.Get_BsConst_Temp_Threshold_Hysteresis_Derating_SafeCopy1
            OA_rp_CS_MemAbsGet_Get_BsConst_Derating_Backlight_Disable_SafeCopy1: operation=rp_CS_MemAbsGet.Get_BsConst_Derating_Backlight_Disable_SafeCopy1
            OA_rp_CS_MemAbsGet_Get_BsConst_Temperature_Sensor_Conv_SafeCopy1: operation=rp_CS_MemAbsGet.Get_BsConst_Temperature_Sensor_Conv_SafeCopy1
            OA_rp_CS_MemAbsGet_Get_BsConst_PCB_Temperature_Sensor_Conv_SafeCopy1: operation=rp_CS_MemAbsGet.Get_BsConst_PCB_Temperature_Sensor_Conv_SafeCopy1
            OA_rp_CS_MemAbsGet_Get_BsConst_Display_Illum_Max_Level_SafeCopy1: operation=rp_CS_MemAbsGet.Get_BsConst_Display_Illum_Max_Level_SafeCopy1
            OA_rp_CS_MemAbsGet_Get_BsConst_PWM_boost_bypass_duty_SafeCopy1: operation=rp_CS_MemAbsGet.Get_BsConst_PWM_boost_bypass_duty_SafeCopy1
            OA_rp_CS_MemAbsGet_Get_BsConst_BsConst_Illumination_ReservedByte_SafeCopy1: operation=rp_CS_MemAbsGet.Get_BsConst_BsConst_Illumination_ReservedByte_SafeCopy1
            OA_rp_CS_MemAbsGet_Get_BsConst_Compensation_Line_Slope_m_SafeCopy2: operation=rp_CS_MemAbsGet.Get_BsConst_Compensation_Line_Slope_m_SafeCopy2
            OA_rp_CS_MemAbsGet_Get_BsConst_Compensation_Line_Shift_b_SafeCopy2: operation=rp_CS_MemAbsGet.Get_BsConst_Compensation_Line_Shift_b_SafeCopy2
            OA_rp_CS_MemAbsGet_Get_BsConst_Lookup_Curve_HotSpot_Coef_X_SafeCopy2: operation=rp_CS_MemAbsGet.Get_BsConst_Lookup_Curve_HotSpot_Coef_X_SafeCopy2
            OA_rp_CS_MemAbsGet_Get_BsConst_Lookup_Curve_HotSpot_Coef_Y_SafeCopy2: operation=rp_CS_MemAbsGet.Get_BsConst_Lookup_Curve_HotSpot_Coef_Y_SafeCopy2
            OA_rp_CS_MemAbsGet_Get_BsConst_Temp_Threshold_Hysteresis_Derating_SafeCopy2: operation=rp_CS_MemAbsGet.Get_BsConst_Temp_Threshold_Hysteresis_Derating_SafeCopy2
            OA_rp_CS_MemAbsGet_Get_BsConst_Derating_Backlight_Disable_SafeCopy2: operation=rp_CS_MemAbsGet.Get_BsConst_Derating_Backlight_Disable_SafeCopy2
            OA_rp_CS_MemAbsGet_Get_BsConst_Temperature_Sensor_Conv_SafeCopy2: operation=rp_CS_MemAbsGet.Get_BsConst_Temperature_Sensor_Conv_SafeCopy2
            OA_rp_CS_MemAbsGet_Get_BsConst_PCB_Temperature_Sensor_Conv_SafeCopy2: operation=rp_CS_MemAbsGet.Get_BsConst_PCB_Temperature_Sensor_Conv_SafeCopy2
            OA_rp_CS_MemAbsGet_Get_BsConst_Display_Illum_Max_Level_SafeCopy2: operation=rp_CS_MemAbsGet.Get_BsConst_Display_Illum_Max_Level_SafeCopy2
            OA_rp_CS_MemAbsGet_Get_BsConst_PWM_boost_bypass_duty_SafeCopy2: operation=rp_CS_MemAbsGet.Get_BsConst_PWM_boost_bypass_duty_SafeCopy2
            OA_rp_CS_MemAbsGet_Get_BsConst_BsConst_Illumination_ReservedByte_SafeCopy2: operation=rp_CS_MemAbsGet.Get_BsConst_BsConst_Illumination_ReservedByte_SafeCopy2
            OA_rp_CS_MemAbsGet_Get_BsConst_Audio_Element: operation=rp_CS_MemAbsGet.Get_BsConst_Audio_Element
            OA_rp_CS_MemAbsGet_Get_BsConst_Warning_Element: operation=rp_CS_MemAbsGet.Get_BsConst_Warning_Element
            OA_rp_CS_MemAbsGet_Get_BsConst_RealTimeClock_Element: operation=rp_CS_MemAbsGet.Get_BsConst_RealTimeClock_Element
            OA_rp_CS_MemAbsGet_Get_BsConst_Communication_Element: operation=rp_CS_MemAbsGet.Get_BsConst_Communication_Element
            OA_rp_CS_MemAbsGet_Get_BsConst_Power_Element: operation=rp_CS_MemAbsGet.Get_BsConst_Power_Element
            OA_rp_CS_MemAbsGet_Get_BsConst_ServiceReminder_Element: operation=rp_CS_MemAbsGet.Get_BsConst_ServiceReminder_Element
            OA_rp_CS_MemAbsGet_Get_BsConst_EngOffTimer_Element: operation=rp_CS_MemAbsGet.Get_BsConst_EngOffTimer_Element
            OA_rp_CS_MemAbsGet_Get_BsCys_Certicificate_Element: operation=rp_CS_MemAbsGet.Get_BsCys_Certicificate_Element
            OA_rp_CS_MemAbsGet_Get_RefCys_Certicificate_Element: operation=rp_CS_MemAbsGet.Get_RefCys_Certicificate_Element
            OA_rp_CS_MemAbsGet_Get_RefCys_Certicificate1_Element: operation=rp_CS_MemAbsGet.Get_RefCys_Certicificate1_Element
            OA_rp_CS_MemAbsGet_Get_BsRt_Odometer_Element: operation=rp_CS_MemAbsGet.Get_BsRt_Odometer_Element
            OA_rp_CS_MemAbsGet_Get_BsRt_SpeedoGauge_Element: operation=rp_CS_MemAbsGet.Get_BsRt_SpeedoGauge_Element
            OA_rp_CS_MemAbsGet_Get_BsRt_TachoGauge_Element: operation=rp_CS_MemAbsGet.Get_BsRt_TachoGauge_Element
            OA_rp_CS_MemAbsGet_Get_BsRt_FuelGauge_Element: operation=rp_CS_MemAbsGet.Get_BsRt_FuelGauge_Element
            OA_rp_CS_MemAbsGet_Get_BsRt_TempGauge_Element: operation=rp_CS_MemAbsGet.Get_BsRt_TempGauge_Element
            OA_rp_CS_MemAbsGet_Get_BsRt_PowerGauge_Element: operation=rp_CS_MemAbsGet.Get_BsRt_PowerGauge_Element
            OA_rp_CS_MemAbsGet_Get_BsRt_OilGauge_Element: operation=rp_CS_MemAbsGet.Get_BsRt_OilGauge_Element
            OA_rp_CS_MemAbsGet_Get_BsRt_TripComputer_Element: operation=rp_CS_MemAbsGet.Get_BsRt_TripComputer_Element
            OA_rp_CS_MemAbsGet_Get_BsRt_Warning_Element: operation=rp_CS_MemAbsGet.Get_BsRt_Warning_Element
            OA_rp_CS_MemAbsGet_Get_BsRt_RealTimeClock_Element: operation=rp_CS_MemAbsGet.Get_BsRt_RealTimeClock_Element
            OA_rp_CS_MemAbsGet_Get_BsRt_Personalization_Element: operation=rp_CS_MemAbsGet.Get_BsRt_Personalization_Element
            OA_rp_CS_MemAbsGet_Get_BsRt_Illumination_Element: operation=rp_CS_MemAbsGet.Get_BsRt_Illumination_Element
            OA_rp_CS_MemAbsGet_Get_BsRt_CusDlt_Element: operation=rp_CS_MemAbsGet.Get_BsRt_CusDlt_Element
            OA_rp_CS_MemAbsGet_Get_BsReten_Odometer_Element: operation=rp_CS_MemAbsGet.Get_BsReten_Odometer_Element
            OA_rp_CS_MemAbsGet_Get_BsReten_Gauges_Element: operation=rp_CS_MemAbsGet.Get_BsReten_Gauges_Element
            OA_rp_CS_MemAbsGet_Get_BsReten_Tripcomputer_Element: operation=rp_CS_MemAbsGet.Get_BsReten_Tripcomputer_Element
            OA_rp_CS_MemAbsGet_Get_BsReten_Illumination_Element: operation=rp_CS_MemAbsGet.Get_BsReten_Illumination_Element
            OA_rp_CS_MemAbsGet_Get_BsReten_Audio_Element: operation=rp_CS_MemAbsGet.Get_BsReten_Audio_Element
            OA_rp_CS_MemAbsGet_Get_BsReten_Warning_Element: operation=rp_CS_MemAbsGet.Get_BsReten_Warning_Element
            OA_rp_CS_MemAbsGet_Get_BsReten_RealTimeClock_Element: operation=rp_CS_MemAbsGet.Get_BsReten_RealTimeClock_Element
            OA_rp_CS_MemAbsGet_Get_BsReten_Communication_Element: operation=rp_CS_MemAbsGet.Get_BsReten_Communication_Element
            OA_rp_CS_MemAbsGet_Get_BsReten_Personalization_Element: operation=rp_CS_MemAbsGet.Get_BsReten_Personalization_Element
            OA_rp_CS_MemAbsGet_Get_BsReten_Power_Element: operation=rp_CS_MemAbsGet.Get_BsReten_Power_Element
            OA_rp_CS_MemAbsGet_Get_BsReten_Display_Element: operation=rp_CS_MemAbsGet.Get_BsReten_Display_Element
            OA_rp_CS_MemAbsGet_Get_BsDiag_ErrorRecord_Element: operation=rp_CS_MemAbsGet.Get_BsDiag_ErrorRecord_Element
            OA_rp_CS_MemAbsGet_Get_BsDiag_Dtc_Element: operation=rp_CS_MemAbsGet.Get_BsDiag_Dtc_Element
            OA_rp_CS_MemAbsSet_Set_BsShare_SwUpdReflash_Element: operation=rp_CS_MemAbsSet.Set_BsShare_SwUpdReflash_Element
            OA_rp_CS_MemAbsSet_Set_BsShare_SwUpdFotaMode_Element: operation=rp_CS_MemAbsSet.Set_BsShare_SwUpdFotaMode_Element
            OA_rp_CS_MemAbsSet_Set_BsShare_SwUpdFotaFinPrint_Element: operation=rp_CS_MemAbsSet.Set_BsShare_SwUpdFotaFinPrint_Element
            OA_rp_CS_MemAbsSet_Set_BsShare_SwUpdFotaStatus_Element: operation=rp_CS_MemAbsSet.Set_BsShare_SwUpdFotaStatus_Element
            OA_rp_CS_MemAbsSet_Set_BsShare_SwUpdFotadecrypt_Element: operation=rp_CS_MemAbsSet.Set_BsShare_SwUpdFotadecrypt_Element
            OA_rp_CS_MemAbsSet_Set_BsShare_EcuPartNumber_Element: operation=rp_CS_MemAbsSet.Set_BsShare_EcuPartNumber_Element
            OA_rp_CS_MemAbsSet_Set_BsShare_VisteonPartNumber: operation=rp_CS_MemAbsSet.Set_BsShare_VisteonPartNumber
            OA_rp_CS_MemAbsSet_Set_BsShare_VisteonPCBPartNumber: operation=rp_CS_MemAbsSet.Set_BsShare_VisteonPCBPartNumber
            OA_rp_CS_MemAbsSet_Set_BsShare_ProductSerialNumber: operation=rp_CS_MemAbsSet.Set_BsShare_ProductSerialNumber
            OA_rp_CS_MemAbsSet_Set_BsShare_PCBSerialNumber: operation=rp_CS_MemAbsSet.Set_BsShare_PCBSerialNumber
            OA_rp_CS_MemAbsSet_Set_BsShare_SMTManufacturingDate: operation=rp_CS_MemAbsSet.Set_BsShare_SMTManufacturingDate
            OA_rp_CS_MemAbsSet_Set_BsShare_AssemblyManufacturingDate: operation=rp_CS_MemAbsSet.Set_BsShare_AssemblyManufacturingDate
            OA_rp_CS_MemAbsSet_Set_BsShare_SMTPlantNumber: operation=rp_CS_MemAbsSet.Set_BsShare_SMTPlantNumber
            OA_rp_CS_MemAbsSet_Set_BsShare_AssemblyPlantNumber: operation=rp_CS_MemAbsSet.Set_BsShare_AssemblyPlantNumber
            OA_rp_CS_MemAbsSet_Set_BsShare_HWModification: operation=rp_CS_MemAbsSet.Set_BsShare_HWModification
            OA_rp_CS_MemAbsSet_Set_BsShare_VisMeet_Element: operation=rp_CS_MemAbsSet.Set_BsShare_VisMeet_Element
            OA_rp_CS_MemAbsSet_Set_BsShare_VisMeet_EOLEntry_Element: operation=rp_CS_MemAbsSet.Set_BsShare_VisMeet_EOLEntry_Element
            OA_rp_CS_MemAbsSet_Set_BsShare_VehicleConfig_Element: operation=rp_CS_MemAbsSet.Set_BsShare_VehicleConfig_Element
            OA_rp_CS_MemAbsSet_Set_BsConst_SpeedoGauge_Element: operation=rp_CS_MemAbsSet.Set_BsConst_SpeedoGauge_Element
            OA_rp_CS_MemAbsSet_Set_BsConst_TachoGauge_Element: operation=rp_CS_MemAbsSet.Set_BsConst_TachoGauge_Element
            OA_rp_CS_MemAbsSet_Set_BsConst_FuelGauge_Element: operation=rp_CS_MemAbsSet.Set_BsConst_FuelGauge_Element
            OA_rp_CS_MemAbsSet_Set_BsConst_TempGauge_Element: operation=rp_CS_MemAbsSet.Set_BsConst_TempGauge_Element
            OA_rp_CS_MemAbsSet_Set_BsConst_PowerGauge_Element: operation=rp_CS_MemAbsSet.Set_BsConst_PowerGauge_Element
            OA_rp_CS_MemAbsSet_Set_BsConst_OilGauge_Element: operation=rp_CS_MemAbsSet.Set_BsConst_OilGauge_Element
            OA_rp_CS_MemAbsSet_Set_BsConst_TripComputer_Element: operation=rp_CS_MemAbsSet.Set_BsConst_TripComputer_Element
            OA_rp_CS_MemAbsSet_Set_BsConst_Compensation_Line_Slope_m: operation=rp_CS_MemAbsSet.Set_BsConst_Compensation_Line_Slope_m
            OA_rp_CS_MemAbsSet_Set_BsConst_Compensation_Line_Shift_b: operation=rp_CS_MemAbsSet.Set_BsConst_Compensation_Line_Shift_b
            OA_rp_CS_MemAbsSet_Set_BsConst_Lookup_Curve_HotSpot_Coef_X: operation=rp_CS_MemAbsSet.Set_BsConst_Lookup_Curve_HotSpot_Coef_X
            OA_rp_CS_MemAbsSet_Set_BsConst_Lookup_Curve_HotSpot_Coef_Y: operation=rp_CS_MemAbsSet.Set_BsConst_Lookup_Curve_HotSpot_Coef_Y
            OA_rp_CS_MemAbsSet_Set_BsConst_Temp_Threshold_Hysteresis_Derating: operation=rp_CS_MemAbsSet.Set_BsConst_Temp_Threshold_Hysteresis_Derating
            OA_rp_CS_MemAbsSet_Set_BsConst_Derating_Backlight_Disable: operation=rp_CS_MemAbsSet.Set_BsConst_Derating_Backlight_Disable
            OA_rp_CS_MemAbsSet_Set_BsConst_Temperature_Sensor_Conv: operation=rp_CS_MemAbsSet.Set_BsConst_Temperature_Sensor_Conv
            OA_rp_CS_MemAbsSet_Set_BsConst_PCB_Temperature_Sensor_Conv: operation=rp_CS_MemAbsSet.Set_BsConst_PCB_Temperature_Sensor_Conv
            OA_rp_CS_MemAbsSet_Set_BsConst_Display_Illum_Max_Level: operation=rp_CS_MemAbsSet.Set_BsConst_Display_Illum_Max_Level
            OA_rp_CS_MemAbsSet_Set_BsConst_PWM_boost_bypass_duty: operation=rp_CS_MemAbsSet.Set_BsConst_PWM_boost_bypass_duty
            OA_rp_CS_MemAbsSet_Set_BsConst_BsConst_Illumination_ReservedByte: operation=rp_CS_MemAbsSet.Set_BsConst_BsConst_Illumination_ReservedByte
            OA_rp_CS_MemAbsSet_Set_BsConst_Compensation_Line_Slope_m_SafeCopy1: operation=rp_CS_MemAbsSet.Set_BsConst_Compensation_Line_Slope_m_SafeCopy1
            OA_rp_CS_MemAbsSet_Set_BsConst_Compensation_Line_Shift_b_SafeCopy1: operation=rp_CS_MemAbsSet.Set_BsConst_Compensation_Line_Shift_b_SafeCopy1
            OA_rp_CS_MemAbsSet_Set_BsConst_Lookup_Curve_HotSpot_Coef_X_SafeCopy1: operation=rp_CS_MemAbsSet.Set_BsConst_Lookup_Curve_HotSpot_Coef_X_SafeCopy1
            OA_rp_CS_MemAbsSet_Set_BsConst_Lookup_Curve_HotSpot_Coef_Y_SafeCopy1: operation=rp_CS_MemAbsSet.Set_BsConst_Lookup_Curve_HotSpot_Coef_Y_SafeCopy1
            OA_rp_CS_MemAbsSet_Set_BsConst_Temp_Threshold_Hysteresis_Derating_SafeCopy1: operation=rp_CS_MemAbsSet.Set_BsConst_Temp_Threshold_Hysteresis_Derating_SafeCopy1
            OA_rp_CS_MemAbsSet_Set_BsConst_Derating_Backlight_Disable_SafeCopy1: operation=rp_CS_MemAbsSet.Set_BsConst_Derating_Backlight_Disable_SafeCopy1
            OA_rp_CS_MemAbsSet_Set_BsConst_Temperature_Sensor_Conv_SafeCopy1: operation=rp_CS_MemAbsSet.Set_BsConst_Temperature_Sensor_Conv_SafeCopy1
            OA_rp_CS_MemAbsSet_Set_BsConst_PCB_Temperature_Sensor_Conv_SafeCopy1: operation=rp_CS_MemAbsSet.Set_BsConst_PCB_Temperature_Sensor_Conv_SafeCopy1
            OA_rp_CS_MemAbsSet_Set_BsConst_Display_Illum_Max_Level_SafeCopy1: operation=rp_CS_MemAbsSet.Set_BsConst_Display_Illum_Max_Level_SafeCopy1
            OA_rp_CS_MemAbsSet_Set_BsConst_PWM_boost_bypass_duty_SafeCopy1: operation=rp_CS_MemAbsSet.Set_BsConst_PWM_boost_bypass_duty_SafeCopy1
            OA_rp_CS_MemAbsSet_Set_BsConst_BsConst_Illumination_ReservedByte_SafeCopy1: operation=rp_CS_MemAbsSet.Set_BsConst_BsConst_Illumination_ReservedByte_SafeCopy1
            OA_rp_CS_MemAbsSet_Set_BsConst_Compensation_Line_Slope_m_SafeCopy2: operation=rp_CS_MemAbsSet.Set_BsConst_Compensation_Line_Slope_m_SafeCopy2
            OA_rp_CS_MemAbsSet_Set_BsConst_Compensation_Line_Shift_b_SafeCopy2: operation=rp_CS_MemAbsSet.Set_BsConst_Compensation_Line_Shift_b_SafeCopy2
            OA_rp_CS_MemAbsSet_Set_BsConst_Lookup_Curve_HotSpot_Coef_X_SafeCopy2: operation=rp_CS_MemAbsSet.Set_BsConst_Lookup_Curve_HotSpot_Coef_X_SafeCopy2
            OA_rp_CS_MemAbsSet_Set_BsConst_Lookup_Curve_HotSpot_Coef_Y_SafeCopy2: operation=rp_CS_MemAbsSet.Set_BsConst_Lookup_Curve_HotSpot_Coef_Y_SafeCopy2
            OA_rp_CS_MemAbsSet_Set_BsConst_Temp_Threshold_Hysteresis_Derating_SafeCopy2: operation=rp_CS_MemAbsSet.Set_BsConst_Temp_Threshold_Hysteresis_Derating_SafeCopy2
            OA_rp_CS_MemAbsSet_Set_BsConst_Derating_Backlight_Disable_SafeCopy2: operation=rp_CS_MemAbsSet.Set_BsConst_Derating_Backlight_Disable_SafeCopy2
            OA_rp_CS_MemAbsSet_Set_BsConst_Temperature_Sensor_Conv_SafeCopy2: operation=rp_CS_MemAbsSet.Set_BsConst_Temperature_Sensor_Conv_SafeCopy2
            OA_rp_CS_MemAbsSet_Set_BsConst_PCB_Temperature_Sensor_Conv_SafeCopy2: operation=rp_CS_MemAbsSet.Set_BsConst_PCB_Temperature_Sensor_Conv_SafeCopy2
            OA_rp_CS_MemAbsSet_Set_BsConst_Display_Illum_Max_Level_SafeCopy2: operation=rp_CS_MemAbsSet.Set_BsConst_Display_Illum_Max_Level_SafeCopy2
            OA_rp_CS_MemAbsSet_Set_BsConst_PWM_boost_bypass_duty_SafeCopy2: operation=rp_CS_MemAbsSet.Set_BsConst_PWM_boost_bypass_duty_SafeCopy2
            OA_rp_CS_MemAbsSet_Set_BsConst_BsConst_Illumination_ReservedByte_SafeCopy2: operation=rp_CS_MemAbsSet.Set_BsConst_BsConst_Illumination_ReservedByte_SafeCopy2
            OA_rp_CS_MemAbsSet_Set_BsConst_Audio_Element: operation=rp_CS_MemAbsSet.Set_BsConst_Audio_Element
            OA_rp_CS_MemAbsSet_Set_BsConst_Warning_Element: operation=rp_CS_MemAbsSet.Set_BsConst_Warning_Element
            OA_rp_CS_MemAbsSet_Set_BsConst_RealTimeClock_Element: operation=rp_CS_MemAbsSet.Set_BsConst_RealTimeClock_Element
            OA_rp_CS_MemAbsSet_Set_BsConst_Communication_Element: operation=rp_CS_MemAbsSet.Set_BsConst_Communication_Element
            OA_rp_CS_MemAbsSet_Set_BsConst_Power_Element: operation=rp_CS_MemAbsSet.Set_BsConst_Power_Element
            OA_rp_CS_MemAbsSet_Set_BsConst_ServiceReminder_Element: operation=rp_CS_MemAbsSet.Set_BsConst_ServiceReminder_Element
            OA_rp_CS_MemAbsSet_Set_BsConst_EngOffTimer_Element: operation=rp_CS_MemAbsSet.Set_BsConst_EngOffTimer_Element
            OA_rp_CS_MemAbsSet_Set_BsCys_Certicificate_Element: operation=rp_CS_MemAbsSet.Set_BsCys_Certicificate_Element
            OA_rp_CS_MemAbsSet_Set_RefCys_Certicificate_Element: operation=rp_CS_MemAbsSet.Set_RefCys_Certicificate_Element
            OA_rp_CS_MemAbsSet_Set_RefCys_Certicificate1_Element: operation=rp_CS_MemAbsSet.Set_RefCys_Certicificate1_Element
            OA_rp_CS_MemAbsSet_Set_BsRt_Odometer_Element: operation=rp_CS_MemAbsSet.Set_BsRt_Odometer_Element
            OA_rp_CS_MemAbsSet_Set_BsRt_SpeedoGauge_Element: operation=rp_CS_MemAbsSet.Set_BsRt_SpeedoGauge_Element
            OA_rp_CS_MemAbsSet_Set_BsRt_TachoGauge_Element: operation=rp_CS_MemAbsSet.Set_BsRt_TachoGauge_Element
            OA_rp_CS_MemAbsSet_Set_BsRt_FuelGauge_Element: operation=rp_CS_MemAbsSet.Set_BsRt_FuelGauge_Element
            OA_rp_CS_MemAbsSet_Set_BsRt_TempGauge_Element: operation=rp_CS_MemAbsSet.Set_BsRt_TempGauge_Element
            OA_rp_CS_MemAbsSet_Set_BsRt_PowerGauge_Element: operation=rp_CS_MemAbsSet.Set_BsRt_PowerGauge_Element
            OA_rp_CS_MemAbsSet_Set_BsRt_OilGauge_Element: operation=rp_CS_MemAbsSet.Set_BsRt_OilGauge_Element
            OA_rp_CS_MemAbsSet_Set_BsRt_TripComputer_Element: operation=rp_CS_MemAbsSet.Set_BsRt_TripComputer_Element
            OA_rp_CS_MemAbsSet_Set_BsRt_Warning_Element: operation=rp_CS_MemAbsSet.Set_BsRt_Warning_Element
            OA_rp_CS_MemAbsSet_Set_BsRt_RealTimeClock_Element: operation=rp_CS_MemAbsSet.Set_BsRt_RealTimeClock_Element
            OA_rp_CS_MemAbsSet_Set_BsRt_Personalization_Element: operation=rp_CS_MemAbsSet.Set_BsRt_Personalization_Element
            OA_rp_CS_MemAbsSet_Set_BsRt_Illumination_Element: operation=rp_CS_MemAbsSet.Set_BsRt_Illumination_Element
            OA_rp_CS_MemAbsSet_Set_BsRt_CusDlt_Element: operation=rp_CS_MemAbsSet.Set_BsRt_CusDlt_Element
            OA_rp_CS_MemAbsSet_Set_BsReten_Odometer_Element: operation=rp_CS_MemAbsSet.Set_BsReten_Odometer_Element
            OA_rp_CS_MemAbsSet_Set_BsReten_Gauges_Element: operation=rp_CS_MemAbsSet.Set_BsReten_Gauges_Element
            OA_rp_CS_MemAbsSet_Set_BsReten_Tripcomputer_Element: operation=rp_CS_MemAbsSet.Set_BsReten_Tripcomputer_Element
            OA_rp_CS_MemAbsSet_Set_BsReten_Illumination_Element: operation=rp_CS_MemAbsSet.Set_BsReten_Illumination_Element
            OA_rp_CS_MemAbsSet_Set_BsReten_Audio_Element: operation=rp_CS_MemAbsSet.Set_BsReten_Audio_Element
            OA_rp_CS_MemAbsSet_Set_BsReten_Warning_Element: operation=rp_CS_MemAbsSet.Set_BsReten_Warning_Element
            OA_rp_CS_MemAbsSet_Set_BsReten_RealTimeClock_Element: operation=rp_CS_MemAbsSet.Set_BsReten_RealTimeClock_Element
            OA_rp_CS_MemAbsSet_Set_BsReten_Communication_Element: operation=rp_CS_MemAbsSet.Set_BsReten_Communication_Element
            OA_rp_CS_MemAbsSet_Set_BsReten_Personalization_Element: operation=rp_CS_MemAbsSet.Set_BsReten_Personalization_Element
            OA_rp_CS_MemAbsSet_Set_BsReten_Power_Element: operation=rp_CS_MemAbsSet.Set_BsReten_Power_Element
            OA_rp_CS_MemAbsSet_Set_BsReten_Display_Element: operation=rp_CS_MemAbsSet.Set_BsReten_Display_Element
            OA_rp_CS_MemAbsSet_Set_BsDiag_ErrorRecord_Element: operation=rp_CS_MemAbsSet.Set_BsDiag_ErrorRecord_Element
            OA_rp_CS_MemAbsSet_Set_BsDiag_Dtc_Element: operation=rp_CS_MemAbsSet.Set_BsDiag_Dtc_Element
            OA_rp_CS_RID_App_DiagAction_RID_DiagAction: operation=rp_CS_RID_App_DiagAction.RID_DiagAction
            OA_rp_CS_RID_DiagAction_RID_DiagAction: operation=rp_CS_RID_DiagAction.RID_DiagAction
            OA_rp_CS_UpdateCdd_DID_DiagAction_UpdateCdd_GenericDIDRequestHandler: operation=rp_CS_UpdateCdd_DID_DiagAction.UpdateCdd_GenericDIDRequestHandler
            OA_rp_CS_UpdateCdd_RID_DiagAction_UpdateCdd_GenericRIDRequestHandler: operation=rp_CS_UpdateCdd_RID_DiagAction.UpdateCdd_GenericRIDRequestHandler
            OA_rp_CS_UpdateCdd_Service_0x10_Handler_UpdateCdd_GenericProgSessionRequest: operation=rp_CS_UpdateCdd_Service_0x10_Handler.UpdateCdd_GenericProgSessionRequest
            OA_rp_CS_UpdateCdd_Service_0x34_Handler_UpdateCdd_GenericRequestDownloadHandler: operation=rp_CS_UpdateCdd_Service_0x34_Handler.UpdateCdd_GenericRequestDownloadHandler
            OA_rp_CS_UpdateCdd_Service_0x36_Handler_UpdateCdd_GenericTransferDataHandler: operation=rp_CS_UpdateCdd_Service_0x36_Handler.UpdateCdd_GenericTransferDataHandler
            OA_rp_CS_UpdateCdd_Service_0x37_Handler_UpdateCdd_GenericTransferExitHandler: operation=rp_CS_UpdateCdd_Service_0x37_Handler.UpdateCdd_GenericTransferExitHandler
